VERSION ""

NS_ :

BS_:

BU_: CHUD_LS VKM_LS RCRM_LS MSM_RR_LS MSM_LR_LS CGM_LS BSM_LS VPM_LS ISRVM_LS DCAC_LS TouchPad_LS RSC_LS LVMPC_LS EOCM2B_K1_LS EOCM2A_K1_LS LCM_LS TIM_B_LS V2V_LS TCP_LS CSM_LS EOCM2B_K2_LS EOCM2A_K2_LS TIM_A_LS LVMNav_LS HFP_LS EDI_LS ARB_LS RSE_LS Dummy_LS VIS2_LS ICS_LS FCM_LS EOCM_F_LS VICM_LS AGC_LS MSM_P_LS OTIM_LS HVSM_R_LS HVSM_F_LS DVB_T_LS SBZA_R_LS PSD_R_LS PSD_L_LS UHP_Low UPA_LS STC_LS SBZA_L_LS PTM_LS ONSTAR_LS APA_LS TestTool_LS PHS_LS PDIM_LS CHM_LS RSA_LS AMP_LS HUD_LS MSM_LS HBSM_LS SCL_LS ECC_LS RadioHead_LS PEPS_LS IPC_LS AOS_LS SDM_LS TIM_LS BCM_LS

BO_ 2158936064 ODIEnumDynamicData_LS: 8 ECC_LS
 SG_ ODIEDD_Data18Value : 50|3@0+ (1,0) [0|7] ""  CSM_LS,CGM_LS,TCP_LS,OTIM_LS,ONSTAR_LS,IPC_LS,CHUD_LS,HUD_LS,RadioHead_LS
 SG_ ODIEDD_Data17Value : 53|3@0+ (1,0) [0|7] ""  CSM_LS,CGM_LS,TCP_LS,OTIM_LS,ONSTAR_LS,IPC_LS,CHUD_LS,HUD_LS,RadioHead_LS
 SG_ ODIEDD_Data16Value : 40|3@0+ (1,0) [0|7] ""  CSM_LS,CGM_LS,TCP_LS,OTIM_LS,ONSTAR_LS,IPC_LS,CHUD_LS,HUD_LS,RadioHead_LS
 SG_ ODIEDD_Data15Value : 43|3@0+ (1,0) [0|7] ""  CSM_LS,CGM_LS,TCP_LS,OTIM_LS,ONSTAR_LS,IPC_LS,CHUD_LS,HUD_LS,RadioHead_LS
 SG_ ODIEDD_Data14Value : 46|3@0+ (1,0) [0|7] ""  CSM_LS,CGM_LS,TCP_LS,OTIM_LS,ONSTAR_LS,IPC_LS,CHUD_LS,HUD_LS,RadioHead_LS
 SG_ ODIEDD_Data13Value : 33|3@0+ (1,0) [0|7] ""  CSM_LS,CGM_LS,TCP_LS,OTIM_LS,ONSTAR_LS,IPC_LS,CHUD_LS,HUD_LS,RadioHead_LS
 SG_ ODIEDD_Data12Value : 36|3@0+ (1,0) [0|7] ""  CSM_LS,CGM_LS,TCP_LS,OTIM_LS,ONSTAR_LS,IPC_LS,CHUD_LS,HUD_LS,RadioHead_LS
 SG_ ODIEDD_Data11Value : 39|3@0+ (1,0) [0|7] ""  CSM_LS,CGM_LS,TCP_LS,OTIM_LS,ONSTAR_LS,IPC_LS,CHUD_LS,HUD_LS,RadioHead_LS
 SG_ ODIEDD_Data10Value : 26|3@0+ (1,0) [0|7] ""  CSM_LS,CGM_LS,TCP_LS,OTIM_LS,ONSTAR_LS,IPC_LS,CHUD_LS,HUD_LS,RadioHead_LS
 SG_ ODIEDD_Data9Value : 29|3@0+ (1,0) [0|7] ""  CSM_LS,CGM_LS,TCP_LS,OTIM_LS,ONSTAR_LS,IPC_LS,CHUD_LS,HUD_LS,RadioHead_LS
 SG_ ODIEDD_Data8Value : 16|3@0+ (1,0) [0|7] ""  CSM_LS,CGM_LS,TCP_LS,OTIM_LS,ONSTAR_LS,IPC_LS,CHUD_LS,HUD_LS,RadioHead_LS
 SG_ ODIEDD_Data7Value : 19|3@0+ (1,0) [0|7] ""  CSM_LS,CGM_LS,TCP_LS,OTIM_LS,ONSTAR_LS,IPC_LS,CHUD_LS,HUD_LS,RadioHead_LS
 SG_ ODIEDD_Data6Value : 22|3@0+ (1,0) [0|7] ""  CSM_LS,CGM_LS,TCP_LS,OTIM_LS,ONSTAR_LS,IPC_LS,CHUD_LS,HUD_LS,RadioHead_LS
 SG_ ODIEDD_Data5Value : 9|3@0+ (1,0) [0|7] ""  CSM_LS,CGM_LS,TCP_LS,OTIM_LS,ONSTAR_LS,IPC_LS,CHUD_LS,HUD_LS,RadioHead_LS
 SG_ ODIEDD_Data4Value : 12|3@0+ (1,0) [0|7] ""  CSM_LS,CGM_LS,TCP_LS,OTIM_LS,ONSTAR_LS,IPC_LS,CHUD_LS,HUD_LS,RadioHead_LS
 SG_ ODIEDD_Data3Value : 15|3@0+ (1,0) [0|7] ""  CSM_LS,CGM_LS,TCP_LS,OTIM_LS,ONSTAR_LS,IPC_LS,CHUD_LS,HUD_LS,RadioHead_LS
 SG_ ODIEDD_Data2Value : 2|3@0+ (1,0) [0|7] ""  CSM_LS,CGM_LS,TCP_LS,OTIM_LS,ONSTAR_LS,IPC_LS,CHUD_LS,HUD_LS,RadioHead_LS
 SG_ ODIEDD_Data1Value : 5|3@0+ (1,0) [0|7] ""  CSM_LS,CGM_LS,TCP_LS,OTIM_LS,ONSTAR_LS,IPC_LS,CHUD_LS,HUD_LS,RadioHead_LS
 SG_ ODIEDD_FUCID : 63|8@0+ (1,0) [0|255] ""  CSM_LS,CGM_LS,TCP_LS,OTIM_LS,ONSTAR_LS,IPC_LS,CHUD_LS,HUD_LS,RadioHead_LS

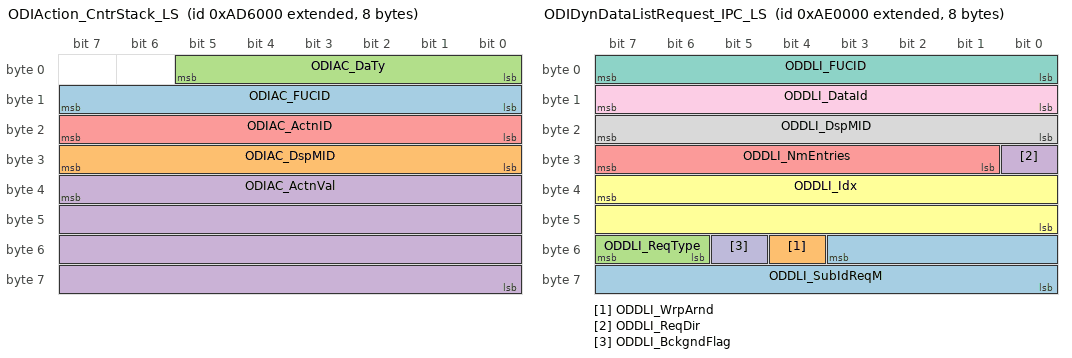
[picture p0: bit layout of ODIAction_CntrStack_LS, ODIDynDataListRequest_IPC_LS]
BO_ 2158845952 ODIAction_CntrStack_LS: 8 CGM_LS
 SG_ ODIAC_FUCID : 15|8@0+ (1,0) [0|255] ""  EOCM2B_K2_LS,EOCM2A_K2_LS,TCP_LS,SBZA_L_LS,VIS2_LS,FCM_LS,PDIM_LS,EOCM_F_LS,UPA_LS,BCM_LS,ECC_LS,MSM_P_LS,MSM_LS,APA_LS,UHP_Low,ONSTAR_LS
 SG_ ODIAC_DspMID : 31|8@0+ (1,0) [0|255] ""  EOCM2B_K2_LS,EOCM2A_K2_LS,TCP_LS,SBZA_L_LS,VIS2_LS,FCM_LS,PDIM_LS,EOCM_F_LS,UPA_LS,BCM_LS,ECC_LS,MSM_P_LS,MSM_LS,APA_LS,UHP_Low,ONSTAR_LS
 SG_ ODIAC_DaTy : 5|6@0+ (1,0) [0|63] ""  EOCM2B_K2_LS,EOCM2A_K2_LS,TCP_LS,SBZA_L_LS,VIS2_LS,FCM_LS,PDIM_LS,EOCM_F_LS,UPA_LS,BCM_LS,ECC_LS,MSM_P_LS,MSM_LS,APA_LS,UHP_Low,ONSTAR_LS
 SG_ ODIAC_ActnVal : 39|32@0+ (1,0) [0|4294967295] ""  EOCM2B_K2_LS,EOCM2A_K2_LS,TCP_LS,SBZA_L_LS,VIS2_LS,FCM_LS,PDIM_LS,EOCM_F_LS,UPA_LS,BCM_LS,ECC_LS,MSM_P_LS,MSM_LS,APA_LS,UHP_Low,ONSTAR_LS
 SG_ ODIAC_ActnID : 23|8@0+ (1,0) [0|255] ""  EOCM2B_K2_LS,EOCM2A_K2_LS,TCP_LS,SBZA_L_LS,VIS2_LS,FCM_LS,PDIM_LS,EOCM_F_LS,UPA_LS,BCM_LS,ECC_LS,MSM_P_LS,MSM_LS,APA_LS,UHP_Low,ONSTAR_LS

BO_ 2158886912 ODIDynDataListRequest_IPC_LS: 8 IPC_LS
 SG_ ODDLI_SubIdReqM : 51|12@0+ (1,0) [0|4095] ""  TCP_LS,VIS2_LS,FCM_LS,RadioHead_LS,UHP_Low,ONSTAR_LS
 SG_ ODDLI_WrpArnd : 52|1@0+ (1,0) [0|1] ""  TCP_LS,VIS2_LS,FCM_LS,RadioHead_LS,UHP_Low,ONSTAR_LS
 SG_ ODDLI_ReqType : 55|2@0+ (1,0) [0|3] ""  TCP_LS,VIS2_LS,FCM_LS,RadioHead_LS,UHP_Low,ONSTAR_LS
 SG_ ODDLI_ReqDir : 24|1@0+ (1,0) [0|1] ""  TCP_LS,VIS2_LS,FCM_LS,RadioHead_LS,UHP_Low,ONSTAR_LS
 SG_ ODDLI_NmEntries : 31|7@0+ (1,0) [0|127] ""  TCP_LS,VIS2_LS,FCM_LS,RadioHead_LS,UHP_Low,ONSTAR_LS
 SG_ ODDLI_Idx : 39|16@0+ (1,0) [0|65535] ""  TCP_LS,VIS2_LS,FCM_LS,RadioHead_LS,UHP_Low,ONSTAR_LS
 SG_ ODDLI_FUCID : 7|8@0+ (1,0) [0|255] ""  TCP_LS,VIS2_LS,FCM_LS,RadioHead_LS,UHP_Low,ONSTAR_LS
 SG_ ODDLI_DspMID : 23|8@0+ (1,0) [0|255] ""  TCP_LS,VIS2_LS,FCM_LS,RadioHead_LS,UHP_Low,ONSTAR_LS
 SG_ ODDLI_DataId : 15|8@0+ (1,0) [0|255] ""  TCP_LS,VIS2_LS,FCM_LS,RadioHead_LS,UHP_Low,ONSTAR_LS
 SG_ ODDLI_BckgndFlag : 53|1@0+ (1,0) [0|1] ""  TCP_LS,VIS2_LS,FCM_LS,RadioHead_LS,UHP_Low,ONSTAR_LS

BO_ 1596 VNMF_LS_63C_SCL: 8 SCL_LS
 SG_ VectraSpcNWMgtD : 7|64@0+ (1,0) [0|1.84467440737096E+019] ""  TCP_LS,LVMNav_LS,UHP_Low,ONSTAR_LS,TIM_B_LS,RSE_LS,RSA_LS,HVSM_F_LS,MSM_LS,BCM_LS,AOS_LS,AMP_LS,BSM_LS,VICM_LS,HFP_LS,PDIM_LS,SBZA_R_LS,TestTool_LS,MSM_LR_LS,LCM_LS,HVSM_R_LS,EOCM2A_K2_LS,FCM_LS,EOCM_F_LS,EOCM2B_K2_LS,PHS_LS,ICS_LS,CGM_LS,TIM_LS,SBZA_L_LS,CSM_LS,CHM_LS,RadioHead_LS,STC_LS,PTM_LS,VKM_LS,RSC_LS,PSD_R_LS,DCAC_LS,AGC_LS,TIM_A_LS,VIS2_LS,SDM_LS,CHUD_LS,MSM_RR_LS,LVMPC_LS,PSD_L_LS,PEPS_LS,IPC_LS,VPM_LS,HUD_LS,RCRM_LS,ISRVM_LS,HBSM_LS,ECC_LS,TouchPad_LS,DVB_T_LS,UPA_LS,APA_LS,V2V_LS,ARB_LS,MSM_P_LS,OTIM_LS

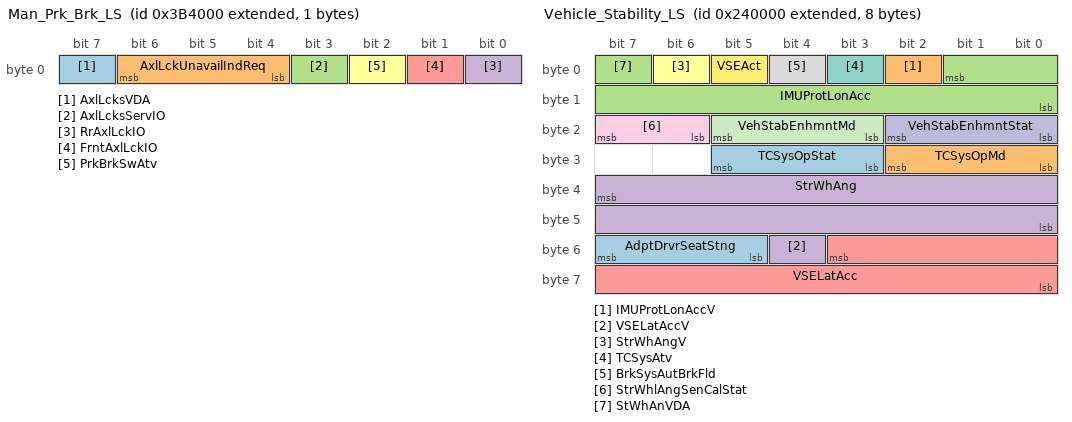
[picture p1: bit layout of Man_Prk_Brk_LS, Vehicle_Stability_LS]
BO_ 2151366656 Man_Prk_Brk_LS: 1 BCM_LS
 SG_ AxlLcksVDA : 7|1@0+ (1,0) [0|1] ""  CGM_LS,IPC_LS
 SG_ AxlLckUnavailIndReq : 6|3@0+ (1,0) [0|7] ""  CGM_LS,IPC_LS
 SG_ AxlLcksServIO : 3|1@0+ (1,0) [0|1] ""  CGM_LS,IPC_LS
 SG_ RrAxlLckIO : 0|1@0+ (1,0) [0|1] ""  CGM_LS,IPC_LS
 SG_ FrntAxlLckIO : 1|1@0+ (1,0) [0|1] ""  CGM_LS,IPC_LS
 SG_ PrkBrkSwAtv : 2|1@0+ (1,0) [0|1] ""  ONSTAR_LS,TCP_LS,CSM_LS,MSM_P_LS,MSM_LS,V2V_LS,CGM_LS,RadioHead_LS,SBZA_R_LS,LVMNav_LS,SBZA_L_LS,IPC_LS,UPA_LS,APA_LS

BO_ 2149842944 Vehicle_Stability_LS: 8 BCM_LS
 SG_ AdptDrvrSeatStng : 55|3@0+ (1,0) [0|7] ""  CGM_LS,MSM_LS
 SG_ IMUProtLonAccV : 2|1@0+ (1,0) [0|1] ""  CSM_LS,VIS2_LS,UPA_LS,APA_LS,FCM_LS,RadioHead_LS,IPC_LS,LCM_LS,PTM_LS,CGM_LS
 SG_ IMUProtLonAcc : 1|10@0- (0.03,0) [-15.36|15.33] "m/s^2"  CSM_LS,VIS2_LS,UPA_LS,APA_LS,FCM_LS,RadioHead_LS,IPC_LS,LCM_LS,PTM_LS,CGM_LS
 SG_ VSELatAccV : 52|1@0+ (1,0) [0|1] ""  CGM_LS,CSM_LS,VIS2_LS,RadioHead_LS,CHUD_LS,HUD_LS,IPC_LS,FCM_LS
 SG_ VSELatAcc : 51|12@0- (0.015625,0) [-32|31.984375] "m/s^2"  CGM_LS,CSM_LS,VIS2_LS,RadioHead_LS,CHUD_LS,HUD_LS,IPC_LS,FCM_LS
 SG_ StrWhAngV : 6|1@0+ (1,0) [0|1] ""  CGM_LS,VIS2_LS,VPM_LS,SBZA_R_LS,SBZA_L_LS,FCM_LS,UPA_LS,APA_LS,CSM_LS,RadioHead_LS
 SG_ TCSysAtv : 3|1@0+ (1,0) [0|1] ""  CSM_LS,CGM_LS,VIS2_LS,RadioHead_LS,APA_LS,FCM_LS,IPC_LS
 SG_ BrkSysAutBrkFld : 4|1@0+ (1,0) [0|1] ""  CSM_LS,CGM_LS,RadioHead_LS,IPC_LS
 SG_ StrWhlAngSenCalStat : 23|2@0+ (1,0) [0|3] ""  CGM_LS,VPM_LS,VIS2_LS,FCM_LS,CSM_LS,RadioHead_LS,UPA_LS,APA_LS
 SG_ VehStabEnhmntStat : 18|3@0+ (1,0) [0|7] ""  CSM_LS,CGM_LS,RadioHead_LS,APA_LS,IPC_LS
 SG_ VehStabEnhmntMd : 21|3@0+ (1,0) [0|7] ""  CSM_LS,CGM_LS,RadioHead_LS,IPC_LS
 SG_ VSEAct : 5|1@0+ (1,0) [0|1] ""  CGM_LS,CSM_LS,VIS2_LS,EOCM_F_LS,RadioHead_LS,FCM_LS,APA_LS,IPC_LS
 SG_ TCSysOpStat : 29|3@0+ (1,0) [0|7] ""  CSM_LS,CGM_LS,RadioHead_LS,APA_LS,IPC_LS
 SG_ TCSysOpMd : 26|3@0+ (1,0) [0|7] ""  CSM_LS,CGM_LS,RadioHead_LS,IPC_LS
 SG_ StWhAnVDA : 7|1@0+ (1,0) [0|1] ""  CGM_LS,VIS2_LS,VPM_LS,UPA_LS,APA_LS,FCM_LS,CSM_LS,RadioHead_LS
 SG_ StrWhAng : 39|16@0- (0.0625,0) [-2048|2047.9375] "deg"  CGM_LS,VIS2_LS,VPM_LS,SBZA_R_LS,SBZA_L_LS,CSM_LS,RadioHead_LS,FCM_LS,UPA_LS,APA_LS

BO_ 1603 USDT_Resp_From_AGC_LS: 8 AGC_LS
 SG_ DgnInf : 7|64@0+ (1,0) [0|1.84467440737096E+019] ""  CSM_LS,CGM_LS,TCP_LS,ONSTAR_LS,TestTool_LS

BO_ 1574 VNMF_LS_626_ICS: 8 ICS_LS
 SG_ VectraSpcNWMgtD : 7|64@0+ (1,0) [0|1.84467440737096E+019] ""  HFP_LS,PDIM_LS,TCP_LS,LVMNav_LS,UHP_Low,ONSTAR_LS,TIM_B_LS,RSE_LS,RSA_LS,HVSM_F_LS,MSM_LS,BCM_LS,AOS_LS,AMP_LS,BSM_LS,VICM_LS,SBZA_R_LS,V2V_LS,ARB_LS,CGM_LS,TIM_LS,TestTool_LS,TIM_A_LS,VIS2_LS,SDM_LS,SCL_LS,SBZA_L_LS,CSM_LS,CHM_LS,RadioHead_LS,STC_LS,PTM_LS,VKM_LS,RSC_LS,PSD_R_LS,CHUD_LS,MSM_RR_LS,LVMPC_LS,PSD_L_LS,PEPS_LS,EOCM2A_K2_LS,FCM_LS,EOCM_F_LS,IPC_LS,MSM_LR_LS,LCM_LS,HVSM_R_LS,VPM_LS,HUD_LS,RCRM_LS,ISRVM_LS,HBSM_LS,ECC_LS,TouchPad_LS,DVB_T_LS,UPA_LS,APA_LS,DCAC_LS,AGC_LS,MSM_P_LS,OTIM_LS,EOCM2B_K2_LS,PHS_LS

BO_ 1571 VNMF_LS_623_AGC: 8 AGC_LS
 SG_ VectraSpcNWMgtD : 7|64@0+ (1,0) [0|1.84467440737096E+019] ""  TCP_LS,LVMNav_LS,UHP_Low,ONSTAR_LS,TIM_B_LS,RSE_LS,RSA_LS,HVSM_F_LS,MSM_LS,BCM_LS,AOS_LS,AMP_LS,BSM_LS,VICM_LS,HFP_LS,PDIM_LS,SBZA_R_LS,V2V_LS,ARB_LS,CGM_LS,TIM_LS,TestTool_LS,TIM_A_LS,VIS2_LS,SDM_LS,SCL_LS,SBZA_L_LS,CSM_LS,CHM_LS,RadioHead_LS,STC_LS,PTM_LS,VKM_LS,RSC_LS,PSD_R_LS,CHUD_LS,MSM_RR_LS,LVMPC_LS,PSD_L_LS,PEPS_LS,EOCM2A_K2_LS,FCM_LS,EOCM_F_LS,IPC_LS,MSM_LR_LS,LCM_LS,HVSM_R_LS,VPM_LS,HUD_LS,RCRM_LS,ISRVM_LS,HBSM_LS,ECC_LS,TouchPad_LS,DVB_T_LS,UPA_LS,APA_LS,ICS_LS,MSM_P_LS,OTIM_LS,EOCM2B_K2_LS,PHS_LS

BO_ 1347 UUDT_Resp_From_AGC_LS: 8 AGC_LS
 SG_ DgnInf_LS543 : 7|64@0+ (1,0) [0|1.84467440737096E+019] ""  CSM_LS,CGM_LS,TCP_LS,ONSTAR_LS,TestTool_LS

BO_ 582 USDT_Req_to_ICS_LS: 8 TestTool_LS
 SG_ DgnInf : 7|64@0+ (1,0) [0|1.84467440737096E+019] ""  TCP_LS,ONSTAR_LS,CGM_LS,ICS_LS

BO_ 579 USDT_Req_to_AGC_LS: 8 CGM_LS
 SG_ DgnInf : 7|64@0+ (1,0) [0|1.84467440737096E+019] ""  CGM_LS,TCP_LS,ONSTAR_LS,DCAC_LS,AGC_LS

BO_ 1577 VNMF_LS_629_OTIM_MSM_P: 8 OTIM_LS
 SG_ VectraSpcNWMgtD : 7|64@0+ (1,0) [0|1.84467440737096E+019] ""  TCP_LS,LVMNav_LS,UHP_Low,ONSTAR_LS,TIM_B_LS,RSE_LS,RSA_LS,HVSM_F_LS,MSM_LS,BCM_LS,AOS_LS,AMP_LS,BSM_LS,VICM_LS,HFP_LS,PDIM_LS,SBZA_R_LS,V2V_LS,ARB_LS,CGM_LS,TIM_LS,TestTool_LS,TIM_A_LS,VIS2_LS,SDM_LS,SCL_LS,SBZA_L_LS,CSM_LS,CHM_LS,RadioHead_LS,STC_LS,PTM_LS,VKM_LS,RSC_LS,PSD_R_LS,CHUD_LS,MSM_RR_LS,LVMPC_LS,PSD_L_LS,PEPS_LS,EOCM2A_K2_LS,FCM_LS,EOCM_F_LS,IPC_LS,MSM_LR_LS,LCM_LS,HVSM_R_LS,VPM_LS,HUD_LS,RCRM_LS,ISRVM_LS,HBSM_LS,ECC_LS,TouchPad_LS,DVB_T_LS,UPA_LS,APA_LS,DCAC_LS,AGC_LS,ICS_LS,EOCM2B_K2_LS,PHS_LS

BO_ 1609 USDT_Resp_From_OTIM_MSM_P_LS: 8 OTIM_LS
 SG_ DgnInf : 7|64@0+ (1,0) [0|1.84467440737096E+019] ""  CSM_LS,CGM_LS,TCP_LS,ONSTAR_LS,TestTool_LS

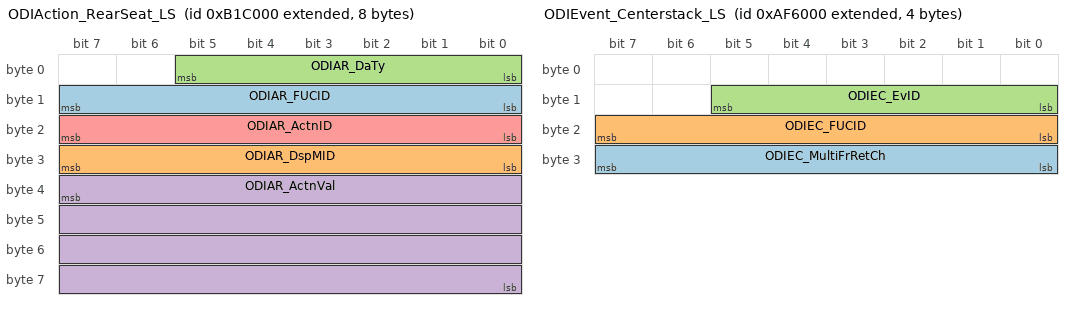
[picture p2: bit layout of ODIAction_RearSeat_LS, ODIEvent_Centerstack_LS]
BO_ 2159132672 ODIAction_RearSeat_LS: 8 RSA_LS
 SG_ ODIAR_FUCID : 15|8@0+ (1,0) [0|255] ""  ECC_LS,CSM_LS,RadioHead_LS
 SG_ ODIAR_DspMID : 31|8@0+ (1,0) [0|255] ""  ECC_LS,CSM_LS,RadioHead_LS
 SG_ ODIAR_DaTy : 5|6@0+ (1,0) [0|63] ""  ECC_LS,CSM_LS,RadioHead_LS
 SG_ ODIAR_ActnVal : 39|32@0+ (1,0) [0|4294967295] ""  ECC_LS,CSM_LS,RadioHead_LS
 SG_ ODIAR_ActnID : 23|8@0+ (1,0) [0|255] ""  ECC_LS,CSM_LS,RadioHead_LS

BO_ 2158968832 ODI_RearSeat_2_Centerstack_LS: 8 RSA_LS
 SG_ ODI_RSD2CntrStck : 7|64@0+ (1,0) [0|1.84467440737096E+019] ""  CGM_LS,CSM_LS,RadioHead_LS

BO_ 2158960640 ODIIndication_Centerstack_LS: 8 RadioHead_LS
 SG_ ODIIC_FUCID : 7|8@0+ (1,0) [0|255] ""  CGM_LS,CHUD_LS,HUD_LS,RSC_LS,RSA_LS
 SG_ ODIIC_ODIInd9 : 23|1@0+ (1,0) [0|1] ""  CGM_LS,CHUD_LS,HUD_LS,RSC_LS,RSA_LS
 SG_ ODIIC_ODIInd8 : 8|1@0+ (1,0) [0|1] ""  CGM_LS,CHUD_LS,HUD_LS,RSC_LS,RSA_LS
 SG_ ODIIC_ODIInd7 : 9|1@0+ (1,0) [0|1] ""  CGM_LS,CHUD_LS,HUD_LS,RSC_LS,RSA_LS
 SG_ ODIIC_ODIInd6 : 10|1@0+ (1,0) [0|1] ""  CGM_LS,CHUD_LS,HUD_LS,RSC_LS,RSA_LS
 SG_ ODIIC_ODIInd56 : 56|1@0+ (1,0) [0|1] ""  CGM_LS,CHUD_LS,HUD_LS,RSC_LS,RSA_LS
 SG_ ODIIC_ODIInd55 : 57|1@0+ (1,0) [0|1] ""  CGM_LS,CHUD_LS,HUD_LS,RSC_LS,RSA_LS
 SG_ ODIIC_ODIInd54 : 58|1@0+ (1,0) [0|1] ""  CGM_LS,CHUD_LS,HUD_LS,RSC_LS,RSA_LS
 SG_ ODIIC_ODIInd53 : 59|1@0+ (1,0) [0|1] ""  CGM_LS,CHUD_LS,HUD_LS,RSC_LS,RSA_LS
 SG_ ODIIC_ODIInd52 : 60|1@0+ (1,0) [0|1] ""  CGM_LS,CHUD_LS,HUD_LS,RSC_LS,RSA_LS
 SG_ ODIIC_ODIInd51 : 61|1@0+ (1,0) [0|1] ""  CGM_LS,CHUD_LS,HUD_LS,RSC_LS,RSA_LS
 SG_ ODIIC_ODIInd50 : 62|1@0+ (1,0) [0|1] ""  CGM_LS,CHUD_LS,HUD_LS,RSC_LS,RSA_LS
 SG_ ODIIC_ODIInd5 : 11|1@0+ (1,0) [0|1] ""  CGM_LS,CHUD_LS,HUD_LS,RSC_LS,RSA_LS
 SG_ ODIIC_ODIInd49 : 63|1@0+ (1,0) [0|1] ""  CGM_LS,CHUD_LS,HUD_LS,RSC_LS,RSA_LS
 SG_ ODIIC_ODIInd48 : 48|1@0+ (1,0) [0|1] ""  CGM_LS,CHUD_LS,HUD_LS,RSC_LS,RSA_LS
 SG_ ODIIC_ODIInd47 : 49|1@0+ (1,0) [0|1] ""  CGM_LS,CHUD_LS,HUD_LS,RSC_LS,RSA_LS
 SG_ ODIIC_ODIInd46 : 50|1@0+ (1,0) [0|1] ""  CGM_LS,CHUD_LS,HUD_LS,RSC_LS,RSA_LS
 SG_ ODIIC_ODIInd45 : 51|1@0+ (1,0) [0|1] ""  CGM_LS,CHUD_LS,HUD_LS,RSC_LS,RSA_LS
 SG_ ODIIC_ODIInd44 : 52|1@0+ (1,0) [0|1] ""  CGM_LS,CHUD_LS,HUD_LS,RSC_LS,RSA_LS
 SG_ ODIIC_ODIInd43 : 53|1@0+ (1,0) [0|1] ""  CGM_LS,CHUD_LS,HUD_LS,RSC_LS,RSA_LS
 SG_ ODIIC_ODIInd42 : 54|1@0+ (1,0) [0|1] ""  CGM_LS,CHUD_LS,HUD_LS,RSC_LS,RSA_LS
 SG_ ODIIC_ODIInd41 : 55|1@0+ (1,0) [0|1] ""  CGM_LS,CHUD_LS,HUD_LS,RSC_LS,RSA_LS
 SG_ ODIIC_ODIInd40 : 40|1@0+ (1,0) [0|1] ""  CGM_LS,CHUD_LS,HUD_LS,RSC_LS,RSA_LS
 SG_ ODIIC_ODIInd4 : 12|1@0+ (1,0) [0|1] ""  CGM_LS,CHUD_LS,HUD_LS,RSC_LS,RSA_LS
 SG_ ODIIC_ODIInd39 : 41|1@0+ (1,0) [0|1] ""  CGM_LS,CHUD_LS,HUD_LS,RSC_LS,RSA_LS
 SG_ ODIIC_ODIInd38 : 42|1@0+ (1,0) [0|1] ""  CGM_LS,CHUD_LS,HUD_LS,RSC_LS,RSA_LS
 SG_ ODIIC_ODIInd37 : 43|1@0+ (1,0) [0|1] ""  CGM_LS,CHUD_LS,HUD_LS,RSC_LS,RSA_LS
 SG_ ODIIC_ODIInd36 : 44|1@0+ (1,0) [0|1] ""  CGM_LS,CHUD_LS,HUD_LS,RSC_LS,RSA_LS
 SG_ ODIIC_ODIInd35 : 45|1@0+ (1,0) [0|1] ""  CGM_LS,CHUD_LS,HUD_LS,RSC_LS,RSA_LS
 SG_ ODIIC_ODIInd34 : 46|1@0+ (1,0) [0|1] ""  CGM_LS,CHUD_LS,HUD_LS,RSC_LS,RSA_LS
 SG_ ODIIC_ODIInd33 : 47|1@0+ (1,0) [0|1] ""  CGM_LS,CHUD_LS,HUD_LS,RSC_LS,RSA_LS
 SG_ ODIIC_ODIInd32 : 32|1@0+ (1,0) [0|1] ""  CGM_LS,CHUD_LS,HUD_LS,RSC_LS,RSA_LS
 SG_ ODIIC_ODIInd31 : 33|1@0+ (1,0) [0|1] ""  CGM_LS,CHUD_LS,HUD_LS,RSC_LS,RSA_LS
 SG_ ODIIC_ODIInd30 : 34|1@0+ (1,0) [0|1] ""  CGM_LS,CHUD_LS,HUD_LS,RSC_LS,RSA_LS
 SG_ ODIIC_ODIInd3 : 13|1@0+ (1,0) [0|1] ""  CGM_LS,CHUD_LS,HUD_LS,RSC_LS,RSA_LS
 SG_ ODIIC_ODIInd29 : 35|1@0+ (1,0) [0|1] ""  CGM_LS,CHUD_LS,HUD_LS,RSC_LS,RSA_LS
 SG_ ODIIC_ODIInd28 : 36|1@0+ (1,0) [0|1] ""  CGM_LS,CHUD_LS,HUD_LS,RSC_LS,RSA_LS
 SG_ ODIIC_ODIInd27 : 37|1@0+ (1,0) [0|1] ""  CGM_LS,CHUD_LS,HUD_LS,RSC_LS,RSA_LS
 SG_ ODIIC_ODIInd26 : 38|1@0+ (1,0) [0|1] ""  CGM_LS,CHUD_LS,HUD_LS,RSC_LS,RSA_LS
 SG_ ODIIC_ODIInd25 : 39|1@0+ (1,0) [0|1] ""  CGM_LS,CHUD_LS,HUD_LS,RSC_LS,RSA_LS
 SG_ ODIIC_ODIInd24 : 24|1@0+ (1,0) [0|1] ""  CGM_LS,CHUD_LS,HUD_LS,RSC_LS,RSA_LS
 SG_ ODIIC_ODIInd23 : 25|1@0+ (1,0) [0|1] ""  CGM_LS,CHUD_LS,HUD_LS,RSC_LS,RSA_LS
 SG_ ODIIC_ODIInd22 : 26|1@0+ (1,0) [0|1] ""  CGM_LS,CHUD_LS,HUD_LS,RSC_LS,RSA_LS
 SG_ ODIIC_ODIInd21 : 27|1@0+ (1,0) [0|1] ""  CGM_LS,CHUD_LS,HUD_LS,RSC_LS,RSA_LS
 SG_ ODIIC_ODIInd20 : 28|1@0+ (1,0) [0|1] ""  CGM_LS,CHUD_LS,HUD_LS,RSC_LS,RSA_LS
 SG_ ODIIC_ODIInd2 : 14|1@0+ (1,0) [0|1] ""  CGM_LS,CHUD_LS,HUD_LS,RSC_LS,RSA_LS
 SG_ ODIIC_ODIInd19 : 29|1@0+ (1,0) [0|1] ""  CGM_LS,CHUD_LS,HUD_LS,RSC_LS,RSA_LS
 SG_ ODIIC_ODIInd18 : 30|1@0+ (1,0) [0|1] ""  CGM_LS,CHUD_LS,HUD_LS,RSC_LS,RSA_LS
 SG_ ODIIC_ODIInd17 : 31|1@0+ (1,0) [0|1] ""  CGM_LS,CHUD_LS,HUD_LS,RSC_LS,RSA_LS
 SG_ ODIIC_ODIInd16 : 16|1@0+ (1,0) [0|1] ""  CGM_LS,CHUD_LS,HUD_LS,RSC_LS,RSA_LS
 SG_ ODIIC_ODIInd15 : 17|1@0+ (1,0) [0|1] ""  CGM_LS,CHUD_LS,HUD_LS,RSC_LS,RSA_LS
 SG_ ODIIC_ODIInd14 : 18|1@0+ (1,0) [0|1] ""  CGM_LS,CHUD_LS,HUD_LS,RSC_LS,RSA_LS
 SG_ ODIIC_ODIInd13 : 19|1@0+ (1,0) [0|1] ""  CGM_LS,CHUD_LS,HUD_LS,RSC_LS,RSA_LS
 SG_ ODIIC_ODIInd12 : 20|1@0+ (1,0) [0|1] ""  CGM_LS,CHUD_LS,HUD_LS,RSC_LS,RSA_LS
 SG_ ODIIC_ODIInd11 : 21|1@0+ (1,0) [0|1] ""  CGM_LS,CHUD_LS,HUD_LS,RSC_LS,RSA_LS
 SG_ ODIIC_ODIInd10 : 22|1@0+ (1,0) [0|1] ""  CGM_LS,CHUD_LS,HUD_LS,RSC_LS,RSA_LS
 SG_ ODIIC_ODIInd1 : 15|1@0+ (1,0) [0|1] ""  CGM_LS,CHUD_LS,HUD_LS,RSC_LS,RSA_LS

BO_ 2158977024 ODIEvent_Centerstack_LS: 4 RadioHead_LS
 SG_ ODIEC_MultiFrRetCh : 31|8@0+ (1,0) [0|255] ""  CGM_LS,CHUD_LS,HUD_LS,RSC_LS,RSA_LS
 SG_ ODIEC_FUCID : 23|8@0+ (1,0) [0|255] ""  CGM_LS,CHUD_LS,HUD_LS,RSC_LS,RSA_LS
 SG_ ODIEC_EvID : 13|6@0+ (1,0) [0|63] ""  CGM_LS,CHUD_LS,HUD_LS,RSC_LS,RSA_LS

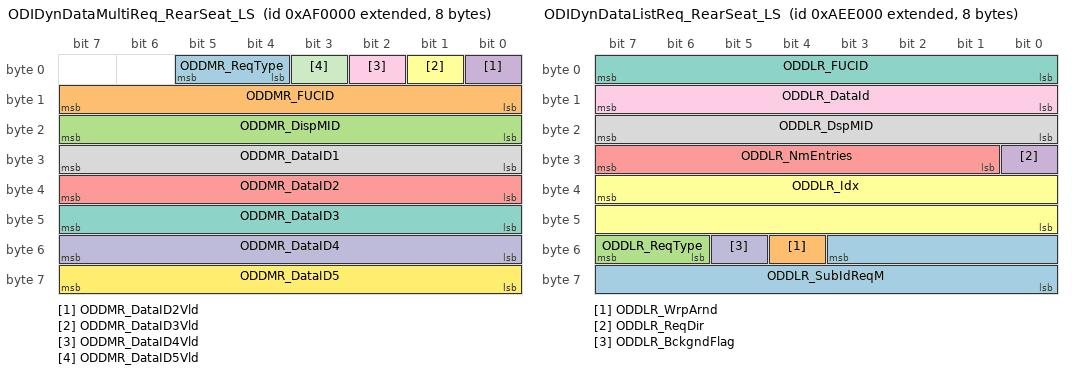
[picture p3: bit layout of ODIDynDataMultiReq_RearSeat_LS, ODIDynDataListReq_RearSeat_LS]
BO_ 2158952448 ODIDynDataMultiReq_RearSeat_LS: 8 RSA_LS
 SG_ ODDMR_ReqType : 5|2@0+ (1,0) [0|3] ""  ECC_LS,CSM_LS,RadioHead_LS
 SG_ ODDMR_FUCID : 15|8@0+ (1,0) [0|255] ""  ECC_LS,CSM_LS,RadioHead_LS
 SG_ ODDMR_DispMID : 23|8@0+ (1,0) [0|255] ""  ECC_LS,CSM_LS,RadioHead_LS
 SG_ ODDMR_DataID2Vld : 0|1@0+ (1,0) [0|1] ""  ECC_LS,CSM_LS,RadioHead_LS
 SG_ ODDMR_DataID2 : 39|8@0+ (1,0) [0|255] ""  ECC_LS,CSM_LS,RadioHead_LS
 SG_ ODDMR_DataID3Vld : 1|1@0+ (1,0) [0|1] ""  ECC_LS,CSM_LS,RadioHead_LS
 SG_ ODDMR_DataID3 : 47|8@0+ (1,0) [0|255] ""  ECC_LS,CSM_LS,RadioHead_LS
 SG_ ODDMR_DataID1 : 31|8@0+ (1,0) [0|255] ""  ECC_LS,CSM_LS,RadioHead_LS
 SG_ ODDMR_DataID4Vld : 2|1@0+ (1,0) [0|1] ""  ECC_LS,CSM_LS,RadioHead_LS
 SG_ ODDMR_DataID4 : 55|8@0+ (1,0) [0|255] ""  ECC_LS,CSM_LS,RadioHead_LS
 SG_ ODDMR_DataID5Vld : 3|1@0+ (1,0) [0|1] ""  ECC_LS,CSM_LS,RadioHead_LS
 SG_ ODDMR_DataID5 : 63|8@0+ (1,0) [0|255] ""  ECC_LS,CSM_LS,RadioHead_LS

BO_ 2158944256 ODIDynDataListReq_RearSeat_LS: 8 RSA_LS
 SG_ ODDLR_SubIdReqM : 51|12@0+ (1,0) [0|4095] ""  CGM_LS,CSM_LS,RadioHead_LS
 SG_ ODDLR_WrpArnd : 52|1@0+ (1,0) [0|1] ""  CGM_LS,CSM_LS,RadioHead_LS
 SG_ ODDLR_ReqType : 55|2@0+ (1,0) [0|3] ""  CGM_LS,CSM_LS,RadioHead_LS
 SG_ ODDLR_ReqDir : 24|1@0+ (1,0) [0|1] ""  CGM_LS,CSM_LS,RadioHead_LS
 SG_ ODDLR_NmEntries : 31|7@0+ (1,0) [0|127] ""  CGM_LS,CSM_LS,RadioHead_LS
 SG_ ODDLR_Idx : 39|16@0+ (1,0) [0|65535] ""  CGM_LS,CSM_LS,RadioHead_LS
 SG_ ODDLR_FUCID : 7|8@0+ (1,0) [0|255] ""  CGM_LS,CSM_LS,RadioHead_LS
 SG_ ODDLR_DspMID : 23|8@0+ (1,0) [0|255] ""  CGM_LS,CSM_LS,RadioHead_LS
 SG_ ODDLR_DataId : 15|8@0+ (1,0) [0|255] ""  CGM_LS,CSM_LS,RadioHead_LS
 SG_ ODDLR_BckgndFlag : 53|1@0+ (1,0) [0|1] ""  CGM_LS,CSM_LS,RadioHead_LS

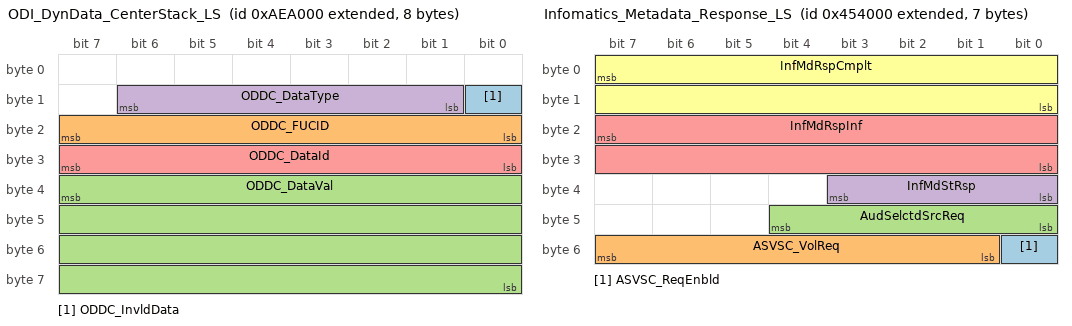
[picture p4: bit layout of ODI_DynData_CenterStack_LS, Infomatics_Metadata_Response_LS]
BO_ 2158927872 ODI_DynData_CenterStack_LS: 8 RadioHead_LS
 SG_ ODDC_InvldData : 8|1@0+ (1,0) [0|1] ""  CGM_LS,TCP_LS,ONSTAR_LS,RSC_LS,RSA_LS,CHUD_LS,HUD_LS
 SG_ ODDC_FUCID : 23|8@0+ (1,0) [0|255] ""  CGM_LS,TCP_LS,ONSTAR_LS,RSC_LS,RSA_LS,CHUD_LS,HUD_LS
 SG_ ODDC_DataVal : 39|32@0+ (1,0) [0|4294967295] ""  CGM_LS,TCP_LS,ONSTAR_LS,RSC_LS,RSA_LS,CHUD_LS,HUD_LS
 SG_ ODDC_DataType : 14|6@0+ (1,0) [0|63] ""  CGM_LS,TCP_LS,ONSTAR_LS,RSC_LS,RSA_LS,CHUD_LS,HUD_LS
 SG_ ODDC_DataId : 31|8@0+ (1,0) [0|255] ""  CGM_LS,TCP_LS,ONSTAR_LS,RSC_LS,RSA_LS,CHUD_LS,HUD_LS

BO_ 2158895104 ODI_CenterStack_2_RearSeat_LS: 8 RadioHead_LS
 SG_ ODI_CntrStck2RSD : 7|64@0+ (1,0) [0|1.84467440737096E+019] ""  CGM_LS,RSC_LS,RSA_LS

BO_ 2152038400 Infomatics_Response_Payload_LS: 8 ONSTAR_LS
 SG_ InfMdRspPld : 7|64@0+ (1,0) [0|1.84467440737096E+019] ""  CGM_LS,RadioHead_LS

BO_ 2152022016 Infomatics_Metadata_Response_LS: 7 ONSTAR_LS
 SG_ ASVSC_ReqEnbld : 48|1@0+ (1,0) [0|1] ""  CGM_LS,CSM_LS,RadioHead_LS
 SG_ ASVSC_VolReq : 55|7@0+ (0.787402,0) [0|100.000054] ""  CGM_LS,CSM_LS,RadioHead_LS
 SG_ AudSelctdSrcReq : 44|5@0+ (1,0) [0|31] ""  CGM_LS,CSM_LS,RadioHead_LS
 SG_ InfMdStRsp : 35|4@0+ (1,0) [0|15] ""  CGM_LS,RadioHead_LS
 SG_ InfMdRspInf : 23|16@0+ (1,0) [0|65535] ""  CGM_LS,RadioHead_LS
 SG_ InfMdRspCmplt : 7|16@0+ (1,0) [0|65535] ""  CGM_LS,RadioHead_LS

BO_ 2152005632 Infomatics_Request_Payload_LS: 8 RadioHead_LS
 SG_ InfMdRqstPld : 7|64@0+ (1,0) [0|1.84467440737096E+019] ""  CGM_LS,ONSTAR_LS

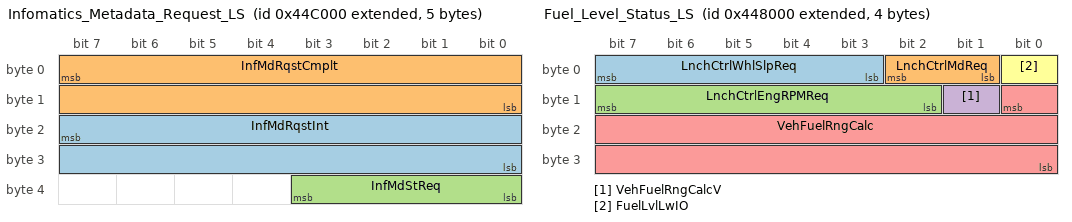
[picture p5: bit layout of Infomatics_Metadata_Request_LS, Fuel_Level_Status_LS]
BO_ 2151989248 Infomatics_Metadata_Request_LS: 5 RadioHead_LS
 SG_ InfMdRqstInt : 23|16@0+ (1,0) [0|65535] ""  CGM_LS,ONSTAR_LS
 SG_ InfMdRqstCmplt : 7|16@0+ (1,0) [0|65535] ""  CGM_LS,ONSTAR_LS
 SG_ InfMdStReq : 35|4@0+ (1,0) [0|15] ""  CGM_LS,ONSTAR_LS

BO_ 2151972864 Fuel_Level_Status_LS: 4 IPC_LS
 SG_ LnchCtrlWhlSlpReq : 7|5@0+ (1,0) [0|31] ""  BCM_LS
 SG_ LnchCtrlMdReq : 2|2@0+ (1,0) [0|3] ""  BCM_LS
 SG_ LnchCtrlEngRPMReq : 15|6@0+ (1,0) [0|63] ""  BCM_LS
 SG_ VehFuelRngCalcV : 9|1@0+ (1,0) [0|1] ""  RadioHead_LS
 SG_ VehFuelRngCalc : 8|17@0+ (0.015625,0) [0|2047.984375] "km"  RadioHead_LS
 SG_ FuelLvlLwIO : 0|1@0+ (1,0) [0|1] ""  LVMNav_LS,RadioHead_LS

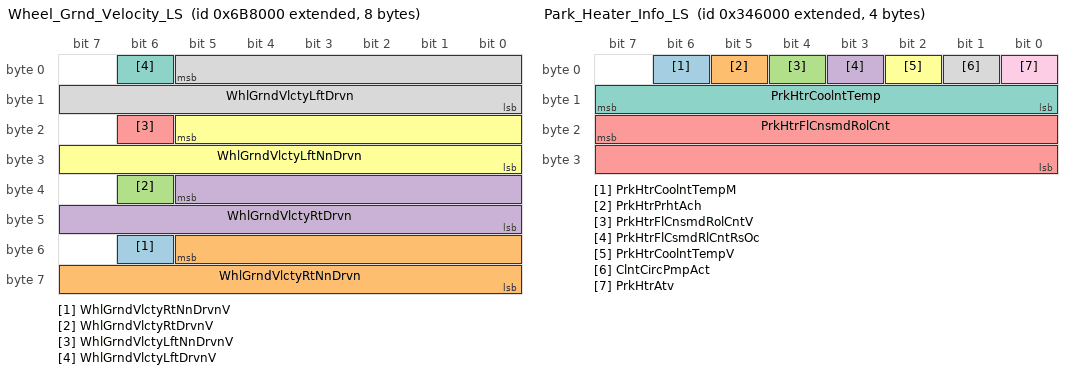
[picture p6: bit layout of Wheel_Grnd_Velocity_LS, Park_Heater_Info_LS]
BO_ 2154528768 Wheel_Grnd_Velocity_LS: 8 BCM_LS
 SG_ WhlGrndVlctyRtNnDrvnV : 54|1@0+ (1,0) [0|1] ""  CGM_LS,VPM_LS,SDM_LS,UPA_LS,FCM_LS,APA_LS,SCL_LS
 SG_ WhlGrndVlctyRtNnDrvn : 53|14@0+ (0.03125,0) [0|511.96875] "km / h"  CGM_LS,VPM_LS,SDM_LS,UPA_LS,FCM_LS,APA_LS,SCL_LS
 SG_ WhlGrndVlctyRtDrvnV : 38|1@0+ (1,0) [0|1] ""  CGM_LS,VPM_LS,SDM_LS,UPA_LS,FCM_LS,APA_LS,SCL_LS
 SG_ WhlGrndVlctyRtDrvn : 37|14@0+ (0.03125,0) [0|511.96875] "km / h"  CGM_LS,VPM_LS,SDM_LS,UPA_LS,FCM_LS,APA_LS,SCL_LS
 SG_ WhlGrndVlctyLftNnDrvnV : 22|1@0+ (1,0) [0|1] ""  CGM_LS,VPM_LS,SDM_LS,UPA_LS,FCM_LS,APA_LS,SCL_LS
 SG_ WhlGrndVlctyLftNnDrvn : 21|14@0+ (0.03125,0) [0|511.96875] "km / h"  CGM_LS,VPM_LS,SDM_LS,UPA_LS,FCM_LS,APA_LS,SCL_LS
 SG_ WhlGrndVlctyLftDrvnV : 6|1@0+ (1,0) [0|1] ""  CGM_LS,VPM_LS,SDM_LS,UPA_LS,FCM_LS,APA_LS,SCL_LS
 SG_ WhlGrndVlctyLftDrvn : 5|14@0+ (0.03125,0) [0|511.96875] "km / h"  CGM_LS,VPM_LS,SDM_LS,UPA_LS,FCM_LS,APA_LS,SCL_LS

BO_ 2150916096 Park_Heater_Info_LS: 4 PHS_LS
 SG_ PrkHtrCoolntTempM : 6|1@0+ (1,0) [0|1] ""  CGM_LS,BCM_LS
 SG_ PrkHtrPrhtAch : 5|1@0+ (1,0) [0|1] ""  CSM_LS,CGM_LS,RadioHead_LS,ECC_LS
 SG_ PrkHtrFlCnsmdRolCntV : 4|1@0+ (1,0) [0|1] ""  CSM_LS,CGM_LS,RadioHead_LS,IPC_LS
 SG_ PrkHtrFlCsmdRlCntRsOc : 3|1@0+ (1,0) [0|1] ""  CSM_LS,CGM_LS,RadioHead_LS,IPC_LS
 SG_ PrkHtrFlCnsmdRolCnt : 23|16@0+ (3.05176E-006,0) [0|0.1999970916] "liters"  CSM_LS,CGM_LS,RadioHead_LS,IPC_LS
 SG_ PrkHtrCoolntTempV : 2|1@0+ (1,0) [0|1] ""  BCM_LS,CSM_LS,CGM_LS,RadioHead_LS,ECC_LS
 SG_ PrkHtrCoolntTemp : 15|8@0+ (1,-40) [-40|215] "deg C"  BCM_LS,CSM_LS,CGM_LS,RadioHead_LS,ECC_LS
 SG_ ClntCircPmpAct : 1|1@0+ (1,0) [0|1] ""  CSM_LS,CGM_LS,RadioHead_LS,ECC_LS
 SG_ PrkHtrAtv : 0|1@0+ (1,0) [0|1] ""  CSM_LS,CGM_LS,RadioHead_LS,BCM_LS,ECC_LS

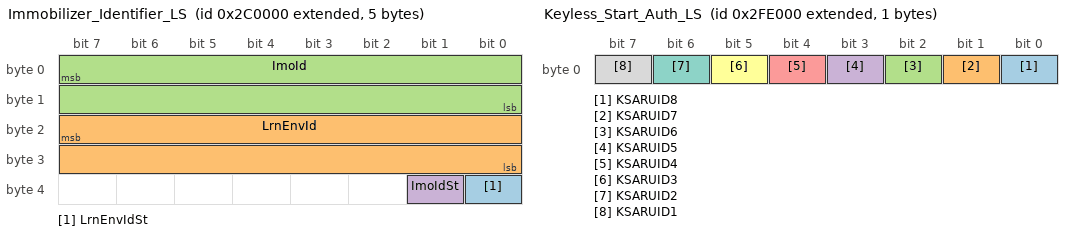
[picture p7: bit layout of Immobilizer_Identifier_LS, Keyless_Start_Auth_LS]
BO_ 2150367232 Immobilizer_Identifier_LS: 5 BCM_LS
 SG_ LrnEnvIdSt : 32|1@0+ (1,0) [0|1] ""  CGM_LS,IPC_LS,ECC_LS,SDM_LS
 SG_ LrnEnvId : 23|16@0+ (1,0) [0|65535] ""  CGM_LS,IPC_LS,ECC_LS,SDM_LS
 SG_ ImoId : 7|16@0+ (1,0) [0|65535] ""  V2V_LS,CGM_LS,IPC_LS,ECC_LS,SDM_LS
 SG_ ImoIdSt : 33|1@0+ (1,0) [0|1] ""  CGM_LS,IPC_LS,ECC_LS,SDM_LS

BO_ 2150621184 Keyless_Start_Auth_LS: 1 BCM_LS
 SG_ KSARUID8 : 0|1@0+ (1,0) [0|1] ""  CGM_LS,PEPS_LS
 SG_ KSARUID7 : 1|1@0+ (1,0) [0|1] ""  CGM_LS,PEPS_LS
 SG_ KSARUID6 : 2|1@0+ (1,0) [0|1] ""  CGM_LS,PEPS_LS
 SG_ KSARUID5 : 3|1@0+ (1,0) [0|1] ""  CGM_LS,PEPS_LS
 SG_ KSARUID4 : 4|1@0+ (1,0) [0|1] ""  CGM_LS,PEPS_LS
 SG_ KSARUID3 : 5|1@0+ (1,0) [0|1] ""  CGM_LS,PEPS_LS
 SG_ KSARUID2 : 6|1@0+ (1,0) [0|1] ""  CGM_LS,PEPS_LS
 SG_ KSARUID1 : 7|1@0+ (1,0) [0|1] ""  CGM_LS,PEPS_LS

BO_ 2151309312 Inflatable_Restraints_Key_Id_LS: 2 BCM_LS
 SG_ InflRestId : 7|16@0+ (1,0) [0|39321] ""  CGM_LS,SDM_LS

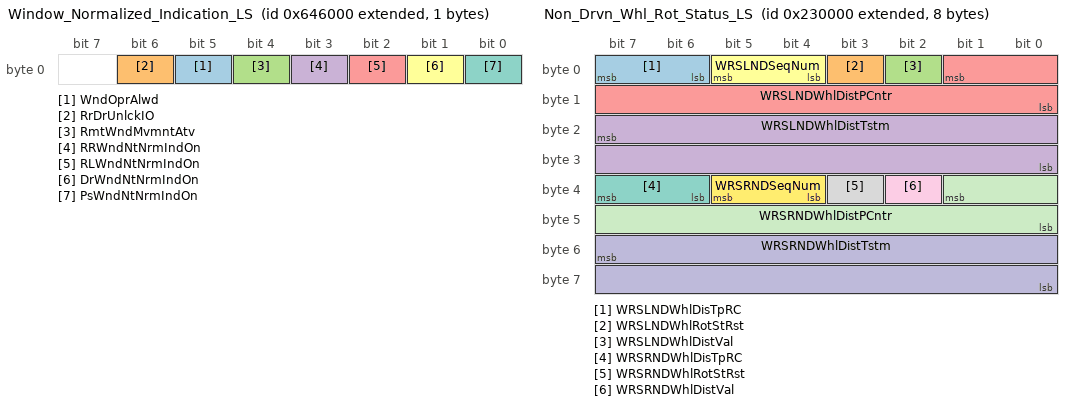
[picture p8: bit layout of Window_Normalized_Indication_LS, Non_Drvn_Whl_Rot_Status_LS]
BO_ 2154061824 Window_Normalized_Indication_LS: 1 BCM_LS
 SG_ WndOprAlwd : 5|1@0+ (1,0) [0|1] ""  CGM_LS,STC_LS
 SG_ RrDrUnlckIO : 6|1@0+ (1,0) [0|1] ""  CGM_LS,IPC_LS
 SG_ RmtWndMvmntAtv : 4|1@0+ (1,0) [0|1] ""  CGM_LS,STC_LS
 SG_ RRWndNtNrmIndOn : 3|1@0+ (1,0) [0|1] ""  CGM_LS,IPC_LS
 SG_ RLWndNtNrmIndOn : 2|1@0+ (1,0) [0|1] ""  CGM_LS,IPC_LS
 SG_ DrWndNtNrmIndOn : 1|1@0+ (1,0) [0|1] ""  CGM_LS,IPC_LS
 SG_ PsWndNtNrmIndOn : 0|1@0+ (1,0) [0|1] ""  CGM_LS,IPC_LS

BO_ 2154512384 Rear_Closure_Rel_Sw_Sta_LS: 1 BCM_LS
 SG_ RrClosRelSwActV : 1|1@0+ (1,0) [0|1] ""  CGM_LS,PEPS_LS
 SG_ RrClosRelSwAct : 0|1@0+ (1,0) [0|1] ""  CGM_LS,PEPS_LS

BO_ 2155347968 HS_Indications_Slow_LS: 8 BCM_LS
 SG_ DrvrStPerfMdCsCrStVal : 62|3@0+ (1,0) [0|7] ""  CGM_LS,CSM_LS,RadioHead_LS
 SG_ DrvrStPerfMdCsStAvl : 63|1@0+ (1,0) [0|1] ""  CGM_LS,CSM_LS,RadioHead_LS
 SG_ ACCPerfMdCsCrStVal : 58|3@0+ (1,0) [0|7] ""  CGM_LS,CSM_LS,RadioHead_LS
 SG_ ACCPerfMdCsStAvl : 59|1@0+ (1,0) [0|1] ""  CGM_LS,CSM_LS,RadioHead_LS
 SG_ VehRollAngleV : 55|1@0+ (1,0) [0|1] ""  CGM_LS,IPC_LS
 SG_ VehRollAngle : 54|7@0+ (0.703125,-45) [-45|44.296875] "deg"  CGM_LS,IPC_LS
 SG_ ActVbnCtrlMlfIO : 0|1@0+ (1,0) [0|1] ""  CGM_LS,IPC_LS
 SG_ HillDesCtrlRedVehSpIO : 47|1@0+ (1,0) [0|1] ""  CGM_LS,IPC_LS
 SG_ FourWhlDrvIndReq : 42|3@0+ (1,0) [0|7] ""  CSM_LS,CGM_LS,IPC_LS
 SG_ PedtrnProtVDA : 35|1@0+ (1,0) [0|1] ""  CSM_LS,CGM_LS,RadioHead_LS,IPC_LS
 SG_ EngRecDwnshftIO : 43|1@0+ (1,0) [0|1] ""  CSM_LS,CGM_LS,RadioHead_LS,IPC_LS
 SG_ AppCltchAutSrtIO : 36|1@0+ (1,0) [0|1] ""  CSM_LS,CGM_LS,RadioHead_LS,IPC_LS
 SG_ CPSUnblIO : 32|1@0+ (1,0) [0|1] ""  CSM_LS,CGM_LS,RadioHead_LS,IPC_LS
 SG_ StBltTgtSetAvl : 37|1@0+ (1,0) [0|1] ""  CGM_LS,CSM_LS,RadioHead_LS
 SG_ StBltTgtCrtSetVal : 46|3@0+ (1,0) [0|7] ""  CGM_LS,CSM_LS,RadioHead_LS
 SG_ PedtrnProtSysDisbld : 34|1@0+ (1,0) [0|1] ""  CSM_LS,CGM_LS,RadioHead_LS,IPC_LS
 SG_ PedtrnProtSysDpl : 1|1@0+ (1,0) [0|1] ""  CSM_LS,CGM_LS,RadioHead_LS,IPC_LS
 SG_ SrvPedtrnProtSysIO : 33|1@0+ (1,0) [0|1] ""  CSM_LS,CGM_LS,RadioHead_LS,IPC_LS
 SG_ CPSOffIO : 31|1@0+ (1,0) [0|1] ""  CSM_LS,CGM_LS,RadioHead_LS,IPC_LS
 SG_ SecAxlTmpInhIO : 24|1@0+ (1,0) [0|1] ""  CSM_LS,CGM_LS,RadioHead_LS,IPC_LS
 SG_ CPSFldIO : 30|1@0+ (1,0) [0|1] ""  CSM_LS,CGM_LS,RadioHead_LS,IPC_LS
 SG_ CPSAlrtOnlIO : 25|1@0+ (1,0) [0|1] ""  CSM_LS,CGM_LS,FCM_LS,RadioHead_LS,IPC_LS
 SG_ RrAxlTmpInhIO : 23|1@0+ (1,0) [0|1] ""  CSM_LS,CGM_LS,RadioHead_LS,IPC_LS
 SG_ TirePrsLowIO : 2|1@0+ (1,0) [0|1] ""  CSM_LS,CGM_LS,RadioHead_LS,SDM_LS,IPC_LS
 SG_ EPBSysStatIndReq : 27|2@0+ (1,0) [0|3] ""  CSM_LS,CGM_LS,RadioHead_LS,IPC_LS
 SG_ EngOilStrvtnIO : 5|1@0+ (1,0) [0|1] ""  CSM_LS,CGM_LS,RadioHead_LS,IPC_LS
 SG_ SrvSuspSysIO : 12|1@0+ (1,0) [0|1] ""  CSM_LS,CGM_LS,RadioHead_LS,IPC_LS
 SG_ ServAdpCrsCtrlIndOn : 11|1@0+ (1,0) [0|1] ""  CSM_LS,TCP_LS,CGM_LS,RadioHead_LS,ONSTAR_LS,IPC_LS
 SG_ EngRecmndUpshftIO : 10|1@0+ (1,0) [0|1] ""  CSM_LS,CGM_LS,RadioHead_LS,IPC_LS
 SG_ BrkSysMalFuncIndOn : 15|1@0+ (1,0) [0|1] ""  CSM_LS,CGM_LS,VIS2_LS,RadioHead_LS,FCM_LS,IPC_LS
 SG_ SecAxlNonEmMalfIO : 6|1@0+ (1,0) [0|1] ""  CSM_LS,CGM_LS,RadioHead_LS,IPC_LS
 SG_ BrkFldLvlLw : 7|1@0+ (1,0) [0|1] ""  CSM_LS,TCP_LS,CGM_LS,RadioHead_LS,ONSTAR_LS,IPC_LS
 SG_ ACCUnavlbleDTWthrIO : 3|1@0+ (1,0) [0|1] ""  CSM_LS,CGM_LS,RadioHead_LS,IPC_LS
 SG_ ACCTmpUnavlbleIO : 9|1@0+ (1,0) [0|1] ""  CSM_LS,CGM_LS,RadioHead_LS,IPC_LS
 SG_ EngEmsRelMalfIndReq : 18|3@0+ (1,0) [0|7] ""  CSM_LS,CGM_LS,RadioHead_LS,IPC_LS
 SG_ DrShftCntrlReqDndIO : 20|1@0+ (1,0) [0|1] ""  CSM_LS,CGM_LS,RadioHead_LS,IPC_LS
 SG_ BrkPadWrnIO : 13|1@0+ (1,0) [0|1] ""  CSM_LS,TCP_LS,CGM_LS,RadioHead_LS,ONSTAR_LS,IPC_LS
 SG_ RrAxlMalfIO : 19|1@0+ (1,0) [0|1] ""  CSM_LS,CGM_LS,RadioHead_LS,IPC_LS
 SG_ EPBSysWrnIndReq : 29|2@0+ (1,0) [0|3] ""  CSM_LS,CGM_LS,RadioHead_LS,IPC_LS
 SG_ CompOvrhtIndOn : 21|1@0+ (1,0) [0|1] ""  CSM_LS,CGM_LS,RadioHead_LS,IPC_LS
 SG_ BrkFldLvlLwV : 4|1@0+ (1,0) [0|1] ""  CSM_LS,TCP_LS,CGM_LS,RadioHead_LS,ONSTAR_LS,IPC_LS
 SG_ ACCSnsClnRqdIO : 8|1@0+ (1,0) [0|1] ""  CSM_LS,CGM_LS,RadioHead_LS,IPC_LS
 SG_ TrnsSkpShftIO : 22|1@0+ (1,0) [0|1] ""  CSM_LS,CGM_LS,RadioHead_LS,IPC_LS

BO_ 2149777408 Non_Drvn_Whl_Rot_Status_LS: 8 BCM_LS
 SG_ WRSLNDWhlDisTpRC : 7|2@0+ (1,0) [0|3] "counts"  VPM_LS,CGM_LS,CSM_LS,RadioHead_LS,UPA_LS,APA_LS
 SG_ WRSLNDWhlRotStRst : 3|1@0+ (1,0) [0|1] ""  VPM_LS,CGM_LS,CSM_LS,RadioHead_LS,UPA_LS,APA_LS
 SG_ WRSLNDWhlDistVal : 2|1@0+ (1,0) [0|1] ""  VPM_LS,CGM_LS,CSM_LS,RadioHead_LS,UPA_LS,APA_LS
 SG_ WRSLNDWhlDistTstm : 23|16@0+ (1,0) [0|65535] "counts"  VPM_LS,CGM_LS,CSM_LS,RadioHead_LS,UPA_LS,APA_LS
 SG_ WRSLNDWhlDistPCntr : 1|10@0+ (1,0) [0|1023] "counts"  VPM_LS,CGM_LS,CSM_LS,RadioHead_LS,UPA_LS,APA_LS
 SG_ WRSLNDSeqNum : 5|2@0+ (1,0) [0|3] "counts"  VPM_LS,CGM_LS,CSM_LS,RadioHead_LS,UPA_LS,APA_LS
 SG_ WRSRNDWhlDisTpRC : 39|2@0+ (1,0) [0|3] "counts"  VPM_LS,CGM_LS,CSM_LS,RadioHead_LS,UPA_LS,APA_LS
 SG_ WRSRNDWhlRotStRst : 35|1@0+ (1,0) [0|1] ""  VPM_LS,CGM_LS,CSM_LS,RadioHead_LS,UPA_LS,APA_LS
 SG_ WRSRNDWhlDistVal : 34|1@0+ (1,0) [0|1] ""  VPM_LS,CGM_LS,CSM_LS,RadioHead_LS,UPA_LS,APA_LS
 SG_ WRSRNDWhlDistTstm : 55|16@0+ (1,0) [0|65535] "counts"  VPM_LS,CGM_LS,CSM_LS,RadioHead_LS,UPA_LS,APA_LS
 SG_ WRSRNDWhlDistPCntr : 33|10@0+ (1,0) [0|1023] "counts"  VPM_LS,CGM_LS,CSM_LS,RadioHead_LS,UPA_LS,APA_LS
 SG_ WRSRNDSeqNum : 37|2@0+ (1,0) [0|3] "counts"  VPM_LS,CGM_LS,CSM_LS,RadioHead_LS,UPA_LS,APA_LS

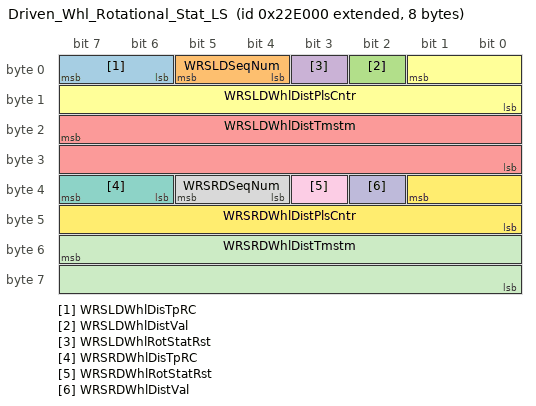
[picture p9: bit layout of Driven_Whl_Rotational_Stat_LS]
BO_ 2149769216 Driven_Whl_Rotational_Stat_LS: 8 BCM_LS
 SG_ WRSLDWhlDisTpRC : 7|2@0+ (1,0) [0|3] "counts"  CGM_LS,UPA_LS,APA_LS
 SG_ WRSLDSeqNum : 5|2@0+ (1,0) [0|3] "counts"  CGM_LS,UPA_LS,APA_LS
 SG_ WRSLDWhlDistVal : 2|1@0+ (1,0) [0|1] ""  CGM_LS,UPA_LS,APA_LS
 SG_ WRSLDWhlRotStatRst : 3|1@0+ (1,0) [0|1] ""  CGM_LS,UPA_LS,APA_LS
 SG_ WRSLDWhlDistTmstm : 23|16@0+ (1,0) [0|65535] "counts"  CGM_LS,UPA_LS,APA_LS
 SG_ WRSLDWhlDistPlsCntr : 1|10@0+ (1,0) [0|1023] "counts"  CGM_LS,UPA_LS,APA_LS
 SG_ WRSRDWhlDisTpRC : 39|2@0+ (1,0) [0|3] "counts"  CGM_LS,UPA_LS,APA_LS
 SG_ WRSRDSeqNum : 37|2@0+ (1,0) [0|3] "counts"  CGM_LS,UPA_LS,APA_LS
 SG_ WRSRDWhlRotStatRst : 35|1@0+ (1,0) [0|1] ""  CGM_LS,UPA_LS,APA_LS
 SG_ WRSRDWhlDistVal : 34|1@0+ (1,0) [0|1] ""  CGM_LS,UPA_LS,APA_LS
 SG_ WRSRDWhlDistTmstm : 55|16@0+ (1,0) [0|65535] "counts"  CGM_LS,UPA_LS,APA_LS
 SG_ WRSRDWhlDistPlsCntr : 33|10@0+ (1,0) [0|1023] "counts"  CGM_LS,UPA_LS,APA_LS

BO_TX_BU_ 2158936064 : EOCM2A_K2_LS,SBZA_L_LS,EOCM_F_LS,UPA_LS,APA_LS,BCM_LS,MSM_P_LS,MSM_LS,ECC_LS;
BO_TX_BU_ 2158845952 : CSM_LS,CGM_LS,RadioHead_LS;
BO_TX_BU_ 2158886912 : CGM_LS,IPC_LS;
BO_TX_BU_ 1603 : DCAC_LS,AGC_LS;
BO_TX_BU_ 1574 : CGM_LS,ICS_LS;
BO_TX_BU_ 1571 : DCAC_LS,AGC_LS;
BO_TX_BU_ 1347 : DCAC_LS,AGC_LS;
BO_TX_BU_ 582 : CGM_LS,CSM_LS,TCP_LS,ONSTAR_LS,TestTool_LS;
BO_TX_BU_ 579 : CSM_LS,CGM_LS,TCP_LS,ONSTAR_LS,TestTool_LS;
BO_TX_BU_ 1577 : CGM_LS,MSM_P_LS,OTIM_LS;
BO_TX_BU_ 1609 : CGM_LS,MSM_P_LS,OTIM_LS;
BO_TX_BU_ 2159132672 : CGM_LS,RSC_LS,RSA_LS;
BO_TX_BU_ 2158968832 : RSC_LS,RSA_LS;
BO_TX_BU_ 2158960640 : CSM_LS,RadioHead_LS;
BO_TX_BU_ 2158977024 : CSM_LS,RadioHead_LS;
BO_TX_BU_ 2158952448 : CGM_LS,RSC_LS,RSA_LS;
BO_TX_BU_ 2158944256 : RSC_LS,RSA_LS;
BO_TX_BU_ 2158927872 : CSM_LS,RadioHead_LS;
BO_TX_BU_ 2158895104 : CSM_LS,RadioHead_LS;
BO_TX_BU_ 2152022016 : TCP_LS,ONSTAR_LS;
BO_TX_BU_ 2151972864 : CGM_LS,IPC_LS;
BO_TX_BU_ 2154512384 : LCM_LS,PTM_LS,BCM_LS;
CM_ SG_ 2158936064 ODIEDD_Data18Value "ODI";
CM_ SG_ 2158936064 ODIEDD_Data17Value "ODI";
CM_ SG_ 2158936064 ODIEDD_Data16Value "ODI";
CM_ SG_ 2158936064 ODIEDD_Data15Value "ODI";
CM_ SG_ 2158936064 ODIEDD_Data14Value "ODI";
CM_ SG_ 2158936064 ODIEDD_Data13Value "ODI";
CM_ SG_ 2158936064 ODIEDD_Data12Value "ODI";
CM_ SG_ 2158936064 ODIEDD_Data11Value "ODI";
CM_ SG_ 2158936064 ODIEDD_Data10Value "ODI";
CM_ SG_ 2158936064 ODIEDD_Data9Value "ODI";
CM_ SG_ 2158936064 ODIEDD_Data8Value "ODI";
CM_ SG_ 2158936064 ODIEDD_Data7Value "ODI";
CM_ SG_ 2158936064 ODIEDD_Data6Value "ODI";
CM_ SG_ 2158936064 ODIEDD_Data5Value "ODI";
CM_ SG_ 2158936064 ODIEDD_Data4Value "ODI";
CM_ SG_ 2158936064 ODIEDD_Data3Value "ODI";
CM_ SG_ 2158936064 ODIEDD_Data2Value "ODI";
CM_ SG_ 2158936064 ODIEDD_Data1Value "ODI";
CM_ SG_ 2158936064 ODIEDD_FUCID "ODI - Primary ID of Functional Unit in FU Database";
CM_ SG_ 2158845952 ODIAC_FUCID "ODI - Primary ID of Functional Unit in FU Database";
CM_ SG_ 2158845952 ODIAC_DspMID "ODI - ID that identifies the display requesting the data.  See detailed requirements in ODI GMLAN Protocol.";
CM_ SG_ 2158845952 ODIAC_ActnVal "ODI-Integer value for Actions with values.
FUDatabase definition of Action includes ActionDataType that defines whether or not Action has a value. 
For Actions without a value, this field is always sent as 0.";
CM_ SG_ 2158845952 ODIAC_ActnID "ODI-ActionId within the FUClass";
CM_ SG_ 2158886912 ODDLI_SubIdReqM "ODI-The number of list entries, starting at the Index, to send";
CM_ SG_ 2158886912 ODDLI_WrpArnd "ODI-Boolean that shall be set to true if the list shall wrap around.";
CM_ SG_ 2158886912 ODDLI_ReqType "ODI - Type of Request";
CM_ SG_ 2158886912 ODDLI_ReqDir "ODI-Boolean that shall be set to true if req down, set to false if set to up";
CM_ SG_ 2158886912 ODDLI_NmEntries "ODI-The number of list entries, starting at the Index, to send";
CM_ SG_ 2158886912 ODDLI_Idx "ODI-The index within the remote FU’s list at which to start sending data";
CM_ SG_ 2158886912 ODDLI_FUCID "ODI - Primary ID of Functional Unit in FU Database";
CM_ SG_ 2158886912 ODDLI_DspMID "ODI - ID that identifies the display requesting the data.  See detailed requirements in ODI GMLAN Protocol.";
CM_ SG_ 2158886912 ODDLI_DataId "ODI-Data Id for the dynamic list";
CM_ SG_ 2158886912 ODDLI_BckgndFlag "ODI-Informs FU as to priority of response.
Applies to all DataIds in the message.
$0=Immediate response required
$1=Background response";
CM_ SG_ 2149842944 BrkSysAutBrkFld "BrakeSystemAutomaticBrakingFailed";
CM_ SG_ 2159132672 ODIAR_FUCID "ODI - Primary ID of Functional Unit in FU Database";
CM_ SG_ 2159132672 ODIAR_DspMID "ODI - ID that identifies the display requesting the data.  See detailed requirements in ODI GMLAN Protocol.";
CM_ SG_ 2159132672 ODIAR_ActnVal "ODI-Integer value for Actions with values.
FUDatabase definition of Action includes ActionDataType that defines whether or not Action has a value. 
For Actions without a value, this field is always sent as 0.";
CM_ SG_ 2159132672 ODIAR_ActnID "ODI-ActionId within the FUClass";
CM_ SG_ 2158960640 ODIIC_FUCID "ODI - Primary ID of Functional Unit in FU Database";
CM_ SG_ 2158977024 ODIEC_FUCID "ODI - Primary ID of Functional Unit in FU Database";
CM_ SG_ 2158977024 ODIEC_EvID "EventID within FUClass";
CM_ SG_ 2158952448 ODDMR_ReqType "ODI - Type of Request";
CM_ SG_ 2158952448 ODDMR_FUCID "ODI - Primary ID of Functional Unit in FU Database";
CM_ SG_ 2158952448 ODDMR_DispMID "ODI - ID that identifies the display requesting the data.  See detailed requirements in ODI GMLAN Protocol.";
CM_ SG_ 2158952448 ODDMR_DataID2Vld "ODI -DataIDTwo is being requested as a valid ID.";
CM_ SG_ 2158952448 ODDMR_DataID2 "ODI - ID for the second requested data parameter as defined in the FUDatabase";
CM_ SG_ 2158952448 ODDMR_DataID3Vld "ODI -DataIDThree is being requested as a valid ID.";
CM_ SG_ 2158952448 ODDMR_DataID3 "ODI - ID for the third requested data parameter as defined in the FUDatabase";
CM_ SG_ 2158952448 ODDMR_DataID1 "ODI - ID for the first requested data parameter as defined in the FUDatabase";
CM_ SG_ 2158952448 ODDMR_DataID4Vld "ODI -DataIDFour is being requested as a valid ID.";
CM_ SG_ 2158952448 ODDMR_DataID4 "ODI - ID for the fourth requested data parameter as defined in the FUDatabase";
CM_ SG_ 2158952448 ODDMR_DataID5Vld "ODI -DataIDFive is being requested as a valid ID.";
CM_ SG_ 2158952448 ODDMR_DataID5 "ODI - ID for the fifth requested data parameter as defined in the FUDatabase";
CM_ SG_ 2158944256 ODDLR_SubIdReqM "ODI-The number of list entries, starting at the Index, to send";
CM_ SG_ 2158944256 ODDLR_WrpArnd "ODI-Boolean that shall be set to true if the list shall wrap around.";
CM_ SG_ 2158944256 ODDLR_ReqType "ODI - Type of Request";
CM_ SG_ 2158944256 ODDLR_ReqDir "ODI-Boolean that shall be set to true if req down, set to false if set to up";
CM_ SG_ 2158944256 ODDLR_NmEntries "ODI-The number of list entries, starting at the Index, to send";
CM_ SG_ 2158944256 ODDLR_Idx "ODI-The index within the remote FU’s list at which to start sending data";
CM_ SG_ 2158944256 ODDLR_FUCID "ODI - Primary ID of Functional Unit in FU Database";
CM_ SG_ 2158944256 ODDLR_DspMID "ODI - ID that identifies the display requesting the data.  See detailed requirements in ODI GMLAN Protocol.";
CM_ SG_ 2158944256 ODDLR_DataId "ODI-Data Id for the dynamic list";
CM_ SG_ 2158944256 ODDLR_BckgndFlag "ODI-Informs FU as to priority of response.
Applies to all DataIds in the message.
$0=Immediate response required
$1=Background response";
CM_ SG_ 2158927872 ODDC_InvldData "ODI";
CM_ SG_ 2158927872 ODDC_FUCID "ODI - Primary ID of Functional Unit in FU Database";
CM_ SG_ 2158927872 ODDC_DataVal "ODI";
CM_ SG_ 2158927872 ODDC_DataType "ODI";
CM_ SG_ 2158927872 ODDC_DataId "ODI-Data Id for the dynamic list";
CM_ SG_ 2150916096 PrkHtrCoolntTempM "Signal Shortname in CSD is PrkHtrCoolntTempMsk. This is a known discrepancy.";
CM_ SG_ 2150916096 PrkHtrFlCnsmdRolCntV "ParkHeater shall be used to denote a heater function that can operate independent of the engine operating status.";
CM_ SG_ 2150916096 PrkHtrFlCsmdRlCntRsOc "ParkHeater shall be used to denote a heater function that can operate independent of the engine operating status.";
CM_ SG_ 2150916096 PrkHtrFlCnsmdRolCnt "ParkHeater shall be used to denote a heater function that can operate independent of the engine operating status.";
BA_DEF_ SG_  "VNSigPrimaryTriggering" ENUM  "No","Yes","DLCLS","DLCHS","DLCCE","DLCFO";
BA_DEF_ SG_  "VNSigRemoteDiagnostics" ENUM  "No","Yes","DLCLS","DLCHS","DLCCE","DLCFO";
BA_DEF_ SG_  "VNSigInfotainment" ENUM  "No","Yes","DLCLS","DLCHS","DLCCE","DLCFO";
BA_DEF_ SG_  "VNSigParkedVehicle" ENUM  "No","Yes","DLCLS","DLCHS","DLCCE","DLCFO";
BA_DEF_ SG_  "VNSigIntermediate" ENUM  "No","Yes","DLCLS","DLCHS","DLCCE","DLCFO";
BA_DEF_ SG_  "VNSigUnused_4" ENUM  "No","Yes","DLCLS","DLCHS","DLCCE","DLCFO";
BA_DEF_ SG_  "SignalType" STRING ;
BA_DEF_ SG_  "PacketOrder" INT 0 65535;
BA_DEF_ SG_  "SignalLongName" STRING ;
BA_DEF_ SG_  "GenSigStartValue" INT 0 65535;
BA_DEF_ SG_  "VNSigDiagnostic" ENUM  "No","Yes","DLCLS","DLCHS","DLCCE","DLCFO";
BA_DEF_ SG_  "VNSigAllNodes" ENUM  "No","Yes","DLCLS","DLCHS","DLCCE","DLCFO";
BA_DEF_ SG_  "GenSigDeltaValue" INT 0 0;
BA_DEF_ SG_  "GenSigInactiveValue" INT 0 0;
BA_DEF_ SG_  "GenSigSendType" ENUM  "not used","not used","not used","not used","not used","not used","not used","NoSigSendType","not used","not used","OnAnyChange","OnChangeIfActive","OnDelta","DLCLS","DLCHS","DLCCE","DLCFO";
BA_DEF_ SG_  "GenSigSendOnInit" ENUM  "Not Initialized","Application","Handler","DLCLS","DLCHS","DLCCE","DLCFO";
BA_DEF_ BO_  "AppGenMsgCycleTime" INT 0 0;
BA_DEF_ BO_  "TpTxIndex" INT 0 99;
BA_DEF_ BO_  "GenMsgILSupport" ENUM  "No","Yes","DLCLS","DLCHS","DLCCE","DLCFO";
BA_DEF_ BO_  "TpApplType" STRING ;
BA_DEF_ BO_  "Prio" INT 0 7;
BA_DEF_ BO_  "MessageSubnet" ENUM  "LS","MS","HS","CE","PE","HV","FO","S1","HE","LE","HE2","DLCLS","DLCHS","DLCCE","DLCFO";
BA_DEF_ BO_  "GenMsgMandatoryToSupervision" ENUM  "No","Yes","DLCLS","DLCHS","DLCCE","DLCFO";
BA_DEF_ BO_  "DiagState" ENUM  "No","Yes","DLCLS","DLCHS","DLCCE","DLCFO";
BA_DEF_ BO_  "GenMsgStartDelayTime" INT 0 100000;
BA_DEF_ BO_  "GenMsgDelayTime" INT 0 100000;
BA_DEF_ BO_  "GenMsgCycleTime" INT 0 100000;
BA_DEF_ BO_  "GenMsgSendType" ENUM  "cyclicX","spontanX","cyclicIfActiveX","spontanWithDelay","cyclicAndSpontanX","cyclicAndSpontanWithDelay","spontanWithRepitition","cyclicIfActiveAndSpontanWD","DLCLS","DLCHS","DLCCE","DLCFO";
BA_DEF_ BO_  "DiagResponse" ENUM  "No","Yes","DLCLS","DLCHS","DLCCE","DLCFO";
BA_DEF_ BO_  "DiagRequest" ENUM  "No","Yes","DLCLS","DLCHS","DLCCE","DLCFO";
BA_DEF_ BO_  "NmMessage" ENUM  "No","Yes","DLCLS","DLCHS","DLCCE","DLCFO";
BA_DEF_REL_ BU_SG_REL_  "GenSigSuprvRespComment" STRING ;
BA_DEF_REL_ BU_SG_REL_  "GenSigVBitResp" ENUM  "No","Yes","DLCLS","DLCHS","DLCCE","DLCFO";
BA_DEF_REL_ BU_SG_REL_  "GenSigVBitRespComment" STRING ;
BA_DEF_REL_ BU_SG_REL_  "GenSigVDAFailComment" STRING ;
BA_DEF_REL_ BU_SG_REL_  "GenSigVDAFailResp" ENUM  "No","Yes","DLCLS","DLCHS","DLCCE","DLCFO";
BA_DEF_REL_ BU_SG_REL_  "GenSigRxStartValue" STRING ;
BA_DEF_REL_ BU_SG_REL_  "GenSigSuprvRespSubValue" INT 0 65535;
BA_DEF_REL_ BU_SG_REL_  "GenSigSuprvResp" ENUM  "None","Notify App","Substitute Default","DLCLS","DLCHS","DLCCE","DLCFO";
BA_DEF_REL_ BU_SG_REL_  "GenSigTimeoutMsg" HEX -2147483648 268435455;
BA_DEF_REL_ BU_SG_REL_  "GenSigTimeoutTime" INT 0 15000;
BA_DEF_DEF_  "VNSigPrimaryTriggering" "No";
BA_DEF_DEF_  "VNSigRemoteDiagnostics" "No";
BA_DEF_DEF_  "VNSigInfotainment" "No";
BA_DEF_DEF_  "VNSigParkedVehicle" "No";
BA_DEF_DEF_  "VNSigIntermediate" "No";
BA_DEF_DEF_  "VNSigUnused_4" "No";
BA_DEF_DEF_  "SignalType" "";
BA_DEF_DEF_  "PacketOrder" 0;
BA_DEF_DEF_  "SignalLongName" "";
BA_DEF_DEF_  "GenSigStartValue" 0;
BA_DEF_DEF_  "VNSigDiagnostic" "No";
BA_DEF_DEF_  "VNSigAllNodes" "No";
BA_DEF_DEF_  "GenSigDeltaValue" 0;
BA_DEF_DEF_  "GenSigInactiveValue" 0;
BA_DEF_DEF_  "GenSigSendType" "NoSigSendType";
BA_DEF_DEF_  "GenSigSendOnInit" "Not Initialized";
BA_DEF_DEF_  "AppGenMsgCycleTime" 0;
BA_DEF_DEF_  "TpTxIndex" 0;
BA_DEF_DEF_  "GenMsgILSupport" "Yes";
BA_DEF_DEF_  "TpApplType" "";
BA_DEF_DEF_  "Prio" 4;
BA_DEF_DEF_  "MessageSubnet" "FO";
BA_DEF_DEF_  "GenMsgMandatoryToSupervision" "No";
BA_DEF_DEF_  "DiagState" "No";
BA_DEF_DEF_  "GenMsgStartDelayTime" 0;
BA_DEF_DEF_  "GenMsgDelayTime" 0;
BA_DEF_DEF_  "GenMsgCycleTime" 0;
BA_DEF_DEF_  "GenMsgSendType" "spontanX";
BA_DEF_DEF_  "DiagResponse" "No";
BA_DEF_DEF_  "DiagRequest" "No";
BA_DEF_DEF_  "NmMessage" "No";
BA_DEF_DEF_REL_ "GenSigSuprvRespComment" "";
BA_DEF_DEF_REL_ "GenSigVBitResp" "No";
BA_DEF_DEF_REL_ "GenSigVBitRespComment" "";
BA_DEF_DEF_REL_ "GenSigVDAFailComment" "";
BA_DEF_DEF_REL_ "GenSigVDAFailResp" "No";
BA_DEF_DEF_REL_ "GenSigRxStartValue" "";
BA_DEF_DEF_REL_ "GenSigSuprvRespSubValue" 0;
BA_DEF_DEF_REL_ "GenSigSuprvResp" "None";
BA_DEF_DEF_REL_ "GenSigTimeoutMsg" 0;
BA_DEF_DEF_REL_ "GenSigTimeoutTime" 0;
BA_ "MessageSubnet" BO_ 2158936064 0;
BA_ "GenMsgDelayTime" BO_ 2158936064 100;
BA_ "MessageSubnet" BO_ 2158845952 0;
BA_ "GenMsgDelayTime" BO_ 2158845952 20;
BA_ "MessageSubnet" BO_ 2158886912 0;
BA_ "GenMsgDelayTime" BO_ 2158886912 20;
BA_ "Prio" BO_ 1596 0;
BA_ "MessageSubnet" BO_ 1596 0;
BA_ "GenMsgCycleTime" BO_ 1596 3000;
BA_ "GenMsgSendType" BO_ 1596 0;
BA_ "NmMessage" BO_ 1596 1;
BA_ "MessageSubnet" BO_ 2151366656 0;
BA_ "GenMsgDelayTime" BO_ 2151366656 100;
BA_ "MessageSubnet" BO_ 2149842944 0;
BA_ "GenMsgStartDelayTime" BO_ 2149842944 160;
BA_ "GenMsgCycleTime" BO_ 2149842944 100;
BA_ "GenMsgSendType" BO_ 2149842944 0;
BA_ "Prio" BO_ 1603 0;
BA_ "MessageSubnet" BO_ 1603 0;
BA_ "DiagResponse" BO_ 1603 1;
BA_ "Prio" BO_ 1574 0;
BA_ "MessageSubnet" BO_ 1574 0;
BA_ "GenMsgCycleTime" BO_ 1574 3000;
BA_ "GenMsgSendType" BO_ 1574 0;
BA_ "NmMessage" BO_ 1574 1;
BA_ "Prio" BO_ 1571 0;
BA_ "MessageSubnet" BO_ 1571 0;
BA_ "GenMsgCycleTime" BO_ 1571 3000;
BA_ "GenMsgSendType" BO_ 1571 0;
BA_ "NmMessage" BO_ 1571 1;
BA_ "GenMsgILSupport" BO_ 1347 0;
BA_ "TpApplType" BO_ 1347 "DiagUUDTResponse";
BA_ "Prio" BO_ 1347 0;
BA_ "MessageSubnet" BO_ 1347 0;
BA_ "Prio" BO_ 582 0;
BA_ "MessageSubnet" BO_ 582 0;
BA_ "DiagRequest" BO_ 582 1;
BA_ "Prio" BO_ 579 0;
BA_ "MessageSubnet" BO_ 579 0;
BA_ "DiagRequest" BO_ 579 1;
BA_ "Prio" BO_ 1577 0;
BA_ "MessageSubnet" BO_ 1577 0;
BA_ "GenMsgCycleTime" BO_ 1577 3000;
BA_ "GenMsgSendType" BO_ 1577 0;
BA_ "NmMessage" BO_ 1577 1;
BA_ "GenMsgILSupport" BO_ 1609 0;
BA_ "Prio" BO_ 1609 0;
BA_ "MessageSubnet" BO_ 1609 0;
BA_ "DiagResponse" BO_ 1609 1;
BA_ "MessageSubnet" BO_ 2159132672 0;
BA_ "GenMsgDelayTime" BO_ 2159132672 20;
BA_ "MessageSubnet" BO_ 2158968832 0;
BA_ "GenMsgDelayTime" BO_ 2158968832 10;
BA_ "MessageSubnet" BO_ 2158960640 0;
BA_ "GenMsgDelayTime" BO_ 2158960640 100;
BA_ "MessageSubnet" BO_ 2158977024 0;
BA_ "GenMsgDelayTime" BO_ 2158977024 100;
BA_ "MessageSubnet" BO_ 2158952448 0;
BA_ "GenMsgDelayTime" BO_ 2158952448 20;
BA_ "MessageSubnet" BO_ 2158944256 0;
BA_ "GenMsgDelayTime" BO_ 2158944256 20;
BA_ "MessageSubnet" BO_ 2158927872 0;
BA_ "GenMsgDelayTime" BO_ 2158927872 100;
BA_ "MessageSubnet" BO_ 2158895104 0;
BA_ "GenMsgDelayTime" BO_ 2158895104 10;
BA_ "MessageSubnet" BO_ 2152038400 0;
BA_ "GenMsgDelayTime" BO_ 2152038400 100;
BA_ "MessageSubnet" BO_ 2152022016 0;
BA_ "GenMsgDelayTime" BO_ 2152022016 100;
BA_ "MessageSubnet" BO_ 2152005632 0;
BA_ "GenMsgDelayTime" BO_ 2152005632 100;
BA_ "MessageSubnet" BO_ 2151989248 0;
BA_ "GenMsgDelayTime" BO_ 2151989248 100;
BA_ "MessageSubnet" BO_ 2151972864 0;
BA_ "GenMsgDelayTime" BO_ 2151972864 100;
BA_ "MessageSubnet" BO_ 2154528768 0;
BA_ "GenMsgStartDelayTime" BO_ 2154528768 160;
BA_ "GenMsgCycleTime" BO_ 2154528768 200;
BA_ "GenMsgSendType" BO_ 2154528768 0;
BA_ "MessageSubnet" BO_ 2150916096 0;
BA_ "GenMsgDelayTime" BO_ 2150916096 100;
BA_ "MessageSubnet" BO_ 2150367232 0;
BA_ "GenMsgStartDelayTime" BO_ 2150367232 170;
BA_ "GenMsgCycleTime" BO_ 2150367232 300;
BA_ "GenMsgSendType" BO_ 2150367232 0;
BA_ "Prio" BO_ 2150621184 3;
BA_ "MessageSubnet" BO_ 2150621184 0;
BA_ "GenMsgDelayTime" BO_ 2150621184 100;
BA_ "MessageSubnet" BO_ 2151309312 0;
BA_ "GenMsgDelayTime" BO_ 2151309312 100;
BA_ "MessageSubnet" BO_ 2154061824 0;
BA_ "GenMsgDelayTime" BO_ 2154061824 100;
BA_ "Prio" BO_ 2154512384 3;
BA_ "MessageSubnet" BO_ 2154512384 0;
BA_ "GenMsgDelayTime" BO_ 2154512384 100;
BA_ "MessageSubnet" BO_ 2155347968 0;
BA_ "GenMsgStartDelayTime" BO_ 2155347968 180;
BA_ "GenMsgCycleTime" BO_ 2155347968 250;
BA_ "GenMsgSendType" BO_ 2155347968 0;
BA_ "MessageSubnet" BO_ 2149777408 0;
BA_ "GenMsgStartDelayTime" BO_ 2149777408 140;
BA_ "GenMsgCycleTime" BO_ 2149777408 200;
BA_ "GenMsgSendType" BO_ 2149777408 0;
BA_ "MessageSubnet" BO_ 2149769216 0;
BA_ "GenMsgStartDelayTime" BO_ 2149769216 130;
BA_ "GenMsgCycleTime" BO_ 2149769216 200;
BA_ "GenMsgSendType" BO_ 2149769216 0;
BA_ "GenSigDeltaValue" SG_ 2158936064 ODIEDD_Data18Value 1;
BA_ "GenSigSendType" SG_ 2158936064 ODIEDD_Data18Value 12;
BA_ "GenSigSendOnInit" SG_ 2158936064 ODIEDD_Data18Value 1;
BA_ "VNSigInfotainment" SG_ 2158936064 ODIEDD_Data18Value 1;
BA_ "SignalType" SG_ 2158936064 ODIEDD_Data18Value "UNM";
BA_ "PacketOrder" SG_ 2158936064 ODIEDD_Data18Value 18;
BA_ "SignalLongName" SG_ 2158936064 ODIEDD_Data18Value "Open Display Interface Enum Dynamic Data : Data ID 18";
BA_ "VNSigAllNodes" SG_ 2158936064 ODIEDD_Data18Value 1;
BA_ "GenSigDeltaValue" SG_ 2158936064 ODIEDD_Data17Value 1;
BA_ "GenSigSendType" SG_ 2158936064 ODIEDD_Data17Value 12;
BA_ "GenSigSendOnInit" SG_ 2158936064 ODIEDD_Data17Value 1;
BA_ "VNSigInfotainment" SG_ 2158936064 ODIEDD_Data17Value 1;
BA_ "SignalType" SG_ 2158936064 ODIEDD_Data17Value "UNM";
BA_ "PacketOrder" SG_ 2158936064 ODIEDD_Data17Value 17;
BA_ "SignalLongName" SG_ 2158936064 ODIEDD_Data17Value "Open Display Interface Enum Dynamic Data : Data ID 17";
BA_ "VNSigAllNodes" SG_ 2158936064 ODIEDD_Data17Value 1;
BA_ "GenSigDeltaValue" SG_ 2158936064 ODIEDD_Data16Value 1;
BA_ "GenSigSendType" SG_ 2158936064 ODIEDD_Data16Value 12;
BA_ "GenSigSendOnInit" SG_ 2158936064 ODIEDD_Data16Value 1;
BA_ "VNSigInfotainment" SG_ 2158936064 ODIEDD_Data16Value 1;
BA_ "SignalType" SG_ 2158936064 ODIEDD_Data16Value "UNM";
BA_ "PacketOrder" SG_ 2158936064 ODIEDD_Data16Value 16;
BA_ "SignalLongName" SG_ 2158936064 ODIEDD_Data16Value "Open Display Interface Enum Dynamic Data : Data ID 16";
BA_ "VNSigAllNodes" SG_ 2158936064 ODIEDD_Data16Value 1;
BA_ "GenSigDeltaValue" SG_ 2158936064 ODIEDD_Data15Value 1;
BA_ "GenSigSendType" SG_ 2158936064 ODIEDD_Data15Value 12;
BA_ "GenSigSendOnInit" SG_ 2158936064 ODIEDD_Data15Value 1;
BA_ "VNSigInfotainment" SG_ 2158936064 ODIEDD_Data15Value 1;
BA_ "SignalType" SG_ 2158936064 ODIEDD_Data15Value "UNM";
BA_ "PacketOrder" SG_ 2158936064 ODIEDD_Data15Value 15;
BA_ "SignalLongName" SG_ 2158936064 ODIEDD_Data15Value "Open Display Interface Enum Dynamic Data : Data ID 15";
BA_ "VNSigAllNodes" SG_ 2158936064 ODIEDD_Data15Value 1;
BA_ "GenSigDeltaValue" SG_ 2158936064 ODIEDD_Data14Value 1;
BA_ "GenSigSendType" SG_ 2158936064 ODIEDD_Data14Value 12;
BA_ "GenSigSendOnInit" SG_ 2158936064 ODIEDD_Data14Value 1;
BA_ "VNSigInfotainment" SG_ 2158936064 ODIEDD_Data14Value 1;
BA_ "SignalType" SG_ 2158936064 ODIEDD_Data14Value "UNM";
BA_ "PacketOrder" SG_ 2158936064 ODIEDD_Data14Value 14;
BA_ "SignalLongName" SG_ 2158936064 ODIEDD_Data14Value "Open Display Interface Enum Dynamic Data : Data ID 14";
BA_ "VNSigAllNodes" SG_ 2158936064 ODIEDD_Data14Value 1;
BA_ "GenSigDeltaValue" SG_ 2158936064 ODIEDD_Data13Value 1;
BA_ "GenSigSendType" SG_ 2158936064 ODIEDD_Data13Value 12;
BA_ "GenSigSendOnInit" SG_ 2158936064 ODIEDD_Data13Value 1;
BA_ "VNSigInfotainment" SG_ 2158936064 ODIEDD_Data13Value 1;
BA_ "SignalType" SG_ 2158936064 ODIEDD_Data13Value "UNM";
BA_ "PacketOrder" SG_ 2158936064 ODIEDD_Data13Value 13;
BA_ "SignalLongName" SG_ 2158936064 ODIEDD_Data13Value "Open Display Interface Enum Dynamic Data : Data ID 13";
BA_ "VNSigAllNodes" SG_ 2158936064 ODIEDD_Data13Value 1;
BA_ "GenSigDeltaValue" SG_ 2158936064 ODIEDD_Data12Value 1;
BA_ "GenSigSendType" SG_ 2158936064 ODIEDD_Data12Value 12;
BA_ "GenSigSendOnInit" SG_ 2158936064 ODIEDD_Data12Value 1;
BA_ "VNSigInfotainment" SG_ 2158936064 ODIEDD_Data12Value 1;
BA_ "SignalType" SG_ 2158936064 ODIEDD_Data12Value "UNM";
BA_ "PacketOrder" SG_ 2158936064 ODIEDD_Data12Value 12;
BA_ "SignalLongName" SG_ 2158936064 ODIEDD_Data12Value "Open Display Interface Enum Dynamic Data : Data ID 12";
BA_ "VNSigAllNodes" SG_ 2158936064 ODIEDD_Data12Value 1;
BA_ "GenSigDeltaValue" SG_ 2158936064 ODIEDD_Data11Value 1;
BA_ "GenSigSendType" SG_ 2158936064 ODIEDD_Data11Value 12;
BA_ "GenSigSendOnInit" SG_ 2158936064 ODIEDD_Data11Value 1;
BA_ "VNSigInfotainment" SG_ 2158936064 ODIEDD_Data11Value 1;
BA_ "SignalType" SG_ 2158936064 ODIEDD_Data11Value "UNM";
BA_ "PacketOrder" SG_ 2158936064 ODIEDD_Data11Value 11;
BA_ "SignalLongName" SG_ 2158936064 ODIEDD_Data11Value "Open Display Interface Enum Dynamic Data : Data ID 11";
BA_ "VNSigAllNodes" SG_ 2158936064 ODIEDD_Data11Value 1;
BA_ "GenSigDeltaValue" SG_ 2158936064 ODIEDD_Data10Value 1;
BA_ "GenSigSendType" SG_ 2158936064 ODIEDD_Data10Value 12;
BA_ "GenSigSendOnInit" SG_ 2158936064 ODIEDD_Data10Value 1;
BA_ "VNSigInfotainment" SG_ 2158936064 ODIEDD_Data10Value 1;
BA_ "SignalType" SG_ 2158936064 ODIEDD_Data10Value "UNM";
BA_ "PacketOrder" SG_ 2158936064 ODIEDD_Data10Value 10;
BA_ "SignalLongName" SG_ 2158936064 ODIEDD_Data10Value "Open Display Interface Enum Dynamic Data : Data ID 10";
BA_ "VNSigAllNodes" SG_ 2158936064 ODIEDD_Data10Value 1;
BA_ "GenSigDeltaValue" SG_ 2158936064 ODIEDD_Data9Value 1;
BA_ "GenSigSendType" SG_ 2158936064 ODIEDD_Data9Value 12;
BA_ "GenSigSendOnInit" SG_ 2158936064 ODIEDD_Data9Value 1;
BA_ "VNSigInfotainment" SG_ 2158936064 ODIEDD_Data9Value 1;
BA_ "SignalType" SG_ 2158936064 ODIEDD_Data9Value "UNM";
BA_ "PacketOrder" SG_ 2158936064 ODIEDD_Data9Value 9;
BA_ "SignalLongName" SG_ 2158936064 ODIEDD_Data9Value "Open Display Interface Enum Dynamic Data : Data ID 9";
BA_ "VNSigAllNodes" SG_ 2158936064 ODIEDD_Data9Value 1;
BA_ "GenSigDeltaValue" SG_ 2158936064 ODIEDD_Data8Value 1;
BA_ "GenSigSendType" SG_ 2158936064 ODIEDD_Data8Value 12;
BA_ "GenSigSendOnInit" SG_ 2158936064 ODIEDD_Data8Value 1;
BA_ "VNSigInfotainment" SG_ 2158936064 ODIEDD_Data8Value 1;
BA_ "SignalType" SG_ 2158936064 ODIEDD_Data8Value "UNM";
BA_ "PacketOrder" SG_ 2158936064 ODIEDD_Data8Value 8;
BA_ "SignalLongName" SG_ 2158936064 ODIEDD_Data8Value "Open Display Interface Enum Dynamic Data : Data ID 8";
BA_ "VNSigAllNodes" SG_ 2158936064 ODIEDD_Data8Value 1;
BA_ "GenSigDeltaValue" SG_ 2158936064 ODIEDD_Data7Value 1;
BA_ "GenSigSendType" SG_ 2158936064 ODIEDD_Data7Value 12;
BA_ "GenSigSendOnInit" SG_ 2158936064 ODIEDD_Data7Value 1;
BA_ "VNSigInfotainment" SG_ 2158936064 ODIEDD_Data7Value 1;
BA_ "SignalType" SG_ 2158936064 ODIEDD_Data7Value "UNM";
BA_ "PacketOrder" SG_ 2158936064 ODIEDD_Data7Value 7;
BA_ "SignalLongName" SG_ 2158936064 ODIEDD_Data7Value "Open Display Interface Enum Dynamic Data : Data ID 7";
BA_ "VNSigAllNodes" SG_ 2158936064 ODIEDD_Data7Value 1;
BA_ "GenSigDeltaValue" SG_ 2158936064 ODIEDD_Data6Value 1;
BA_ "GenSigSendType" SG_ 2158936064 ODIEDD_Data6Value 12;
BA_ "GenSigSendOnInit" SG_ 2158936064 ODIEDD_Data6Value 1;
BA_ "VNSigInfotainment" SG_ 2158936064 ODIEDD_Data6Value 1;
BA_ "SignalType" SG_ 2158936064 ODIEDD_Data6Value "UNM";
BA_ "PacketOrder" SG_ 2158936064 ODIEDD_Data6Value 6;
BA_ "SignalLongName" SG_ 2158936064 ODIEDD_Data6Value "Open Display Interface Enum Dynamic Data : Data ID 6";
BA_ "VNSigAllNodes" SG_ 2158936064 ODIEDD_Data6Value 1;
BA_ "GenSigDeltaValue" SG_ 2158936064 ODIEDD_Data5Value 1;
BA_ "GenSigSendType" SG_ 2158936064 ODIEDD_Data5Value 12;
BA_ "GenSigSendOnInit" SG_ 2158936064 ODIEDD_Data5Value 1;
BA_ "VNSigInfotainment" SG_ 2158936064 ODIEDD_Data5Value 1;
BA_ "SignalType" SG_ 2158936064 ODIEDD_Data5Value "UNM";
BA_ "PacketOrder" SG_ 2158936064 ODIEDD_Data5Value 5;
BA_ "SignalLongName" SG_ 2158936064 ODIEDD_Data5Value "Open Display Interface Enum Dynamic Data : Data ID 5";
BA_ "VNSigAllNodes" SG_ 2158936064 ODIEDD_Data5Value 1;
BA_ "GenSigDeltaValue" SG_ 2158936064 ODIEDD_Data4Value 1;
BA_ "GenSigSendType" SG_ 2158936064 ODIEDD_Data4Value 12;
BA_ "GenSigSendOnInit" SG_ 2158936064 ODIEDD_Data4Value 1;
BA_ "VNSigInfotainment" SG_ 2158936064 ODIEDD_Data4Value 1;
BA_ "SignalType" SG_ 2158936064 ODIEDD_Data4Value "UNM";
BA_ "PacketOrder" SG_ 2158936064 ODIEDD_Data4Value 4;
BA_ "SignalLongName" SG_ 2158936064 ODIEDD_Data4Value "Open Display Interface Enum Dynamic Data : Data ID 4";
BA_ "VNSigAllNodes" SG_ 2158936064 ODIEDD_Data4Value 1;
BA_ "GenSigDeltaValue" SG_ 2158936064 ODIEDD_Data3Value 1;
BA_ "GenSigSendType" SG_ 2158936064 ODIEDD_Data3Value 12;
BA_ "GenSigSendOnInit" SG_ 2158936064 ODIEDD_Data3Value 1;
BA_ "VNSigInfotainment" SG_ 2158936064 ODIEDD_Data3Value 1;
BA_ "SignalType" SG_ 2158936064 ODIEDD_Data3Value "UNM";
BA_ "PacketOrder" SG_ 2158936064 ODIEDD_Data3Value 3;
BA_ "SignalLongName" SG_ 2158936064 ODIEDD_Data3Value "Open Display Interface Enum Dynamic Data : Data ID 3";
BA_ "VNSigAllNodes" SG_ 2158936064 ODIEDD_Data3Value 1;
BA_ "GenSigDeltaValue" SG_ 2158936064 ODIEDD_Data2Value 1;
BA_ "GenSigSendType" SG_ 2158936064 ODIEDD_Data2Value 12;
BA_ "GenSigSendOnInit" SG_ 2158936064 ODIEDD_Data2Value 1;
BA_ "VNSigInfotainment" SG_ 2158936064 ODIEDD_Data2Value 1;
BA_ "SignalType" SG_ 2158936064 ODIEDD_Data2Value "UNM";
BA_ "PacketOrder" SG_ 2158936064 ODIEDD_Data2Value 2;
BA_ "SignalLongName" SG_ 2158936064 ODIEDD_Data2Value "Open Display Interface Enum Dynamic Data : Data ID 2";
BA_ "VNSigAllNodes" SG_ 2158936064 ODIEDD_Data2Value 1;
BA_ "GenSigDeltaValue" SG_ 2158936064 ODIEDD_Data1Value 1;
BA_ "GenSigSendType" SG_ 2158936064 ODIEDD_Data1Value 12;
BA_ "GenSigSendOnInit" SG_ 2158936064 ODIEDD_Data1Value 1;
BA_ "VNSigInfotainment" SG_ 2158936064 ODIEDD_Data1Value 1;
BA_ "SignalType" SG_ 2158936064 ODIEDD_Data1Value "UNM";
BA_ "PacketOrder" SG_ 2158936064 ODIEDD_Data1Value 1;
BA_ "SignalLongName" SG_ 2158936064 ODIEDD_Data1Value "Open Display Interface Enum Dynamic Data : Data ID 1";
BA_ "VNSigAllNodes" SG_ 2158936064 ODIEDD_Data1Value 1;
BA_ "GenSigDeltaValue" SG_ 2158936064 ODIEDD_FUCID 1;
BA_ "GenSigSendType" SG_ 2158936064 ODIEDD_FUCID 12;
BA_ "GenSigSendOnInit" SG_ 2158936064 ODIEDD_FUCID 1;
BA_ "VNSigInfotainment" SG_ 2158936064 ODIEDD_FUCID 1;
BA_ "SignalType" SG_ 2158936064 ODIEDD_FUCID "UNM";
BA_ "PacketOrder" SG_ 2158936064 ODIEDD_FUCID 19;
BA_ "SignalLongName" SG_ 2158936064 ODIEDD_FUCID "Open Display Interface Enum Dynamic Data : Functional Unit Class ID";
BA_ "VNSigAllNodes" SG_ 2158936064 ODIEDD_FUCID 1;
BA_ "GenSigDeltaValue" SG_ 2158845952 ODIAC_FUCID 1;
BA_ "GenSigSendType" SG_ 2158845952 ODIAC_FUCID 12;
BA_ "VNSigInfotainment" SG_ 2158845952 ODIAC_FUCID 1;
BA_ "SignalType" SG_ 2158845952 ODIAC_FUCID "UNM";
BA_ "PacketOrder" SG_ 2158845952 ODIAC_FUCID 2;
BA_ "SignalLongName" SG_ 2158845952 ODIAC_FUCID "Open Display Interface Action CenterStack : FU Class ID";
BA_ "VNSigAllNodes" SG_ 2158845952 ODIAC_FUCID 1;
BA_ "GenSigSendType" SG_ 2158845952 ODIAC_DspMID 10;
BA_ "VNSigInfotainment" SG_ 2158845952 ODIAC_DspMID 1;
BA_ "SignalType" SG_ 2158845952 ODIAC_DspMID "ENM";
BA_ "PacketOrder" SG_ 2158845952 ODIAC_DspMID 4;
BA_ "SignalLongName" SG_ 2158845952 ODIAC_DspMID "Open Display Interface Action CenterStack : Display Mask ID";
BA_ "VNSigAllNodes" SG_ 2158845952 ODIAC_DspMID 1;
BA_ "GenSigDeltaValue" SG_ 2158845952 ODIAC_DaTy 1;
BA_ "GenSigSendType" SG_ 2158845952 ODIAC_DaTy 10;
BA_ "VNSigInfotainment" SG_ 2158845952 ODIAC_DaTy 1;
BA_ "SignalType" SG_ 2158845952 ODIAC_DaTy "ENM";
BA_ "PacketOrder" SG_ 2158845952 ODIAC_DaTy 1;
BA_ "SignalLongName" SG_ 2158845952 ODIAC_DaTy "Open Display Interface Action CenterStack : DataType";
BA_ "VNSigAllNodes" SG_ 2158845952 ODIAC_DaTy 1;
BA_ "GenSigDeltaValue" SG_ 2158845952 ODIAC_ActnVal 1;
BA_ "GenSigSendType" SG_ 2158845952 ODIAC_ActnVal 12;
BA_ "VNSigInfotainment" SG_ 2158845952 ODIAC_ActnVal 1;
BA_ "SignalType" SG_ 2158845952 ODIAC_ActnVal "UNM";
BA_ "PacketOrder" SG_ 2158845952 ODIAC_ActnVal 5;
BA_ "SignalLongName" SG_ 2158845952 ODIAC_ActnVal "Open Display Interface Action CenterStack : Action Value";
BA_ "VNSigAllNodes" SG_ 2158845952 ODIAC_ActnVal 1;
BA_ "GenSigDeltaValue" SG_ 2158845952 ODIAC_ActnID 1;
BA_ "GenSigSendType" SG_ 2158845952 ODIAC_ActnID 12;
BA_ "VNSigInfotainment" SG_ 2158845952 ODIAC_ActnID 1;
BA_ "SignalType" SG_ 2158845952 ODIAC_ActnID "UNM";
BA_ "PacketOrder" SG_ 2158845952 ODIAC_ActnID 3;
BA_ "SignalLongName" SG_ 2158845952 ODIAC_ActnID "Open Display Interface Action CenterStack : Action ID";
BA_ "VNSigAllNodes" SG_ 2158845952 ODIAC_ActnID 1;
BA_ "GenSigDeltaValue" SG_ 2158886912 ODDLI_SubIdReqM 1;
BA_ "GenSigSendType" SG_ 2158886912 ODDLI_SubIdReqM 12;
BA_ "VNSigInfotainment" SG_ 2158886912 ODDLI_SubIdReqM 1;
BA_ "SignalType" SG_ 2158886912 ODDLI_SubIdReqM "UNM";
BA_ "PacketOrder" SG_ 2158886912 ODDLI_SubIdReqM 10;
BA_ "SignalLongName" SG_ 2158886912 ODDLI_SubIdReqM "Open Display Interface Dynamic Data List Request IPC : Sub Id Request Mask";
BA_ "VNSigAllNodes" SG_ 2158886912 ODDLI_SubIdReqM 1;
BA_ "GenSigSendType" SG_ 2158886912 ODDLI_WrpArnd 10;
BA_ "VNSigInfotainment" SG_ 2158886912 ODDLI_WrpArnd 1;
BA_ "SignalType" SG_ 2158886912 ODDLI_WrpArnd "BLN";
BA_ "PacketOrder" SG_ 2158886912 ODDLI_WrpArnd 9;
BA_ "SignalLongName" SG_ 2158886912 ODDLI_WrpArnd "Open Display Interface Dynamic Data List Request IPC : Wrap Around";
BA_ "VNSigAllNodes" SG_ 2158886912 ODDLI_WrpArnd 1;
BA_ "GenSigSendType" SG_ 2158886912 ODDLI_ReqType 10;
BA_ "VNSigInfotainment" SG_ 2158886912 ODDLI_ReqType 1;
BA_ "SignalType" SG_ 2158886912 ODDLI_ReqType "ENM";
BA_ "PacketOrder" SG_ 2158886912 ODDLI_ReqType 7;
BA_ "SignalLongName" SG_ 2158886912 ODDLI_ReqType "Open Display Interface Dynamic Data List Request IPC : Request Type";
BA_ "VNSigAllNodes" SG_ 2158886912 ODDLI_ReqType 1;
BA_ "GenSigSendType" SG_ 2158886912 ODDLI_ReqDir 10;
BA_ "VNSigInfotainment" SG_ 2158886912 ODDLI_ReqDir 1;
BA_ "SignalType" SG_ 2158886912 ODDLI_ReqDir "BLN";
BA_ "PacketOrder" SG_ 2158886912 ODDLI_ReqDir 5;
BA_ "SignalLongName" SG_ 2158886912 ODDLI_ReqDir "Open Display Interface Dynamic Data List Request IPC : Req Direction";
BA_ "VNSigAllNodes" SG_ 2158886912 ODDLI_ReqDir 1;
BA_ "GenSigDeltaValue" SG_ 2158886912 ODDLI_NmEntries 1;
BA_ "GenSigSendType" SG_ 2158886912 ODDLI_NmEntries 12;
BA_ "VNSigInfotainment" SG_ 2158886912 ODDLI_NmEntries 1;
BA_ "SignalType" SG_ 2158886912 ODDLI_NmEntries "UNM";
BA_ "PacketOrder" SG_ 2158886912 ODDLI_NmEntries 4;
BA_ "SignalLongName" SG_ 2158886912 ODDLI_NmEntries "Open Display Interface Dynamic Data List Request IPC : Num Entries";
BA_ "VNSigAllNodes" SG_ 2158886912 ODDLI_NmEntries 1;
BA_ "GenSigDeltaValue" SG_ 2158886912 ODDLI_Idx 1;
BA_ "GenSigSendType" SG_ 2158886912 ODDLI_Idx 12;
BA_ "VNSigInfotainment" SG_ 2158886912 ODDLI_Idx 1;
BA_ "SignalType" SG_ 2158886912 ODDLI_Idx "UNM";
BA_ "PacketOrder" SG_ 2158886912 ODDLI_Idx 6;
BA_ "SignalLongName" SG_ 2158886912 ODDLI_Idx "Open Display Interface Dynamic Data List Request IPC : Index";
BA_ "VNSigAllNodes" SG_ 2158886912 ODDLI_Idx 1;
BA_ "GenSigDeltaValue" SG_ 2158886912 ODDLI_FUCID 1;
BA_ "GenSigSendType" SG_ 2158886912 ODDLI_FUCID 12;
BA_ "VNSigInfotainment" SG_ 2158886912 ODDLI_FUCID 1;
BA_ "SignalType" SG_ 2158886912 ODDLI_FUCID "UNM";
BA_ "PacketOrder" SG_ 2158886912 ODDLI_FUCID 1;
BA_ "SignalLongName" SG_ 2158886912 ODDLI_FUCID "Open Display Interface Dynamic Data List Request IPC : Functional Unit Class ID";
BA_ "VNSigAllNodes" SG_ 2158886912 ODDLI_FUCID 1;
BA_ "GenSigSendType" SG_ 2158886912 ODDLI_DspMID 10;
BA_ "VNSigInfotainment" SG_ 2158886912 ODDLI_DspMID 1;
BA_ "SignalType" SG_ 2158886912 ODDLI_DspMID "ENM";
BA_ "PacketOrder" SG_ 2158886912 ODDLI_DspMID 3;
BA_ "SignalLongName" SG_ 2158886912 ODDLI_DspMID "Open Display Interface Dynamic Data List Request IPC : Display Mask Id";
BA_ "VNSigAllNodes" SG_ 2158886912 ODDLI_DspMID 1;
BA_ "GenSigDeltaValue" SG_ 2158886912 ODDLI_DataId 1;
BA_ "GenSigSendType" SG_ 2158886912 ODDLI_DataId 12;
BA_ "VNSigInfotainment" SG_ 2158886912 ODDLI_DataId 1;
BA_ "SignalType" SG_ 2158886912 ODDLI_DataId "UNM";
BA_ "PacketOrder" SG_ 2158886912 ODDLI_DataId 2;
BA_ "SignalLongName" SG_ 2158886912 ODDLI_DataId "Open Display Interface Dynamic Data List Request IPC : Data Id";
BA_ "VNSigAllNodes" SG_ 2158886912 ODDLI_DataId 1;
BA_ "GenSigSendType" SG_ 2158886912 ODDLI_BckgndFlag 10;
BA_ "VNSigInfotainment" SG_ 2158886912 ODDLI_BckgndFlag 1;
BA_ "SignalType" SG_ 2158886912 ODDLI_BckgndFlag "ENM";
BA_ "PacketOrder" SG_ 2158886912 ODDLI_BckgndFlag 8;
BA_ "SignalLongName" SG_ 2158886912 ODDLI_BckgndFlag "Open Display Interface Dynamic Data List Request IPC : Background Flag";
BA_ "VNSigAllNodes" SG_ 2158886912 ODDLI_BckgndFlag 1;
BA_ "VNSigPrimaryTriggering" SG_ 1596 VectraSpcNWMgtD 1;
BA_ "VNSigRemoteDiagnostics" SG_ 1596 VectraSpcNWMgtD 1;
BA_ "VNSigInfotainment" SG_ 1596 VectraSpcNWMgtD 1;
BA_ "VNSigParkedVehicle" SG_ 1596 VectraSpcNWMgtD 1;
BA_ "VNSigIntermediate" SG_ 1596 VectraSpcNWMgtD 1;
BA_ "VNSigUnused_4" SG_ 1596 VectraSpcNWMgtD 1;
BA_ "SignalType" SG_ 1596 VectraSpcNWMgtD "UNM";
BA_ "SignalLongName" SG_ 1596 VectraSpcNWMgtD "Vectra Specific Network Management Data";
BA_ "VNSigDiagnostic" SG_ 1596 VectraSpcNWMgtD 1;
BA_ "VNSigAllNodes" SG_ 1596 VectraSpcNWMgtD 1;
BA_ "GenSigSendType" SG_ 2151366656 AxlLcksVDA 10;
BA_ "SignalType" SG_ 2151366656 AxlLcksVDA "ENM";
BA_ "SignalLongName" SG_ 2151366656 AxlLcksVDA "Axle Locks Virtual Device Availability";
BA_ "GenSigStartValue" SG_ 2151366656 AxlLcksVDA 1;
BA_ "VNSigAllNodes" SG_ 2151366656 AxlLcksVDA 1;
BA_ "GenSigSendType" SG_ 2151366656 AxlLckUnavailIndReq 10;
BA_ "SignalType" SG_ 2151366656 AxlLckUnavailIndReq "ENM";
BA_ "SignalLongName" SG_ 2151366656 AxlLckUnavailIndReq "Axle Locks Unavailable Indication Request";
BA_ "VNSigAllNodes" SG_ 2151366656 AxlLckUnavailIndReq 1;
BA_ "GenSigSendType" SG_ 2151366656 AxlLcksServIO 10;
BA_ "SignalType" SG_ 2151366656 AxlLcksServIO "BLN";
BA_ "SignalLongName" SG_ 2151366656 AxlLcksServIO "Axle Locks Service Indication On";
BA_ "VNSigAllNodes" SG_ 2151366656 AxlLcksServIO 1;
BA_ "GenSigSendType" SG_ 2151366656 RrAxlLckIO 10;
BA_ "SignalType" SG_ 2151366656 RrAxlLckIO "BLN";
BA_ "SignalLongName" SG_ 2151366656 RrAxlLckIO "Rear Axle Lock Indication On";
BA_ "VNSigAllNodes" SG_ 2151366656 RrAxlLckIO 1;
BA_ "GenSigSendType" SG_ 2151366656 FrntAxlLckIO 10;
BA_ "SignalType" SG_ 2151366656 FrntAxlLckIO "BLN";
BA_ "SignalLongName" SG_ 2151366656 FrntAxlLckIO "Front Axle Lock Indication On";
BA_ "VNSigAllNodes" SG_ 2151366656 FrntAxlLckIO 1;
BA_ "GenSigSendType" SG_ 2151366656 PrkBrkSwAtv 10;
BA_ "GenSigSendOnInit" SG_ 2151366656 PrkBrkSwAtv 1;
BA_ "SignalType" SG_ 2151366656 PrkBrkSwAtv "BLN";
BA_ "SignalLongName" SG_ 2151366656 PrkBrkSwAtv "Park Brake Switch Active";
BA_ "VNSigAllNodes" SG_ 2151366656 PrkBrkSwAtv 1;
BA_ "SignalType" SG_ 2149842944 AdptDrvrSeatStng "ENM";
BA_ "SignalLongName" SG_ 2149842944 AdptDrvrSeatStng "Adaptive Driver Seat Setting";
BA_ "VNSigAllNodes" SG_ 2149842944 AdptDrvrSeatStng 1;
BA_ "SignalType" SG_ 2149842944 IMUProtLonAccV "ENM";
BA_ "SignalLongName" SG_ 2149842944 IMUProtLonAccV "Inertial Measurement Unit Protected Longitudinal Acceleration Validity";
BA_ "VNSigAllNodes" SG_ 2149842944 IMUProtLonAccV 1;
BA_ "SignalType" SG_ 2149842944 IMUProtLonAcc "SNM";
BA_ "SignalLongName" SG_ 2149842944 IMUProtLonAcc "Inertial Measurement Unit Protected Longitudinal Acceleration";
BA_ "VNSigAllNodes" SG_ 2149842944 IMUProtLonAcc 1;
BA_ "SignalType" SG_ 2149842944 VSELatAccV "ENM";
BA_ "SignalLongName" SG_ 2149842944 VSELatAccV "Vehicle Stability Enhancement Lateral Acceleration Validity";
BA_ "VNSigAllNodes" SG_ 2149842944 VSELatAccV 1;
BA_ "SignalType" SG_ 2149842944 VSELatAcc "SNM";
BA_ "SignalLongName" SG_ 2149842944 VSELatAcc "Vehicle Stability Enhancement Lateral Acceleration";
BA_ "VNSigAllNodes" SG_ 2149842944 VSELatAcc 1;
BA_ "SignalType" SG_ 2149842944 StrWhAngV "ENM";
BA_ "SignalLongName" SG_ 2149842944 StrWhAngV "Steering Wheel Angle Validity";
BA_ "VNSigAllNodes" SG_ 2149842944 StrWhAngV 1;
BA_ "SignalType" SG_ 2149842944 TCSysAtv "BLN";
BA_ "SignalLongName" SG_ 2149842944 TCSysAtv "Traction Control System Active";
BA_ "VNSigAllNodes" SG_ 2149842944 TCSysAtv 1;
BA_ "SignalType" SG_ 2149842944 BrkSysAutBrkFld "BLN";
BA_ "SignalLongName" SG_ 2149842944 BrkSysAutBrkFld "Brake System Automatic Braking Failed";
BA_ "VNSigAllNodes" SG_ 2149842944 BrkSysAutBrkFld 1;
BA_ "SignalType" SG_ 2149842944 StrWhlAngSenCalStat "ENM";
BA_ "SignalLongName" SG_ 2149842944 StrWhlAngSenCalStat "Steering Wheel Angle Sensor Calibration Status";
BA_ "VNSigAllNodes" SG_ 2149842944 StrWhlAngSenCalStat 1;
BA_ "SignalType" SG_ 2149842944 VehStabEnhmntStat "ENM";
BA_ "SignalLongName" SG_ 2149842944 VehStabEnhmntStat "Vehicle Stability Enhancement Status";
BA_ "VNSigAllNodes" SG_ 2149842944 VehStabEnhmntStat 1;
BA_ "SignalType" SG_ 2149842944 VehStabEnhmntMd "ENM";
BA_ "SignalLongName" SG_ 2149842944 VehStabEnhmntMd "Vehicle Stability Enhancement Mode";
BA_ "VNSigAllNodes" SG_ 2149842944 VehStabEnhmntMd 1;
BA_ "SignalType" SG_ 2149842944 VSEAct "BLN";
BA_ "SignalLongName" SG_ 2149842944 VSEAct "Vehicle Stability Enhancement System Active";
BA_ "VNSigAllNodes" SG_ 2149842944 VSEAct 1;
BA_ "SignalType" SG_ 2149842944 TCSysOpStat "ENM";
BA_ "SignalLongName" SG_ 2149842944 TCSysOpStat "Traction Control System Operating Status";
BA_ "VNSigAllNodes" SG_ 2149842944 TCSysOpStat 1;
BA_ "SignalType" SG_ 2149842944 TCSysOpMd "ENM";
BA_ "SignalLongName" SG_ 2149842944 TCSysOpMd "Traction Control System Operating Mode";
BA_ "VNSigAllNodes" SG_ 2149842944 TCSysOpMd 1;
BA_ "SignalType" SG_ 2149842944 StWhAnVDA "ENM";
BA_ "SignalLongName" SG_ 2149842944 StWhAnVDA "Steering Wheel Angle Virtual Device Availability";
BA_ "GenSigStartValue" SG_ 2149842944 StWhAnVDA 1;
BA_ "VNSigAllNodes" SG_ 2149842944 StWhAnVDA 1;
BA_ "SignalType" SG_ 2149842944 StrWhAng "SNM";
BA_ "SignalLongName" SG_ 2149842944 StrWhAng "Steering Wheel Angle";
BA_ "VNSigAllNodes" SG_ 2149842944 StrWhAng 1;
BA_ "SignalType" SG_ 1603 DgnInf "UNM";
BA_ "SignalLongName" SG_ 1603 DgnInf "Diagnostic Information";
BA_ "VNSigDiagnostic" SG_ 1603 DgnInf 1;
BA_ "VNSigAllNodes" SG_ 1603 DgnInf 1;
BA_ "VNSigPrimaryTriggering" SG_ 1574 VectraSpcNWMgtD 1;
BA_ "VNSigRemoteDiagnostics" SG_ 1574 VectraSpcNWMgtD 1;
BA_ "VNSigInfotainment" SG_ 1574 VectraSpcNWMgtD 1;
BA_ "VNSigParkedVehicle" SG_ 1574 VectraSpcNWMgtD 1;
BA_ "VNSigIntermediate" SG_ 1574 VectraSpcNWMgtD 1;
BA_ "VNSigUnused_4" SG_ 1574 VectraSpcNWMgtD 1;
BA_ "SignalType" SG_ 1574 VectraSpcNWMgtD "UNM";
BA_ "SignalLongName" SG_ 1574 VectraSpcNWMgtD "Vectra Specific Network Management Data";
BA_ "VNSigDiagnostic" SG_ 1574 VectraSpcNWMgtD 1;
BA_ "VNSigAllNodes" SG_ 1574 VectraSpcNWMgtD 1;
BA_ "VNSigPrimaryTriggering" SG_ 1571 VectraSpcNWMgtD 1;
BA_ "VNSigRemoteDiagnostics" SG_ 1571 VectraSpcNWMgtD 1;
BA_ "VNSigInfotainment" SG_ 1571 VectraSpcNWMgtD 1;
BA_ "VNSigParkedVehicle" SG_ 1571 VectraSpcNWMgtD 1;
BA_ "VNSigIntermediate" SG_ 1571 VectraSpcNWMgtD 1;
BA_ "VNSigUnused_4" SG_ 1571 VectraSpcNWMgtD 1;
BA_ "SignalType" SG_ 1571 VectraSpcNWMgtD "UNM";
BA_ "SignalLongName" SG_ 1571 VectraSpcNWMgtD "Vectra Specific Network Management Data";
BA_ "VNSigDiagnostic" SG_ 1571 VectraSpcNWMgtD 1;
BA_ "VNSigAllNodes" SG_ 1571 VectraSpcNWMgtD 1;
BA_ "SignalType" SG_ 1347 DgnInf_LS543 "UNM";
BA_ "SignalLongName" SG_ 1347 DgnInf_LS543 "Diagnostic Information LS543";
BA_ "VNSigDiagnostic" SG_ 1347 DgnInf_LS543 1;
BA_ "VNSigAllNodes" SG_ 1347 DgnInf_LS543 1;
BA_ "SignalType" SG_ 582 DgnInf "UNM";
BA_ "SignalLongName" SG_ 582 DgnInf "Diagnostic Information";
BA_ "VNSigDiagnostic" SG_ 582 DgnInf 1;
BA_ "VNSigAllNodes" SG_ 582 DgnInf 1;
BA_ "SignalType" SG_ 579 DgnInf "UNM";
BA_ "SignalLongName" SG_ 579 DgnInf "Diagnostic Information";
BA_ "VNSigDiagnostic" SG_ 579 DgnInf 1;
BA_ "VNSigAllNodes" SG_ 579 DgnInf 1;
BA_ "VNSigPrimaryTriggering" SG_ 1577 VectraSpcNWMgtD 1;
BA_ "VNSigRemoteDiagnostics" SG_ 1577 VectraSpcNWMgtD 1;
BA_ "VNSigInfotainment" SG_ 1577 VectraSpcNWMgtD 1;
BA_ "VNSigParkedVehicle" SG_ 1577 VectraSpcNWMgtD 1;
BA_ "VNSigIntermediate" SG_ 1577 VectraSpcNWMgtD 1;
BA_ "VNSigUnused_4" SG_ 1577 VectraSpcNWMgtD 1;
BA_ "SignalType" SG_ 1577 VectraSpcNWMgtD "UNM";
BA_ "SignalLongName" SG_ 1577 VectraSpcNWMgtD "Vectra Specific Network Management Data";
BA_ "VNSigDiagnostic" SG_ 1577 VectraSpcNWMgtD 1;
BA_ "VNSigAllNodes" SG_ 1577 VectraSpcNWMgtD 1;
BA_ "SignalType" SG_ 1609 DgnInf "UNM";
BA_ "SignalLongName" SG_ 1609 DgnInf "Diagnostic Information";
BA_ "VNSigDiagnostic" SG_ 1609 DgnInf 1;
BA_ "VNSigAllNodes" SG_ 1609 DgnInf 1;
BA_ "GenSigDeltaValue" SG_ 2159132672 ODIAR_FUCID 1;
BA_ "GenSigSendType" SG_ 2159132672 ODIAR_FUCID 12;
BA_ "VNSigInfotainment" SG_ 2159132672 ODIAR_FUCID 1;
BA_ "SignalType" SG_ 2159132672 ODIAR_FUCID "UNM";
BA_ "PacketOrder" SG_ 2159132672 ODIAR_FUCID 2;
BA_ "SignalLongName" SG_ 2159132672 ODIAR_FUCID "Open Display Interface Action Rear Seat Display : FU Class ID";
BA_ "VNSigAllNodes" SG_ 2159132672 ODIAR_FUCID 1;
BA_ "GenSigSendType" SG_ 2159132672 ODIAR_DspMID 10;
BA_ "VNSigInfotainment" SG_ 2159132672 ODIAR_DspMID 1;
BA_ "SignalType" SG_ 2159132672 ODIAR_DspMID "ENM";
BA_ "PacketOrder" SG_ 2159132672 ODIAR_DspMID 4;
BA_ "SignalLongName" SG_ 2159132672 ODIAR_DspMID "Open Display Interface Action Rear Seat Display : Display Mask ID";
BA_ "VNSigAllNodes" SG_ 2159132672 ODIAR_DspMID 1;
BA_ "GenSigDeltaValue" SG_ 2159132672 ODIAR_DaTy 1;
BA_ "GenSigSendType" SG_ 2159132672 ODIAR_DaTy 10;
BA_ "VNSigInfotainment" SG_ 2159132672 ODIAR_DaTy 1;
BA_ "SignalType" SG_ 2159132672 ODIAR_DaTy "ENM";
BA_ "PacketOrder" SG_ 2159132672 ODIAR_DaTy 1;
BA_ "SignalLongName" SG_ 2159132672 ODIAR_DaTy "Open Display Interface Action Rear Seat Display : DataType";
BA_ "VNSigAllNodes" SG_ 2159132672 ODIAR_DaTy 1;
BA_ "GenSigDeltaValue" SG_ 2159132672 ODIAR_ActnVal 1;
BA_ "GenSigSendType" SG_ 2159132672 ODIAR_ActnVal 12;
BA_ "VNSigInfotainment" SG_ 2159132672 ODIAR_ActnVal 1;
BA_ "SignalType" SG_ 2159132672 ODIAR_ActnVal "UNM";
BA_ "PacketOrder" SG_ 2159132672 ODIAR_ActnVal 5;
BA_ "SignalLongName" SG_ 2159132672 ODIAR_ActnVal "Open Display Interface Action Rear Seat Display : Action Value";
BA_ "VNSigAllNodes" SG_ 2159132672 ODIAR_ActnVal 1;
BA_ "GenSigDeltaValue" SG_ 2159132672 ODIAR_ActnID 1;
BA_ "GenSigSendType" SG_ 2159132672 ODIAR_ActnID 12;
BA_ "VNSigInfotainment" SG_ 2159132672 ODIAR_ActnID 1;
BA_ "SignalType" SG_ 2159132672 ODIAR_ActnID "UNM";
BA_ "PacketOrder" SG_ 2159132672 ODIAR_ActnID 3;
BA_ "SignalLongName" SG_ 2159132672 ODIAR_ActnID "Open Display Interface Action Rear Seat Display : Action ID";
BA_ "VNSigAllNodes" SG_ 2159132672 ODIAR_ActnID 1;
BA_ "GenSigDeltaValue" SG_ 2158968832 ODI_RSD2CntrStck 1;
BA_ "GenSigSendType" SG_ 2158968832 ODI_RSD2CntrStck 12;
BA_ "VNSigInfotainment" SG_ 2158968832 ODI_RSD2CntrStck 1;
BA_ "SignalType" SG_ 2158968832 ODI_RSD2CntrStck "UNM";
BA_ "SignalLongName" SG_ 2158968832 ODI_RSD2CntrStck "Open Display Interface Rear Seat Display 2 Centerstack";
BA_ "VNSigAllNodes" SG_ 2158968832 ODI_RSD2CntrStck 1;
BA_ "GenSigDeltaValue" SG_ 2158960640 ODIIC_FUCID 1;
BA_ "GenSigSendType" SG_ 2158960640 ODIIC_FUCID 12;
BA_ "GenSigSendOnInit" SG_ 2158960640 ODIIC_FUCID 1;
BA_ "VNSigInfotainment" SG_ 2158960640 ODIIC_FUCID 1;
BA_ "SignalType" SG_ 2158960640 ODIIC_FUCID "UNM";
BA_ "PacketOrder" SG_ 2158960640 ODIIC_FUCID 1;
BA_ "SignalLongName" SG_ 2158960640 ODIIC_FUCID "Open Display Interface Indication Centerstack: Functional Unit Class ID";
BA_ "VNSigAllNodes" SG_ 2158960640 ODIIC_FUCID 1;
BA_ "GenSigSendType" SG_ 2158960640 ODIIC_ODIInd9 10;
BA_ "GenSigSendOnInit" SG_ 2158960640 ODIIC_ODIInd9 1;
BA_ "VNSigInfotainment" SG_ 2158960640 ODIIC_ODIInd9 1;
BA_ "SignalType" SG_ 2158960640 ODIIC_ODIInd9 "BLN";
BA_ "PacketOrder" SG_ 2158960640 ODIIC_ODIInd9 10;
BA_ "SignalLongName" SG_ 2158960640 ODIIC_ODIInd9 "Open Display Interface Indication Centerstack : Open Display Interface Indication 9";
BA_ "VNSigAllNodes" SG_ 2158960640 ODIIC_ODIInd9 1;
BA_ "GenSigSendType" SG_ 2158960640 ODIIC_ODIInd8 10;
BA_ "GenSigSendOnInit" SG_ 2158960640 ODIIC_ODIInd8 1;
BA_ "VNSigInfotainment" SG_ 2158960640 ODIIC_ODIInd8 1;
BA_ "SignalType" SG_ 2158960640 ODIIC_ODIInd8 "BLN";
BA_ "PacketOrder" SG_ 2158960640 ODIIC_ODIInd8 9;
BA_ "SignalLongName" SG_ 2158960640 ODIIC_ODIInd8 "Open Display Interface Indication Centerstack : Open Display Interface Indication 8";
BA_ "VNSigAllNodes" SG_ 2158960640 ODIIC_ODIInd8 1;
BA_ "GenSigSendType" SG_ 2158960640 ODIIC_ODIInd7 10;
BA_ "GenSigSendOnInit" SG_ 2158960640 ODIIC_ODIInd7 1;
BA_ "VNSigInfotainment" SG_ 2158960640 ODIIC_ODIInd7 1;
BA_ "SignalType" SG_ 2158960640 ODIIC_ODIInd7 "BLN";
BA_ "PacketOrder" SG_ 2158960640 ODIIC_ODIInd7 8;
BA_ "SignalLongName" SG_ 2158960640 ODIIC_ODIInd7 "Open Display Interface Indication Centerstack : Open Display Interface Indication 7";
BA_ "VNSigAllNodes" SG_ 2158960640 ODIIC_ODIInd7 1;
BA_ "GenSigSendType" SG_ 2158960640 ODIIC_ODIInd6 10;
BA_ "GenSigSendOnInit" SG_ 2158960640 ODIIC_ODIInd6 1;
BA_ "VNSigInfotainment" SG_ 2158960640 ODIIC_ODIInd6 1;
BA_ "SignalType" SG_ 2158960640 ODIIC_ODIInd6 "BLN";
BA_ "PacketOrder" SG_ 2158960640 ODIIC_ODIInd6 7;
BA_ "SignalLongName" SG_ 2158960640 ODIIC_ODIInd6 "Open Display Interface Indication Centerstack : Open Display Interface Indication 6";
BA_ "VNSigAllNodes" SG_ 2158960640 ODIIC_ODIInd6 1;
BA_ "GenSigSendType" SG_ 2158960640 ODIIC_ODIInd56 10;
BA_ "GenSigSendOnInit" SG_ 2158960640 ODIIC_ODIInd56 1;
BA_ "VNSigInfotainment" SG_ 2158960640 ODIIC_ODIInd56 1;
BA_ "SignalType" SG_ 2158960640 ODIIC_ODIInd56 "BLN";
BA_ "PacketOrder" SG_ 2158960640 ODIIC_ODIInd56 57;
BA_ "SignalLongName" SG_ 2158960640 ODIIC_ODIInd56 "Open Display Interface Indication Centerstack : Open Display Interface Indication 56";
BA_ "VNSigAllNodes" SG_ 2158960640 ODIIC_ODIInd56 1;
BA_ "GenSigSendType" SG_ 2158960640 ODIIC_ODIInd55 10;
BA_ "GenSigSendOnInit" SG_ 2158960640 ODIIC_ODIInd55 1;
BA_ "VNSigInfotainment" SG_ 2158960640 ODIIC_ODIInd55 1;
BA_ "SignalType" SG_ 2158960640 ODIIC_ODIInd55 "BLN";
BA_ "PacketOrder" SG_ 2158960640 ODIIC_ODIInd55 56;
BA_ "SignalLongName" SG_ 2158960640 ODIIC_ODIInd55 "Open Display Interface Indication Centerstack : Open Display Interface Indication 55";
BA_ "VNSigAllNodes" SG_ 2158960640 ODIIC_ODIInd55 1;
BA_ "GenSigSendType" SG_ 2158960640 ODIIC_ODIInd54 10;
BA_ "GenSigSendOnInit" SG_ 2158960640 ODIIC_ODIInd54 1;
BA_ "VNSigInfotainment" SG_ 2158960640 ODIIC_ODIInd54 1;
BA_ "SignalType" SG_ 2158960640 ODIIC_ODIInd54 "BLN";
BA_ "PacketOrder" SG_ 2158960640 ODIIC_ODIInd54 55;
BA_ "SignalLongName" SG_ 2158960640 ODIIC_ODIInd54 "Open Display Interface Indication Centerstack : Open Display Interface Indication 54";
BA_ "VNSigAllNodes" SG_ 2158960640 ODIIC_ODIInd54 1;
BA_ "GenSigSendType" SG_ 2158960640 ODIIC_ODIInd53 10;
BA_ "GenSigSendOnInit" SG_ 2158960640 ODIIC_ODIInd53 1;
BA_ "VNSigInfotainment" SG_ 2158960640 ODIIC_ODIInd53 1;
BA_ "SignalType" SG_ 2158960640 ODIIC_ODIInd53 "BLN";
BA_ "PacketOrder" SG_ 2158960640 ODIIC_ODIInd53 54;
BA_ "SignalLongName" SG_ 2158960640 ODIIC_ODIInd53 "Open Display Interface Indication Centerstack : Open Display Interface Indication 53";
BA_ "VNSigAllNodes" SG_ 2158960640 ODIIC_ODIInd53 1;
BA_ "GenSigSendType" SG_ 2158960640 ODIIC_ODIInd52 10;
BA_ "GenSigSendOnInit" SG_ 2158960640 ODIIC_ODIInd52 1;
BA_ "VNSigInfotainment" SG_ 2158960640 ODIIC_ODIInd52 1;
BA_ "SignalType" SG_ 2158960640 ODIIC_ODIInd52 "BLN";
BA_ "PacketOrder" SG_ 2158960640 ODIIC_ODIInd52 53;
BA_ "SignalLongName" SG_ 2158960640 ODIIC_ODIInd52 "Open Display Interface Indication Centerstack : Open Display Interface Indication 52";
BA_ "VNSigAllNodes" SG_ 2158960640 ODIIC_ODIInd52 1;
BA_ "GenSigSendType" SG_ 2158960640 ODIIC_ODIInd51 10;
BA_ "GenSigSendOnInit" SG_ 2158960640 ODIIC_ODIInd51 1;
BA_ "VNSigInfotainment" SG_ 2158960640 ODIIC_ODIInd51 1;
BA_ "SignalType" SG_ 2158960640 ODIIC_ODIInd51 "BLN";
BA_ "PacketOrder" SG_ 2158960640 ODIIC_ODIInd51 52;
BA_ "SignalLongName" SG_ 2158960640 ODIIC_ODIInd51 "Open Display Interface Indication Centerstack : Open Display Interface Indication 51";
BA_ "VNSigAllNodes" SG_ 2158960640 ODIIC_ODIInd51 1;
BA_ "GenSigSendType" SG_ 2158960640 ODIIC_ODIInd50 10;
BA_ "GenSigSendOnInit" SG_ 2158960640 ODIIC_ODIInd50 1;
BA_ "VNSigInfotainment" SG_ 2158960640 ODIIC_ODIInd50 1;
BA_ "SignalType" SG_ 2158960640 ODIIC_ODIInd50 "BLN";
BA_ "PacketOrder" SG_ 2158960640 ODIIC_ODIInd50 51;
BA_ "SignalLongName" SG_ 2158960640 ODIIC_ODIInd50 "Open Display Interface Indication Centerstack : Open Display Interface Indication 50";
BA_ "VNSigAllNodes" SG_ 2158960640 ODIIC_ODIInd50 1;
BA_ "GenSigSendType" SG_ 2158960640 ODIIC_ODIInd5 10;
BA_ "GenSigSendOnInit" SG_ 2158960640 ODIIC_ODIInd5 1;
BA_ "VNSigInfotainment" SG_ 2158960640 ODIIC_ODIInd5 1;
BA_ "SignalType" SG_ 2158960640 ODIIC_ODIInd5 "BLN";
BA_ "PacketOrder" SG_ 2158960640 ODIIC_ODIInd5 6;
BA_ "SignalLongName" SG_ 2158960640 ODIIC_ODIInd5 "Open Display Interface Indication Centerstack : Open Display Interface Indication 5";
BA_ "VNSigAllNodes" SG_ 2158960640 ODIIC_ODIInd5 1;
BA_ "GenSigSendType" SG_ 2158960640 ODIIC_ODIInd49 10;
BA_ "GenSigSendOnInit" SG_ 2158960640 ODIIC_ODIInd49 1;
BA_ "VNSigInfotainment" SG_ 2158960640 ODIIC_ODIInd49 1;
BA_ "SignalType" SG_ 2158960640 ODIIC_ODIInd49 "BLN";
BA_ "PacketOrder" SG_ 2158960640 ODIIC_ODIInd49 50;
BA_ "SignalLongName" SG_ 2158960640 ODIIC_ODIInd49 "Open Display Interface Indication Centerstack : Open Display Interface Indication 49";
BA_ "VNSigAllNodes" SG_ 2158960640 ODIIC_ODIInd49 1;
BA_ "GenSigSendType" SG_ 2158960640 ODIIC_ODIInd48 10;
BA_ "GenSigSendOnInit" SG_ 2158960640 ODIIC_ODIInd48 1;
BA_ "VNSigInfotainment" SG_ 2158960640 ODIIC_ODIInd48 1;
BA_ "SignalType" SG_ 2158960640 ODIIC_ODIInd48 "BLN";
BA_ "PacketOrder" SG_ 2158960640 ODIIC_ODIInd48 49;
BA_ "SignalLongName" SG_ 2158960640 ODIIC_ODIInd48 "Open Display Interface Indication Centerstack : Open Display Interface Indication 48";
BA_ "VNSigAllNodes" SG_ 2158960640 ODIIC_ODIInd48 1;
BA_ "GenSigSendType" SG_ 2158960640 ODIIC_ODIInd47 10;
BA_ "GenSigSendOnInit" SG_ 2158960640 ODIIC_ODIInd47 1;
BA_ "VNSigInfotainment" SG_ 2158960640 ODIIC_ODIInd47 1;
BA_ "SignalType" SG_ 2158960640 ODIIC_ODIInd47 "BLN";
BA_ "PacketOrder" SG_ 2158960640 ODIIC_ODIInd47 48;
BA_ "SignalLongName" SG_ 2158960640 ODIIC_ODIInd47 "Open Display Interface Indication Centerstack : Open Display Interface Indication 47";
BA_ "VNSigAllNodes" SG_ 2158960640 ODIIC_ODIInd47 1;
BA_ "GenSigSendType" SG_ 2158960640 ODIIC_ODIInd46 10;
BA_ "GenSigSendOnInit" SG_ 2158960640 ODIIC_ODIInd46 1;
BA_ "VNSigInfotainment" SG_ 2158960640 ODIIC_ODIInd46 1;
BA_ "SignalType" SG_ 2158960640 ODIIC_ODIInd46 "BLN";
BA_ "PacketOrder" SG_ 2158960640 ODIIC_ODIInd46 47;
BA_ "SignalLongName" SG_ 2158960640 ODIIC_ODIInd46 "Open Display Interface Indication Centerstack : Open Display Interface Indication 46";
BA_ "VNSigAllNodes" SG_ 2158960640 ODIIC_ODIInd46 1;
BA_ "GenSigSendType" SG_ 2158960640 ODIIC_ODIInd45 10;
BA_ "GenSigSendOnInit" SG_ 2158960640 ODIIC_ODIInd45 1;
BA_ "VNSigInfotainment" SG_ 2158960640 ODIIC_ODIInd45 1;
BA_ "SignalType" SG_ 2158960640 ODIIC_ODIInd45 "BLN";
BA_ "PacketOrder" SG_ 2158960640 ODIIC_ODIInd45 46;
BA_ "SignalLongName" SG_ 2158960640 ODIIC_ODIInd45 "Open Display Interface Indication Centerstack : Open Display Interface Indication 45";
BA_ "VNSigAllNodes" SG_ 2158960640 ODIIC_ODIInd45 1;
BA_ "GenSigSendType" SG_ 2158960640 ODIIC_ODIInd44 10;
BA_ "GenSigSendOnInit" SG_ 2158960640 ODIIC_ODIInd44 1;
BA_ "VNSigInfotainment" SG_ 2158960640 ODIIC_ODIInd44 1;
BA_ "SignalType" SG_ 2158960640 ODIIC_ODIInd44 "BLN";
BA_ "PacketOrder" SG_ 2158960640 ODIIC_ODIInd44 45;
BA_ "SignalLongName" SG_ 2158960640 ODIIC_ODIInd44 "Open Display Interface Indication Centerstack : Open Display Interface Indication 44";
BA_ "VNSigAllNodes" SG_ 2158960640 ODIIC_ODIInd44 1;
BA_ "GenSigSendType" SG_ 2158960640 ODIIC_ODIInd43 10;
BA_ "GenSigSendOnInit" SG_ 2158960640 ODIIC_ODIInd43 1;
BA_ "VNSigInfotainment" SG_ 2158960640 ODIIC_ODIInd43 1;
BA_ "SignalType" SG_ 2158960640 ODIIC_ODIInd43 "BLN";
BA_ "PacketOrder" SG_ 2158960640 ODIIC_ODIInd43 44;
BA_ "SignalLongName" SG_ 2158960640 ODIIC_ODIInd43 "Open Display Interface Indication Centerstack : Open Display Interface Indication 43";
BA_ "VNSigAllNodes" SG_ 2158960640 ODIIC_ODIInd43 1;
BA_ "GenSigSendType" SG_ 2158960640 ODIIC_ODIInd42 10;
BA_ "GenSigSendOnInit" SG_ 2158960640 ODIIC_ODIInd42 1;
BA_ "VNSigInfotainment" SG_ 2158960640 ODIIC_ODIInd42 1;
BA_ "SignalType" SG_ 2158960640 ODIIC_ODIInd42 "BLN";
BA_ "PacketOrder" SG_ 2158960640 ODIIC_ODIInd42 43;
BA_ "SignalLongName" SG_ 2158960640 ODIIC_ODIInd42 "Open Display Interface Indication Centerstack : Open Display Interface Indication 42";
BA_ "VNSigAllNodes" SG_ 2158960640 ODIIC_ODIInd42 1;
BA_ "GenSigSendType" SG_ 2158960640 ODIIC_ODIInd41 10;
BA_ "GenSigSendOnInit" SG_ 2158960640 ODIIC_ODIInd41 1;
BA_ "VNSigInfotainment" SG_ 2158960640 ODIIC_ODIInd41 1;
BA_ "SignalType" SG_ 2158960640 ODIIC_ODIInd41 "BLN";
BA_ "PacketOrder" SG_ 2158960640 ODIIC_ODIInd41 42;
BA_ "SignalLongName" SG_ 2158960640 ODIIC_ODIInd41 "Open Display Interface Indication Centerstack : Open Display Interface Indication 41";
BA_ "VNSigAllNodes" SG_ 2158960640 ODIIC_ODIInd41 1;
BA_ "GenSigSendType" SG_ 2158960640 ODIIC_ODIInd40 10;
BA_ "GenSigSendOnInit" SG_ 2158960640 ODIIC_ODIInd40 1;
BA_ "VNSigInfotainment" SG_ 2158960640 ODIIC_ODIInd40 1;
BA_ "SignalType" SG_ 2158960640 ODIIC_ODIInd40 "BLN";
BA_ "PacketOrder" SG_ 2158960640 ODIIC_ODIInd40 41;
BA_ "SignalLongName" SG_ 2158960640 ODIIC_ODIInd40 "Open Display Interface Indication Centerstack : Open Display Interface Indication 40";
BA_ "VNSigAllNodes" SG_ 2158960640 ODIIC_ODIInd40 1;
BA_ "GenSigSendType" SG_ 2158960640 ODIIC_ODIInd4 10;
BA_ "GenSigSendOnInit" SG_ 2158960640 ODIIC_ODIInd4 1;
BA_ "VNSigInfotainment" SG_ 2158960640 ODIIC_ODIInd4 1;
BA_ "SignalType" SG_ 2158960640 ODIIC_ODIInd4 "BLN";
BA_ "PacketOrder" SG_ 2158960640 ODIIC_ODIInd4 5;
BA_ "SignalLongName" SG_ 2158960640 ODIIC_ODIInd4 "Open Display Interface Indication Centerstack : Open Display Interface Indication 4";
BA_ "VNSigAllNodes" SG_ 2158960640 ODIIC_ODIInd4 1;
BA_ "GenSigSendType" SG_ 2158960640 ODIIC_ODIInd39 10;
BA_ "GenSigSendOnInit" SG_ 2158960640 ODIIC_ODIInd39 1;
BA_ "VNSigInfotainment" SG_ 2158960640 ODIIC_ODIInd39 1;
BA_ "SignalType" SG_ 2158960640 ODIIC_ODIInd39 "BLN";
BA_ "PacketOrder" SG_ 2158960640 ODIIC_ODIInd39 40;
BA_ "SignalLongName" SG_ 2158960640 ODIIC_ODIInd39 "Open Display Interface Indication Centerstack : Open Display Interface Indication 39";
BA_ "VNSigAllNodes" SG_ 2158960640 ODIIC_ODIInd39 1;
BA_ "GenSigSendType" SG_ 2158960640 ODIIC_ODIInd38 10;
BA_ "GenSigSendOnInit" SG_ 2158960640 ODIIC_ODIInd38 1;
BA_ "VNSigInfotainment" SG_ 2158960640 ODIIC_ODIInd38 1;
BA_ "SignalType" SG_ 2158960640 ODIIC_ODIInd38 "BLN";
BA_ "PacketOrder" SG_ 2158960640 ODIIC_ODIInd38 39;
BA_ "SignalLongName" SG_ 2158960640 ODIIC_ODIInd38 "Open Display Interface Indication Centerstack : Open Display Interface Indication 38";
BA_ "VNSigAllNodes" SG_ 2158960640 ODIIC_ODIInd38 1;
BA_ "GenSigSendType" SG_ 2158960640 ODIIC_ODIInd37 10;
BA_ "GenSigSendOnInit" SG_ 2158960640 ODIIC_ODIInd37 1;
BA_ "VNSigInfotainment" SG_ 2158960640 ODIIC_ODIInd37 1;
BA_ "SignalType" SG_ 2158960640 ODIIC_ODIInd37 "BLN";
BA_ "PacketOrder" SG_ 2158960640 ODIIC_ODIInd37 38;
BA_ "SignalLongName" SG_ 2158960640 ODIIC_ODIInd37 "Open Display Interface Indication Centerstack : Open Display Interface Indication 37";
BA_ "VNSigAllNodes" SG_ 2158960640 ODIIC_ODIInd37 1;
BA_ "GenSigSendType" SG_ 2158960640 ODIIC_ODIInd36 10;
BA_ "GenSigSendOnInit" SG_ 2158960640 ODIIC_ODIInd36 1;
BA_ "VNSigInfotainment" SG_ 2158960640 ODIIC_ODIInd36 1;
BA_ "SignalType" SG_ 2158960640 ODIIC_ODIInd36 "BLN";
BA_ "PacketOrder" SG_ 2158960640 ODIIC_ODIInd36 37;
BA_ "SignalLongName" SG_ 2158960640 ODIIC_ODIInd36 "Open Display Interface Indication Centerstack : Open Display Interface Indication 36";
BA_ "VNSigAllNodes" SG_ 2158960640 ODIIC_ODIInd36 1;
BA_ "GenSigSendType" SG_ 2158960640 ODIIC_ODIInd35 10;
BA_ "GenSigSendOnInit" SG_ 2158960640 ODIIC_ODIInd35 1;
BA_ "VNSigInfotainment" SG_ 2158960640 ODIIC_ODIInd35 1;
BA_ "SignalType" SG_ 2158960640 ODIIC_ODIInd35 "BLN";
BA_ "PacketOrder" SG_ 2158960640 ODIIC_ODIInd35 36;
BA_ "SignalLongName" SG_ 2158960640 ODIIC_ODIInd35 "Open Display Interface Indication Centerstack : Open Display Interface Indication 35";
BA_ "VNSigAllNodes" SG_ 2158960640 ODIIC_ODIInd35 1;
BA_ "GenSigSendType" SG_ 2158960640 ODIIC_ODIInd34 10;
BA_ "GenSigSendOnInit" SG_ 2158960640 ODIIC_ODIInd34 1;
BA_ "VNSigInfotainment" SG_ 2158960640 ODIIC_ODIInd34 1;
BA_ "SignalType" SG_ 2158960640 ODIIC_ODIInd34 "BLN";
BA_ "PacketOrder" SG_ 2158960640 ODIIC_ODIInd34 35;
BA_ "SignalLongName" SG_ 2158960640 ODIIC_ODIInd34 "Open Display Interface Indication Centerstack : Open Display Interface Indication 34";
BA_ "VNSigAllNodes" SG_ 2158960640 ODIIC_ODIInd34 1;
BA_ "GenSigSendType" SG_ 2158960640 ODIIC_ODIInd33 10;
BA_ "GenSigSendOnInit" SG_ 2158960640 ODIIC_ODIInd33 1;
BA_ "VNSigInfotainment" SG_ 2158960640 ODIIC_ODIInd33 1;
BA_ "SignalType" SG_ 2158960640 ODIIC_ODIInd33 "BLN";
BA_ "PacketOrder" SG_ 2158960640 ODIIC_ODIInd33 34;
BA_ "SignalLongName" SG_ 2158960640 ODIIC_ODIInd33 "Open Display Interface Indication Centerstack : Open Display Interface Indication 33";
BA_ "VNSigAllNodes" SG_ 2158960640 ODIIC_ODIInd33 1;
BA_ "GenSigSendType" SG_ 2158960640 ODIIC_ODIInd32 10;
BA_ "GenSigSendOnInit" SG_ 2158960640 ODIIC_ODIInd32 1;
BA_ "VNSigInfotainment" SG_ 2158960640 ODIIC_ODIInd32 1;
BA_ "SignalType" SG_ 2158960640 ODIIC_ODIInd32 "BLN";
BA_ "PacketOrder" SG_ 2158960640 ODIIC_ODIInd32 33;
BA_ "SignalLongName" SG_ 2158960640 ODIIC_ODIInd32 "Open Display Interface Indication Centerstack : Open Display Interface Indication 32";
BA_ "VNSigAllNodes" SG_ 2158960640 ODIIC_ODIInd32 1;
BA_ "GenSigSendType" SG_ 2158960640 ODIIC_ODIInd31 10;
BA_ "GenSigSendOnInit" SG_ 2158960640 ODIIC_ODIInd31 1;
BA_ "VNSigInfotainment" SG_ 2158960640 ODIIC_ODIInd31 1;
BA_ "SignalType" SG_ 2158960640 ODIIC_ODIInd31 "BLN";
BA_ "PacketOrder" SG_ 2158960640 ODIIC_ODIInd31 32;
BA_ "SignalLongName" SG_ 2158960640 ODIIC_ODIInd31 "Open Display Interface Indication Centerstack : Open Display Interface Indication 31";
BA_ "VNSigAllNodes" SG_ 2158960640 ODIIC_ODIInd31 1;
BA_ "GenSigSendType" SG_ 2158960640 ODIIC_ODIInd30 10;
BA_ "GenSigSendOnInit" SG_ 2158960640 ODIIC_ODIInd30 1;
BA_ "VNSigInfotainment" SG_ 2158960640 ODIIC_ODIInd30 1;
BA_ "SignalType" SG_ 2158960640 ODIIC_ODIInd30 "BLN";
BA_ "PacketOrder" SG_ 2158960640 ODIIC_ODIInd30 31;
BA_ "SignalLongName" SG_ 2158960640 ODIIC_ODIInd30 "Open Display Interface Indication Centerstack : Open Display Interface Indication 30";
BA_ "VNSigAllNodes" SG_ 2158960640 ODIIC_ODIInd30 1;
BA_ "GenSigSendType" SG_ 2158960640 ODIIC_ODIInd3 10;
BA_ "GenSigSendOnInit" SG_ 2158960640 ODIIC_ODIInd3 1;
BA_ "VNSigInfotainment" SG_ 2158960640 ODIIC_ODIInd3 1;
BA_ "SignalType" SG_ 2158960640 ODIIC_ODIInd3 "BLN";
BA_ "PacketOrder" SG_ 2158960640 ODIIC_ODIInd3 4;
BA_ "SignalLongName" SG_ 2158960640 ODIIC_ODIInd3 "Open Display Interface Indication Centerstack : Open Display Interface Indication 3";
BA_ "VNSigAllNodes" SG_ 2158960640 ODIIC_ODIInd3 1;
BA_ "GenSigSendType" SG_ 2158960640 ODIIC_ODIInd29 10;
BA_ "GenSigSendOnInit" SG_ 2158960640 ODIIC_ODIInd29 1;
BA_ "VNSigInfotainment" SG_ 2158960640 ODIIC_ODIInd29 1;
BA_ "SignalType" SG_ 2158960640 ODIIC_ODIInd29 "BLN";
BA_ "PacketOrder" SG_ 2158960640 ODIIC_ODIInd29 30;
BA_ "SignalLongName" SG_ 2158960640 ODIIC_ODIInd29 "Open Display Interface Indication Centerstack : Open Display Interface Indication 29";
BA_ "VNSigAllNodes" SG_ 2158960640 ODIIC_ODIInd29 1;
BA_ "GenSigSendType" SG_ 2158960640 ODIIC_ODIInd28 10;
BA_ "GenSigSendOnInit" SG_ 2158960640 ODIIC_ODIInd28 1;
BA_ "VNSigInfotainment" SG_ 2158960640 ODIIC_ODIInd28 1;
BA_ "SignalType" SG_ 2158960640 ODIIC_ODIInd28 "BLN";
BA_ "PacketOrder" SG_ 2158960640 ODIIC_ODIInd28 29;
BA_ "SignalLongName" SG_ 2158960640 ODIIC_ODIInd28 "Open Display Interface Indication Centerstack : Open Display Interface Indication 28";
BA_ "VNSigAllNodes" SG_ 2158960640 ODIIC_ODIInd28 1;
BA_ "GenSigSendType" SG_ 2158960640 ODIIC_ODIInd27 10;
BA_ "GenSigSendOnInit" SG_ 2158960640 ODIIC_ODIInd27 1;
BA_ "VNSigInfotainment" SG_ 2158960640 ODIIC_ODIInd27 1;
BA_ "SignalType" SG_ 2158960640 ODIIC_ODIInd27 "BLN";
BA_ "PacketOrder" SG_ 2158960640 ODIIC_ODIInd27 28;
BA_ "SignalLongName" SG_ 2158960640 ODIIC_ODIInd27 "Open Display Interface Indication Centerstack : Open Display Interface Indication 27";
BA_ "VNSigAllNodes" SG_ 2158960640 ODIIC_ODIInd27 1;
BA_ "GenSigSendType" SG_ 2158960640 ODIIC_ODIInd26 10;
BA_ "GenSigSendOnInit" SG_ 2158960640 ODIIC_ODIInd26 1;
BA_ "VNSigInfotainment" SG_ 2158960640 ODIIC_ODIInd26 1;
BA_ "SignalType" SG_ 2158960640 ODIIC_ODIInd26 "BLN";
BA_ "PacketOrder" SG_ 2158960640 ODIIC_ODIInd26 27;
BA_ "SignalLongName" SG_ 2158960640 ODIIC_ODIInd26 "Open Display Interface Indication Centerstack : Open Display Interface Indication 26";
BA_ "VNSigAllNodes" SG_ 2158960640 ODIIC_ODIInd26 1;
BA_ "GenSigSendType" SG_ 2158960640 ODIIC_ODIInd25 10;
BA_ "GenSigSendOnInit" SG_ 2158960640 ODIIC_ODIInd25 1;
BA_ "VNSigInfotainment" SG_ 2158960640 ODIIC_ODIInd25 1;
BA_ "SignalType" SG_ 2158960640 ODIIC_ODIInd25 "BLN";
BA_ "PacketOrder" SG_ 2158960640 ODIIC_ODIInd25 26;
BA_ "SignalLongName" SG_ 2158960640 ODIIC_ODIInd25 "Open Display Interface Indication Centerstack : Open Display Interface Indication 25";
BA_ "VNSigAllNodes" SG_ 2158960640 ODIIC_ODIInd25 1;
BA_ "GenSigSendType" SG_ 2158960640 ODIIC_ODIInd24 10;
BA_ "GenSigSendOnInit" SG_ 2158960640 ODIIC_ODIInd24 1;
BA_ "VNSigInfotainment" SG_ 2158960640 ODIIC_ODIInd24 1;
BA_ "SignalType" SG_ 2158960640 ODIIC_ODIInd24 "BLN";
BA_ "PacketOrder" SG_ 2158960640 ODIIC_ODIInd24 25;
BA_ "SignalLongName" SG_ 2158960640 ODIIC_ODIInd24 "Open Display Interface Indication Centerstack : Open Display Interface Indication 24";
BA_ "VNSigAllNodes" SG_ 2158960640 ODIIC_ODIInd24 1;
BA_ "GenSigSendType" SG_ 2158960640 ODIIC_ODIInd23 10;
BA_ "GenSigSendOnInit" SG_ 2158960640 ODIIC_ODIInd23 1;
BA_ "VNSigInfotainment" SG_ 2158960640 ODIIC_ODIInd23 1;
BA_ "SignalType" SG_ 2158960640 ODIIC_ODIInd23 "BLN";
BA_ "PacketOrder" SG_ 2158960640 ODIIC_ODIInd23 24;
BA_ "SignalLongName" SG_ 2158960640 ODIIC_ODIInd23 "Open Display Interface Indication Centerstack : Open Display Interface Indication 23";
BA_ "VNSigAllNodes" SG_ 2158960640 ODIIC_ODIInd23 1;
BA_ "GenSigSendType" SG_ 2158960640 ODIIC_ODIInd22 10;
BA_ "GenSigSendOnInit" SG_ 2158960640 ODIIC_ODIInd22 1;
BA_ "VNSigInfotainment" SG_ 2158960640 ODIIC_ODIInd22 1;
BA_ "SignalType" SG_ 2158960640 ODIIC_ODIInd22 "BLN";
BA_ "PacketOrder" SG_ 2158960640 ODIIC_ODIInd22 23;
BA_ "SignalLongName" SG_ 2158960640 ODIIC_ODIInd22 "Open Display Interface Indication Centerstack : Open Display Interface Indication 22";
BA_ "VNSigAllNodes" SG_ 2158960640 ODIIC_ODIInd22 1;
BA_ "GenSigSendType" SG_ 2158960640 ODIIC_ODIInd21 10;
BA_ "GenSigSendOnInit" SG_ 2158960640 ODIIC_ODIInd21 1;
BA_ "VNSigInfotainment" SG_ 2158960640 ODIIC_ODIInd21 1;
BA_ "SignalType" SG_ 2158960640 ODIIC_ODIInd21 "BLN";
BA_ "PacketOrder" SG_ 2158960640 ODIIC_ODIInd21 22;
BA_ "SignalLongName" SG_ 2158960640 ODIIC_ODIInd21 "Open Display Interface Indication Centerstack : Open Display Interface Indication 21";
BA_ "VNSigAllNodes" SG_ 2158960640 ODIIC_ODIInd21 1;
BA_ "GenSigSendType" SG_ 2158960640 ODIIC_ODIInd20 10;
BA_ "GenSigSendOnInit" SG_ 2158960640 ODIIC_ODIInd20 1;
BA_ "VNSigInfotainment" SG_ 2158960640 ODIIC_ODIInd20 1;
BA_ "SignalType" SG_ 2158960640 ODIIC_ODIInd20 "BLN";
BA_ "PacketOrder" SG_ 2158960640 ODIIC_ODIInd20 21;
BA_ "SignalLongName" SG_ 2158960640 ODIIC_ODIInd20 "Open Display Interface Indication Centerstack : Open Display Interface Indication 20";
BA_ "VNSigAllNodes" SG_ 2158960640 ODIIC_ODIInd20 1;
BA_ "GenSigSendType" SG_ 2158960640 ODIIC_ODIInd2 10;
BA_ "GenSigSendOnInit" SG_ 2158960640 ODIIC_ODIInd2 1;
BA_ "VNSigInfotainment" SG_ 2158960640 ODIIC_ODIInd2 1;
BA_ "SignalType" SG_ 2158960640 ODIIC_ODIInd2 "BLN";
BA_ "PacketOrder" SG_ 2158960640 ODIIC_ODIInd2 3;
BA_ "SignalLongName" SG_ 2158960640 ODIIC_ODIInd2 "Open Display Interface Indication Centerstack : Open Display Interface Indication 2";
BA_ "VNSigAllNodes" SG_ 2158960640 ODIIC_ODIInd2 1;
BA_ "GenSigSendType" SG_ 2158960640 ODIIC_ODIInd19 10;
BA_ "GenSigSendOnInit" SG_ 2158960640 ODIIC_ODIInd19 1;
BA_ "VNSigInfotainment" SG_ 2158960640 ODIIC_ODIInd19 1;
BA_ "SignalType" SG_ 2158960640 ODIIC_ODIInd19 "BLN";
BA_ "PacketOrder" SG_ 2158960640 ODIIC_ODIInd19 20;
BA_ "SignalLongName" SG_ 2158960640 ODIIC_ODIInd19 "Open Display Interface Indication Centerstack : Open Display Interface Indication 19";
BA_ "VNSigAllNodes" SG_ 2158960640 ODIIC_ODIInd19 1;
BA_ "GenSigSendType" SG_ 2158960640 ODIIC_ODIInd18 10;
BA_ "GenSigSendOnInit" SG_ 2158960640 ODIIC_ODIInd18 1;
BA_ "VNSigInfotainment" SG_ 2158960640 ODIIC_ODIInd18 1;
BA_ "SignalType" SG_ 2158960640 ODIIC_ODIInd18 "BLN";
BA_ "PacketOrder" SG_ 2158960640 ODIIC_ODIInd18 19;
BA_ "SignalLongName" SG_ 2158960640 ODIIC_ODIInd18 "Open Display Interface Indication Centerstack : Open Display Interface Indication 18";
BA_ "VNSigAllNodes" SG_ 2158960640 ODIIC_ODIInd18 1;
BA_ "GenSigSendType" SG_ 2158960640 ODIIC_ODIInd17 10;
BA_ "GenSigSendOnInit" SG_ 2158960640 ODIIC_ODIInd17 1;
BA_ "VNSigInfotainment" SG_ 2158960640 ODIIC_ODIInd17 1;
BA_ "SignalType" SG_ 2158960640 ODIIC_ODIInd17 "BLN";
BA_ "PacketOrder" SG_ 2158960640 ODIIC_ODIInd17 18;
BA_ "SignalLongName" SG_ 2158960640 ODIIC_ODIInd17 "Open Display Interface Indication Centerstack : Open Display Interface Indication 17";
BA_ "VNSigAllNodes" SG_ 2158960640 ODIIC_ODIInd17 1;
BA_ "GenSigSendType" SG_ 2158960640 ODIIC_ODIInd16 10;
BA_ "GenSigSendOnInit" SG_ 2158960640 ODIIC_ODIInd16 1;
BA_ "VNSigInfotainment" SG_ 2158960640 ODIIC_ODIInd16 1;
BA_ "SignalType" SG_ 2158960640 ODIIC_ODIInd16 "BLN";
BA_ "PacketOrder" SG_ 2158960640 ODIIC_ODIInd16 17;
BA_ "SignalLongName" SG_ 2158960640 ODIIC_ODIInd16 "Open Display Interface Indication Centerstack : Open Display Interface Indication 16";
BA_ "VNSigAllNodes" SG_ 2158960640 ODIIC_ODIInd16 1;
BA_ "GenSigSendType" SG_ 2158960640 ODIIC_ODIInd15 10;
BA_ "GenSigSendOnInit" SG_ 2158960640 ODIIC_ODIInd15 1;
BA_ "VNSigInfotainment" SG_ 2158960640 ODIIC_ODIInd15 1;
BA_ "SignalType" SG_ 2158960640 ODIIC_ODIInd15 "BLN";
BA_ "PacketOrder" SG_ 2158960640 ODIIC_ODIInd15 16;
BA_ "SignalLongName" SG_ 2158960640 ODIIC_ODIInd15 "Open Display Interface Indication Centerstack : Open Display Interface Indication 15";
BA_ "VNSigAllNodes" SG_ 2158960640 ODIIC_ODIInd15 1;
BA_ "GenSigSendType" SG_ 2158960640 ODIIC_ODIInd14 10;
BA_ "GenSigSendOnInit" SG_ 2158960640 ODIIC_ODIInd14 1;
BA_ "VNSigInfotainment" SG_ 2158960640 ODIIC_ODIInd14 1;
BA_ "SignalType" SG_ 2158960640 ODIIC_ODIInd14 "BLN";
BA_ "PacketOrder" SG_ 2158960640 ODIIC_ODIInd14 15;
BA_ "SignalLongName" SG_ 2158960640 ODIIC_ODIInd14 "Open Display Interface Indication Centerstack : Open Display Interface Indication 14";
BA_ "VNSigAllNodes" SG_ 2158960640 ODIIC_ODIInd14 1;
BA_ "GenSigSendType" SG_ 2158960640 ODIIC_ODIInd13 10;
BA_ "GenSigSendOnInit" SG_ 2158960640 ODIIC_ODIInd13 1;
BA_ "VNSigInfotainment" SG_ 2158960640 ODIIC_ODIInd13 1;
BA_ "SignalType" SG_ 2158960640 ODIIC_ODIInd13 "BLN";
BA_ "PacketOrder" SG_ 2158960640 ODIIC_ODIInd13 14;
BA_ "SignalLongName" SG_ 2158960640 ODIIC_ODIInd13 "Open Display Interface Indication Centerstack : Open Display Interface Indication 13";
BA_ "VNSigAllNodes" SG_ 2158960640 ODIIC_ODIInd13 1;
BA_ "GenSigSendType" SG_ 2158960640 ODIIC_ODIInd12 10;
BA_ "GenSigSendOnInit" SG_ 2158960640 ODIIC_ODIInd12 1;
BA_ "VNSigInfotainment" SG_ 2158960640 ODIIC_ODIInd12 1;
BA_ "SignalType" SG_ 2158960640 ODIIC_ODIInd12 "BLN";
BA_ "PacketOrder" SG_ 2158960640 ODIIC_ODIInd12 13;
BA_ "SignalLongName" SG_ 2158960640 ODIIC_ODIInd12 "Open Display Interface Indication Centerstack : Open Display Interface Indication 12";
BA_ "VNSigAllNodes" SG_ 2158960640 ODIIC_ODIInd12 1;
BA_ "GenSigSendType" SG_ 2158960640 ODIIC_ODIInd11 10;
BA_ "GenSigSendOnInit" SG_ 2158960640 ODIIC_ODIInd11 1;
BA_ "VNSigInfotainment" SG_ 2158960640 ODIIC_ODIInd11 1;
BA_ "SignalType" SG_ 2158960640 ODIIC_ODIInd11 "BLN";
BA_ "PacketOrder" SG_ 2158960640 ODIIC_ODIInd11 12;
BA_ "SignalLongName" SG_ 2158960640 ODIIC_ODIInd11 "Open Display Interface Indication Centerstack : Open Display Interface Indication 11";
BA_ "VNSigAllNodes" SG_ 2158960640 ODIIC_ODIInd11 1;
BA_ "GenSigSendType" SG_ 2158960640 ODIIC_ODIInd10 10;
BA_ "GenSigSendOnInit" SG_ 2158960640 ODIIC_ODIInd10 1;
BA_ "VNSigInfotainment" SG_ 2158960640 ODIIC_ODIInd10 1;
BA_ "SignalType" SG_ 2158960640 ODIIC_ODIInd10 "BLN";
BA_ "PacketOrder" SG_ 2158960640 ODIIC_ODIInd10 11;
BA_ "SignalLongName" SG_ 2158960640 ODIIC_ODIInd10 "Open Display Interface Indication Centerstack : Open Display Interface Indication 10";
BA_ "VNSigAllNodes" SG_ 2158960640 ODIIC_ODIInd10 1;
BA_ "GenSigSendType" SG_ 2158960640 ODIIC_ODIInd1 10;
BA_ "GenSigSendOnInit" SG_ 2158960640 ODIIC_ODIInd1 1;
BA_ "VNSigInfotainment" SG_ 2158960640 ODIIC_ODIInd1 1;
BA_ "SignalType" SG_ 2158960640 ODIIC_ODIInd1 "BLN";
BA_ "PacketOrder" SG_ 2158960640 ODIIC_ODIInd1 2;
BA_ "SignalLongName" SG_ 2158960640 ODIIC_ODIInd1 "Open Display Interface Indication Centerstack : Open Display Interface Indication 1";
BA_ "VNSigAllNodes" SG_ 2158960640 ODIIC_ODIInd1 1;
BA_ "GenSigDeltaValue" SG_ 2158977024 ODIEC_MultiFrRetCh 1;
BA_ "GenSigSendType" SG_ 2158977024 ODIEC_MultiFrRetCh 12;
BA_ "VNSigInfotainment" SG_ 2158977024 ODIEC_MultiFrRetCh 1;
BA_ "SignalType" SG_ 2158977024 ODIEC_MultiFrRetCh "UNM";
BA_ "PacketOrder" SG_ 2158977024 ODIEC_MultiFrRetCh 3;
BA_ "SignalLongName" SG_ 2158977024 ODIEC_MultiFrRetCh "Open Display Interface Event Packet Centerstack : MultiFrameReturnChannel";
BA_ "VNSigAllNodes" SG_ 2158977024 ODIEC_MultiFrRetCh 1;
BA_ "GenSigDeltaValue" SG_ 2158977024 ODIEC_FUCID 1;
BA_ "GenSigSendType" SG_ 2158977024 ODIEC_FUCID 12;
BA_ "VNSigInfotainment" SG_ 2158977024 ODIEC_FUCID 1;
BA_ "SignalType" SG_ 2158977024 ODIEC_FUCID "UNM";
BA_ "PacketOrder" SG_ 2158977024 ODIEC_FUCID 2;
BA_ "SignalLongName" SG_ 2158977024 ODIEC_FUCID "Open Display Interface Event Packet Centerstack : Functional Unit Class ID";
BA_ "VNSigAllNodes" SG_ 2158977024 ODIEC_FUCID 1;
BA_ "GenSigDeltaValue" SG_ 2158977024 ODIEC_EvID 1;
BA_ "GenSigSendType" SG_ 2158977024 ODIEC_EvID 12;
BA_ "VNSigInfotainment" SG_ 2158977024 ODIEC_EvID 1;
BA_ "SignalType" SG_ 2158977024 ODIEC_EvID "UNM";
BA_ "PacketOrder" SG_ 2158977024 ODIEC_EvID 1;
BA_ "SignalLongName" SG_ 2158977024 ODIEC_EvID "Open Display Interface Event Packet Centerstack : Event ID";
BA_ "VNSigAllNodes" SG_ 2158977024 ODIEC_EvID 1;
BA_ "GenSigSendType" SG_ 2158952448 ODDMR_ReqType 10;
BA_ "VNSigInfotainment" SG_ 2158952448 ODDMR_ReqType 1;
BA_ "SignalType" SG_ 2158952448 ODDMR_ReqType "ENM";
BA_ "PacketOrder" SG_ 2158952448 ODDMR_ReqType 1;
BA_ "SignalLongName" SG_ 2158952448 ODDMR_ReqType "Open Display Interface Dynamic Data Multi Request Rear Seat Display : Request Type";
BA_ "VNSigAllNodes" SG_ 2158952448 ODDMR_ReqType 1;
BA_ "GenSigDeltaValue" SG_ 2158952448 ODDMR_FUCID 1;
BA_ "GenSigSendType" SG_ 2158952448 ODDMR_FUCID 12;
BA_ "VNSigInfotainment" SG_ 2158952448 ODDMR_FUCID 1;
BA_ "SignalType" SG_ 2158952448 ODDMR_FUCID "UNM";
BA_ "PacketOrder" SG_ 2158952448 ODDMR_FUCID 6;
BA_ "SignalLongName" SG_ 2158952448 ODDMR_FUCID "Open Display Interface Dynamic Data Multi Request Rear Seat Display : Functional Unit Class ID";
BA_ "VNSigAllNodes" SG_ 2158952448 ODDMR_FUCID 1;
BA_ "GenSigSendType" SG_ 2158952448 ODDMR_DispMID 10;
BA_ "VNSigInfotainment" SG_ 2158952448 ODDMR_DispMID 1;
BA_ "SignalType" SG_ 2158952448 ODDMR_DispMID "ENM";
BA_ "PacketOrder" SG_ 2158952448 ODDMR_DispMID 7;
BA_ "SignalLongName" SG_ 2158952448 ODDMR_DispMID "Open Display Interface Dynamic Data Multi Request Rear Seat Display : Display Mask Id";
BA_ "VNSigAllNodes" SG_ 2158952448 ODDMR_DispMID 1;
BA_ "GenSigSendType" SG_ 2158952448 ODDMR_DataID2Vld 10;
BA_ "VNSigInfotainment" SG_ 2158952448 ODDMR_DataID2Vld 1;
BA_ "SignalType" SG_ 2158952448 ODDMR_DataID2Vld "BLN";
BA_ "PacketOrder" SG_ 2158952448 ODDMR_DataID2Vld 5;
BA_ "SignalLongName" SG_ 2158952448 ODDMR_DataID2Vld "Open Display Interface Dynamic Data Multi Request Rear Seat Display : Data ID Two Valid";
BA_ "VNSigAllNodes" SG_ 2158952448 ODDMR_DataID2Vld 1;
BA_ "GenSigDeltaValue" SG_ 2158952448 ODDMR_DataID2 1;
BA_ "GenSigSendType" SG_ 2158952448 ODDMR_DataID2 12;
BA_ "VNSigInfotainment" SG_ 2158952448 ODDMR_DataID2 1;
BA_ "SignalType" SG_ 2158952448 ODDMR_DataID2 "UNM";
BA_ "PacketOrder" SG_ 2158952448 ODDMR_DataID2 9;
BA_ "SignalLongName" SG_ 2158952448 ODDMR_DataID2 "Open Display Interface Dynamic Data Multi Request Rear Seat Display : Data ID Two";
BA_ "VNSigAllNodes" SG_ 2158952448 ODDMR_DataID2 1;
BA_ "GenSigSendType" SG_ 2158952448 ODDMR_DataID3Vld 10;
BA_ "VNSigInfotainment" SG_ 2158952448 ODDMR_DataID3Vld 1;
BA_ "SignalType" SG_ 2158952448 ODDMR_DataID3Vld "BLN";
BA_ "PacketOrder" SG_ 2158952448 ODDMR_DataID3Vld 4;
BA_ "SignalLongName" SG_ 2158952448 ODDMR_DataID3Vld "Open Display Interface Dynamic Data Multi Request Rear Seat Display : Data ID Three Valid";
BA_ "VNSigAllNodes" SG_ 2158952448 ODDMR_DataID3Vld 1;
BA_ "GenSigDeltaValue" SG_ 2158952448 ODDMR_DataID3 1;
BA_ "GenSigSendType" SG_ 2158952448 ODDMR_DataID3 12;
BA_ "VNSigInfotainment" SG_ 2158952448 ODDMR_DataID3 1;
BA_ "SignalType" SG_ 2158952448 ODDMR_DataID3 "UNM";
BA_ "PacketOrder" SG_ 2158952448 ODDMR_DataID3 10;
BA_ "SignalLongName" SG_ 2158952448 ODDMR_DataID3 "Open Display Interface Dynamic Data Multi Request Rear Seat Display : Data ID Three";
BA_ "VNSigAllNodes" SG_ 2158952448 ODDMR_DataID3 1;
BA_ "GenSigDeltaValue" SG_ 2158952448 ODDMR_DataID1 1;
BA_ "GenSigSendType" SG_ 2158952448 ODDMR_DataID1 12;
BA_ "VNSigInfotainment" SG_ 2158952448 ODDMR_DataID1 1;
BA_ "SignalType" SG_ 2158952448 ODDMR_DataID1 "UNM";
BA_ "PacketOrder" SG_ 2158952448 ODDMR_DataID1 8;
BA_ "SignalLongName" SG_ 2158952448 ODDMR_DataID1 "Open Display Interface Dynamic Data Multi Request Rear Seat Display : Data ID One";
BA_ "VNSigAllNodes" SG_ 2158952448 ODDMR_DataID1 1;
BA_ "GenSigSendType" SG_ 2158952448 ODDMR_DataID4Vld 10;
BA_ "VNSigInfotainment" SG_ 2158952448 ODDMR_DataID4Vld 1;
BA_ "SignalType" SG_ 2158952448 ODDMR_DataID4Vld "BLN";
BA_ "PacketOrder" SG_ 2158952448 ODDMR_DataID4Vld 3;
BA_ "SignalLongName" SG_ 2158952448 ODDMR_DataID4Vld "Open Display Interface Dynamic Data Multi Request Rear Seat Display : Data ID Four Valid";
BA_ "VNSigAllNodes" SG_ 2158952448 ODDMR_DataID4Vld 1;
BA_ "GenSigDeltaValue" SG_ 2158952448 ODDMR_DataID4 1;
BA_ "GenSigSendType" SG_ 2158952448 ODDMR_DataID4 12;
BA_ "VNSigInfotainment" SG_ 2158952448 ODDMR_DataID4 1;
BA_ "SignalType" SG_ 2158952448 ODDMR_DataID4 "UNM";
BA_ "PacketOrder" SG_ 2158952448 ODDMR_DataID4 11;
BA_ "SignalLongName" SG_ 2158952448 ODDMR_DataID4 "Open Display Interface Dynamic Data Multi Request Rear Seat Display : Data ID Four";
BA_ "VNSigAllNodes" SG_ 2158952448 ODDMR_DataID4 1;
BA_ "GenSigSendType" SG_ 2158952448 ODDMR_DataID5Vld 10;
BA_ "VNSigInfotainment" SG_ 2158952448 ODDMR_DataID5Vld 1;
BA_ "SignalType" SG_ 2158952448 ODDMR_DataID5Vld "BLN";
BA_ "PacketOrder" SG_ 2158952448 ODDMR_DataID5Vld 2;
BA_ "SignalLongName" SG_ 2158952448 ODDMR_DataID5Vld "Open Display Interface Dynamic Data Multi Request Rear Seat Display : Data ID Five Valid";
BA_ "VNSigAllNodes" SG_ 2158952448 ODDMR_DataID5Vld 1;
BA_ "GenSigDeltaValue" SG_ 2158952448 ODDMR_DataID5 1;
BA_ "GenSigSendType" SG_ 2158952448 ODDMR_DataID5 12;
BA_ "VNSigInfotainment" SG_ 2158952448 ODDMR_DataID5 1;
BA_ "SignalType" SG_ 2158952448 ODDMR_DataID5 "UNM";
BA_ "PacketOrder" SG_ 2158952448 ODDMR_DataID5 12;
BA_ "SignalLongName" SG_ 2158952448 ODDMR_DataID5 "Open Display Interface Dynamic Data Multi Request Rear Seat Display : Data ID Five";
BA_ "VNSigAllNodes" SG_ 2158952448 ODDMR_DataID5 1;
BA_ "GenSigDeltaValue" SG_ 2158944256 ODDLR_SubIdReqM 1;
BA_ "GenSigSendType" SG_ 2158944256 ODDLR_SubIdReqM 12;
BA_ "VNSigInfotainment" SG_ 2158944256 ODDLR_SubIdReqM 1;
BA_ "SignalType" SG_ 2158944256 ODDLR_SubIdReqM "UNM";
BA_ "PacketOrder" SG_ 2158944256 ODDLR_SubIdReqM 10;
BA_ "SignalLongName" SG_ 2158944256 ODDLR_SubIdReqM "Open Display Interface Dynamic Data List Request Rear Seat Display : Sub Id Request Mask";
BA_ "VNSigAllNodes" SG_ 2158944256 ODDLR_SubIdReqM 1;
BA_ "GenSigSendType" SG_ 2158944256 ODDLR_WrpArnd 10;
BA_ "VNSigInfotainment" SG_ 2158944256 ODDLR_WrpArnd 1;
BA_ "SignalType" SG_ 2158944256 ODDLR_WrpArnd "BLN";
BA_ "PacketOrder" SG_ 2158944256 ODDLR_WrpArnd 9;
BA_ "SignalLongName" SG_ 2158944256 ODDLR_WrpArnd "Open Display Interface Dynamic Data List Request Rear Seat Display : Wrap Around";
BA_ "VNSigAllNodes" SG_ 2158944256 ODDLR_WrpArnd 1;
BA_ "GenSigSendType" SG_ 2158944256 ODDLR_ReqType 10;
BA_ "VNSigInfotainment" SG_ 2158944256 ODDLR_ReqType 1;
BA_ "SignalType" SG_ 2158944256 ODDLR_ReqType "ENM";
BA_ "PacketOrder" SG_ 2158944256 ODDLR_ReqType 7;
BA_ "SignalLongName" SG_ 2158944256 ODDLR_ReqType "Open Display Interface Dynamic Data List Request Rear Seat Display : Request Type";
BA_ "VNSigAllNodes" SG_ 2158944256 ODDLR_ReqType 1;
BA_ "GenSigSendType" SG_ 2158944256 ODDLR_ReqDir 10;
BA_ "VNSigInfotainment" SG_ 2158944256 ODDLR_ReqDir 1;
BA_ "SignalType" SG_ 2158944256 ODDLR_ReqDir "BLN";
BA_ "PacketOrder" SG_ 2158944256 ODDLR_ReqDir 5;
BA_ "SignalLongName" SG_ 2158944256 ODDLR_ReqDir "Open Display Interface Dynamic Data List Request Rear Seat Display : Req Direction";
BA_ "VNSigAllNodes" SG_ 2158944256 ODDLR_ReqDir 1;
BA_ "GenSigDeltaValue" SG_ 2158944256 ODDLR_NmEntries 1;
BA_ "GenSigSendType" SG_ 2158944256 ODDLR_NmEntries 12;
BA_ "VNSigInfotainment" SG_ 2158944256 ODDLR_NmEntries 1;
BA_ "SignalType" SG_ 2158944256 ODDLR_NmEntries "UNM";
BA_ "PacketOrder" SG_ 2158944256 ODDLR_NmEntries 4;
BA_ "SignalLongName" SG_ 2158944256 ODDLR_NmEntries "Open Display Interface Dynamic Data List Request Rear Seat Display : Num Entries";
BA_ "VNSigAllNodes" SG_ 2158944256 ODDLR_NmEntries 1;
BA_ "GenSigDeltaValue" SG_ 2158944256 ODDLR_Idx 1;
BA_ "GenSigSendType" SG_ 2158944256 ODDLR_Idx 12;
BA_ "VNSigInfotainment" SG_ 2158944256 ODDLR_Idx 1;
BA_ "SignalType" SG_ 2158944256 ODDLR_Idx "UNM";
BA_ "PacketOrder" SG_ 2158944256 ODDLR_Idx 6;
BA_ "SignalLongName" SG_ 2158944256 ODDLR_Idx "Open Display Interface Dynamic Data List Request Rear Seat Display : Index";
BA_ "VNSigAllNodes" SG_ 2158944256 ODDLR_Idx 1;
BA_ "GenSigDeltaValue" SG_ 2158944256 ODDLR_FUCID 1;
BA_ "GenSigSendType" SG_ 2158944256 ODDLR_FUCID 12;
BA_ "VNSigInfotainment" SG_ 2158944256 ODDLR_FUCID 1;
BA_ "SignalType" SG_ 2158944256 ODDLR_FUCID "UNM";
BA_ "PacketOrder" SG_ 2158944256 ODDLR_FUCID 1;
BA_ "SignalLongName" SG_ 2158944256 ODDLR_FUCID "Open Display Interface Dynamic Data List Request Rear Seat Display : Functional Unit Class ID";
BA_ "VNSigAllNodes" SG_ 2158944256 ODDLR_FUCID 1;
BA_ "GenSigSendType" SG_ 2158944256 ODDLR_DspMID 10;
BA_ "VNSigInfotainment" SG_ 2158944256 ODDLR_DspMID 1;
BA_ "SignalType" SG_ 2158944256 ODDLR_DspMID "ENM";
BA_ "PacketOrder" SG_ 2158944256 ODDLR_DspMID 3;
BA_ "SignalLongName" SG_ 2158944256 ODDLR_DspMID "Open Display Interface Dynamic Data List Request Rear Seat Display : Display Mask Id";
BA_ "VNSigAllNodes" SG_ 2158944256 ODDLR_DspMID 1;
BA_ "GenSigDeltaValue" SG_ 2158944256 ODDLR_DataId 1;
BA_ "GenSigSendType" SG_ 2158944256 ODDLR_DataId 12;
BA_ "VNSigInfotainment" SG_ 2158944256 ODDLR_DataId 1;
BA_ "SignalType" SG_ 2158944256 ODDLR_DataId "UNM";
BA_ "PacketOrder" SG_ 2158944256 ODDLR_DataId 2;
BA_ "SignalLongName" SG_ 2158944256 ODDLR_DataId "Open Display Interface Dynamic Data List Request Rear Seat Display : Data Id";
BA_ "VNSigAllNodes" SG_ 2158944256 ODDLR_DataId 1;
BA_ "GenSigSendType" SG_ 2158944256 ODDLR_BckgndFlag 10;
BA_ "VNSigInfotainment" SG_ 2158944256 ODDLR_BckgndFlag 1;
BA_ "SignalType" SG_ 2158944256 ODDLR_BckgndFlag "ENM";
BA_ "PacketOrder" SG_ 2158944256 ODDLR_BckgndFlag 8;
BA_ "SignalLongName" SG_ 2158944256 ODDLR_BckgndFlag "Open Display Interface Dynamic Data List Request Rear Seat Display : Background Flag";
BA_ "VNSigAllNodes" SG_ 2158944256 ODDLR_BckgndFlag 1;
BA_ "GenSigSendType" SG_ 2158927872 ODDC_InvldData 10;
BA_ "VNSigInfotainment" SG_ 2158927872 ODDC_InvldData 1;
BA_ "SignalType" SG_ 2158927872 ODDC_InvldData "BLN";
BA_ "PacketOrder" SG_ 2158927872 ODDC_InvldData 2;
BA_ "SignalLongName" SG_ 2158927872 ODDC_InvldData "Open Display Interface Dynamic Data Centerstack : Invalid Data";
BA_ "VNSigAllNodes" SG_ 2158927872 ODDC_InvldData 1;
BA_ "GenSigDeltaValue" SG_ 2158927872 ODDC_FUCID 1;
BA_ "GenSigSendType" SG_ 2158927872 ODDC_FUCID 12;
BA_ "VNSigInfotainment" SG_ 2158927872 ODDC_FUCID 1;
BA_ "SignalType" SG_ 2158927872 ODDC_FUCID "UNM";
BA_ "PacketOrder" SG_ 2158927872 ODDC_FUCID 3;
BA_ "SignalLongName" SG_ 2158927872 ODDC_FUCID "Open Display Interface Dynamic Data Centerstack : Functional Unit Class ID";
BA_ "VNSigAllNodes" SG_ 2158927872 ODDC_FUCID 1;
BA_ "GenSigDeltaValue" SG_ 2158927872 ODDC_DataVal 1;
BA_ "GenSigSendType" SG_ 2158927872 ODDC_DataVal 12;
BA_ "VNSigInfotainment" SG_ 2158927872 ODDC_DataVal 1;
BA_ "SignalType" SG_ 2158927872 ODDC_DataVal "UNM";
BA_ "PacketOrder" SG_ 2158927872 ODDC_DataVal 5;
BA_ "SignalLongName" SG_ 2158927872 ODDC_DataVal "Open Display Interface Dynamic Data Centerstack : Data Value";
BA_ "VNSigAllNodes" SG_ 2158927872 ODDC_DataVal 1;
BA_ "GenSigDeltaValue" SG_ 2158927872 ODDC_DataType 1;
BA_ "GenSigSendType" SG_ 2158927872 ODDC_DataType 10;
BA_ "VNSigInfotainment" SG_ 2158927872 ODDC_DataType 1;
BA_ "SignalType" SG_ 2158927872 ODDC_DataType "ENM";
BA_ "PacketOrder" SG_ 2158927872 ODDC_DataType 1;
BA_ "SignalLongName" SG_ 2158927872 ODDC_DataType "Open Display Interface Dynamic Data Centerstack : Data Type";
BA_ "VNSigAllNodes" SG_ 2158927872 ODDC_DataType 1;
BA_ "GenSigDeltaValue" SG_ 2158927872 ODDC_DataId 1;
BA_ "GenSigSendType" SG_ 2158927872 ODDC_DataId 12;
BA_ "VNSigInfotainment" SG_ 2158927872 ODDC_DataId 1;
BA_ "SignalType" SG_ 2158927872 ODDC_DataId "UNM";
BA_ "PacketOrder" SG_ 2158927872 ODDC_DataId 4;
BA_ "SignalLongName" SG_ 2158927872 ODDC_DataId "Open Display Interface Dynamic Data Centerstack : Data ID";
BA_ "VNSigAllNodes" SG_ 2158927872 ODDC_DataId 1;
BA_ "GenSigDeltaValue" SG_ 2158895104 ODI_CntrStck2RSD 1;
BA_ "GenSigSendType" SG_ 2158895104 ODI_CntrStck2RSD 12;
BA_ "VNSigInfotainment" SG_ 2158895104 ODI_CntrStck2RSD 1;
BA_ "SignalType" SG_ 2158895104 ODI_CntrStck2RSD "UNM";
BA_ "SignalLongName" SG_ 2158895104 ODI_CntrStck2RSD "Open Display Interface Centerstack 2 Rear Seat Display";
BA_ "VNSigAllNodes" SG_ 2158895104 ODI_CntrStck2RSD 1;
BA_ "GenSigDeltaValue" SG_ 2152038400 InfMdRspPld 1;
BA_ "GenSigSendType" SG_ 2152038400 InfMdRspPld 12;
BA_ "VNSigInfotainment" SG_ 2152038400 InfMdRspPld 1;
BA_ "SignalType" SG_ 2152038400 InfMdRspPld "UNM";
BA_ "SignalLongName" SG_ 2152038400 InfMdRspPld "Infomatics Metadata Response Payload";
BA_ "VNSigAllNodes" SG_ 2152038400 InfMdRspPld 1;
BA_ "GenSigSendType" SG_ 2152022016 ASVSC_ReqEnbld 10;
BA_ "PacketOrder" SG_ 2152022016 ASVSC_ReqEnbld 2;
BA_ "VNSigIntermediate" SG_ 2152022016 ASVSC_ReqEnbld 1;
BA_ "SignalType" SG_ 2152022016 ASVSC_ReqEnbld "BLN";
BA_ "SignalLongName" SG_ 2152022016 ASVSC_ReqEnbld "Audio System Volume Setting Control : Request Enabled";
BA_ "GenSigDeltaValue" SG_ 2152022016 ASVSC_VolReq 1;
BA_ "GenSigSendType" SG_ 2152022016 ASVSC_VolReq 12;
BA_ "PacketOrder" SG_ 2152022016 ASVSC_VolReq 1;
BA_ "VNSigIntermediate" SG_ 2152022016 ASVSC_VolReq 1;
BA_ "SignalType" SG_ 2152022016 ASVSC_VolReq "UNM";
BA_ "SignalLongName" SG_ 2152022016 ASVSC_VolReq "Audio System Volume Setting Control : Volume Request";
BA_ "GenSigSendType" SG_ 2152022016 AudSelctdSrcReq 10;
BA_ "VNSigIntermediate" SG_ 2152022016 AudSelctdSrcReq 1;
BA_ "SignalType" SG_ 2152022016 AudSelctdSrcReq "ENM";
BA_ "SignalLongName" SG_ 2152022016 AudSelctdSrcReq "Audio Selected Source Request";
BA_ "GenSigSendType" SG_ 2152022016 InfMdStRsp 10;
BA_ "VNSigInfotainment" SG_ 2152022016 InfMdStRsp 1;
BA_ "SignalType" SG_ 2152022016 InfMdStRsp "ENM";
BA_ "SignalLongName" SG_ 2152022016 InfMdStRsp "Infomatics Metadata Status Response";
BA_ "VNSigAllNodes" SG_ 2152022016 InfMdStRsp 1;
BA_ "GenSigDeltaValue" SG_ 2152022016 InfMdRspInf 1;
BA_ "GenSigSendType" SG_ 2152022016 InfMdRspInf 12;
BA_ "VNSigInfotainment" SG_ 2152022016 InfMdRspInf 1;
BA_ "SignalType" SG_ 2152022016 InfMdRspInf "UNM";
BA_ "SignalLongName" SG_ 2152022016 InfMdRspInf "Infomatics Metadata Response Initiate";
BA_ "VNSigAllNodes" SG_ 2152022016 InfMdRspInf 1;
BA_ "GenSigDeltaValue" SG_ 2152022016 InfMdRspCmplt 1;
BA_ "GenSigSendType" SG_ 2152022016 InfMdRspCmplt 12;
BA_ "VNSigInfotainment" SG_ 2152022016 InfMdRspCmplt 1;
BA_ "SignalType" SG_ 2152022016 InfMdRspCmplt "UNM";
BA_ "SignalLongName" SG_ 2152022016 InfMdRspCmplt "Infomatics Metadata Response Complete";
BA_ "VNSigAllNodes" SG_ 2152022016 InfMdRspCmplt 1;
BA_ "GenSigDeltaValue" SG_ 2152005632 InfMdRqstPld 1;
BA_ "GenSigSendType" SG_ 2152005632 InfMdRqstPld 12;
BA_ "VNSigInfotainment" SG_ 2152005632 InfMdRqstPld 1;
BA_ "SignalType" SG_ 2152005632 InfMdRqstPld "UNM";
BA_ "SignalLongName" SG_ 2152005632 InfMdRqstPld "Infomatics Metadata Request Payload";
BA_ "VNSigAllNodes" SG_ 2152005632 InfMdRqstPld 1;
BA_ "GenSigDeltaValue" SG_ 2151989248 InfMdRqstInt 1;
BA_ "GenSigSendType" SG_ 2151989248 InfMdRqstInt 12;
BA_ "VNSigInfotainment" SG_ 2151989248 InfMdRqstInt 1;
BA_ "SignalType" SG_ 2151989248 InfMdRqstInt "UNM";
BA_ "SignalLongName" SG_ 2151989248 InfMdRqstInt "Infomatics Metadata Request Initiate";
BA_ "VNSigAllNodes" SG_ 2151989248 InfMdRqstInt 1;
BA_ "GenSigDeltaValue" SG_ 2151989248 InfMdRqstCmplt 1;
BA_ "GenSigSendType" SG_ 2151989248 InfMdRqstCmplt 12;
BA_ "VNSigInfotainment" SG_ 2151989248 InfMdRqstCmplt 1;
BA_ "SignalType" SG_ 2151989248 InfMdRqstCmplt "UNM";
BA_ "SignalLongName" SG_ 2151989248 InfMdRqstCmplt "Infomatics Metadata Request Complete";
BA_ "VNSigAllNodes" SG_ 2151989248 InfMdRqstCmplt 1;
BA_ "GenSigSendType" SG_ 2151989248 InfMdStReq 10;
BA_ "VNSigInfotainment" SG_ 2151989248 InfMdStReq 1;
BA_ "SignalType" SG_ 2151989248 InfMdStReq "ENM";
BA_ "SignalLongName" SG_ 2151989248 InfMdStReq "Infomatics Metadata Status Request";
BA_ "VNSigAllNodes" SG_ 2151989248 InfMdStReq 1;
BA_ "GenSigSendType" SG_ 2151972864 LnchCtrlWhlSlpReq 10;
BA_ "SignalType" SG_ 2151972864 LnchCtrlWhlSlpReq "ENM";
BA_ "SignalLongName" SG_ 2151972864 LnchCtrlWhlSlpReq "Launch Control Wheel Slip Request";
BA_ "VNSigAllNodes" SG_ 2151972864 LnchCtrlWhlSlpReq 1;
BA_ "GenSigSendType" SG_ 2151972864 LnchCtrlMdReq 10;
BA_ "SignalType" SG_ 2151972864 LnchCtrlMdReq "ENM";
BA_ "SignalLongName" SG_ 2151972864 LnchCtrlMdReq "Launch Control Mode Request";
BA_ "VNSigAllNodes" SG_ 2151972864 LnchCtrlMdReq 1;
BA_ "GenSigSendType" SG_ 2151972864 LnchCtrlEngRPMReq 10;
BA_ "SignalType" SG_ 2151972864 LnchCtrlEngRPMReq "ENM";
BA_ "SignalLongName" SG_ 2151972864 LnchCtrlEngRPMReq "Launch Control Engine RPM Request";
BA_ "VNSigAllNodes" SG_ 2151972864 LnchCtrlEngRPMReq 1;
BA_ "GenSigSendType" SG_ 2151972864 VehFuelRngCalcV 10;
BA_ "GenSigSendOnInit" SG_ 2151972864 VehFuelRngCalcV 1;
BA_ "SignalType" SG_ 2151972864 VehFuelRngCalcV "ENM";
BA_ "SignalLongName" SG_ 2151972864 VehFuelRngCalcV "Vehicle Fuel Range Calculated Validity";
BA_ "VNSigAllNodes" SG_ 2151972864 VehFuelRngCalcV 1;
BA_ "GenSigDeltaValue" SG_ 2151972864 VehFuelRngCalc 1;
BA_ "GenSigSendType" SG_ 2151972864 VehFuelRngCalc 12;
BA_ "GenSigSendOnInit" SG_ 2151972864 VehFuelRngCalc 1;
BA_ "SignalType" SG_ 2151972864 VehFuelRngCalc "UNM";
BA_ "SignalLongName" SG_ 2151972864 VehFuelRngCalc "Vehicle Fuel Range Calculated";
BA_ "VNSigAllNodes" SG_ 2151972864 VehFuelRngCalc 1;
BA_ "GenSigSendType" SG_ 2151972864 FuelLvlLwIO 10;
BA_ "GenSigSendOnInit" SG_ 2151972864 FuelLvlLwIO 2;
BA_ "SignalType" SG_ 2151972864 FuelLvlLwIO "BLN";
BA_ "SignalLongName" SG_ 2151972864 FuelLvlLwIO "Fuel Level Low Indication On";
BA_ "VNSigAllNodes" SG_ 2151972864 FuelLvlLwIO 1;
BA_ "SignalType" SG_ 2154528768 WhlGrndVlctyRtNnDrvnV "ENM";
BA_ "SignalLongName" SG_ 2154528768 WhlGrndVlctyRtNnDrvnV "Wheel Ground Velocity Right Non Driven Validity";
BA_ "VNSigAllNodes" SG_ 2154528768 WhlGrndVlctyRtNnDrvnV 1;
BA_ "SignalType" SG_ 2154528768 WhlGrndVlctyRtNnDrvn "UNM";
BA_ "SignalLongName" SG_ 2154528768 WhlGrndVlctyRtNnDrvn "Wheel Ground Velocity Right Non Driven";
BA_ "VNSigAllNodes" SG_ 2154528768 WhlGrndVlctyRtNnDrvn 1;
BA_ "SignalType" SG_ 2154528768 WhlGrndVlctyRtDrvnV "ENM";
BA_ "SignalLongName" SG_ 2154528768 WhlGrndVlctyRtDrvnV "Wheel Ground Velocity Right Driven Validity";
BA_ "VNSigAllNodes" SG_ 2154528768 WhlGrndVlctyRtDrvnV 1;
BA_ "SignalType" SG_ 2154528768 WhlGrndVlctyRtDrvn "UNM";
BA_ "SignalLongName" SG_ 2154528768 WhlGrndVlctyRtDrvn "Wheel Ground Velocity Right Driven";
BA_ "VNSigAllNodes" SG_ 2154528768 WhlGrndVlctyRtDrvn 1;
BA_ "SignalType" SG_ 2154528768 WhlGrndVlctyLftNnDrvnV "ENM";
BA_ "SignalLongName" SG_ 2154528768 WhlGrndVlctyLftNnDrvnV "Wheel Ground Velocity Left Non Driven Validity";
BA_ "VNSigAllNodes" SG_ 2154528768 WhlGrndVlctyLftNnDrvnV 1;
BA_ "SignalType" SG_ 2154528768 WhlGrndVlctyLftNnDrvn "UNM";
BA_ "SignalLongName" SG_ 2154528768 WhlGrndVlctyLftNnDrvn "Wheel Ground Velocity Left Non Driven";
BA_ "VNSigAllNodes" SG_ 2154528768 WhlGrndVlctyLftNnDrvn 1;
BA_ "SignalType" SG_ 2154528768 WhlGrndVlctyLftDrvnV "ENM";
BA_ "SignalLongName" SG_ 2154528768 WhlGrndVlctyLftDrvnV "Wheel Ground Velocity Left Driven Validity";
BA_ "VNSigAllNodes" SG_ 2154528768 WhlGrndVlctyLftDrvnV 1;
BA_ "SignalType" SG_ 2154528768 WhlGrndVlctyLftDrvn "UNM";
BA_ "SignalLongName" SG_ 2154528768 WhlGrndVlctyLftDrvn "Wheel Ground Velocity Left Driven";
BA_ "VNSigAllNodes" SG_ 2154528768 WhlGrndVlctyLftDrvn 1;
BA_ "GenSigSendType" SG_ 2150916096 PrkHtrCoolntTempM 10;
BA_ "VNSigIntermediate" SG_ 2150916096 PrkHtrCoolntTempM 1;
BA_ "SignalType" SG_ 2150916096 PrkHtrCoolntTempM "ENM";
BA_ "SignalLongName" SG_ 2150916096 PrkHtrCoolntTempM "Park Heater Coolant Temperature Mask";
BA_ "VNSigAllNodes" SG_ 2150916096 PrkHtrCoolntTempM 1;
BA_ "GenSigSendType" SG_ 2150916096 PrkHtrPrhtAch 10;
BA_ "GenSigSendOnInit" SG_ 2150916096 PrkHtrPrhtAch 1;
BA_ "VNSigIntermediate" SG_ 2150916096 PrkHtrPrhtAch 1;
BA_ "SignalType" SG_ 2150916096 PrkHtrPrhtAch "BLN";
BA_ "SignalLongName" SG_ 2150916096 PrkHtrPrhtAch "Park Heater Preheat Achieved";
BA_ "VNSigAllNodes" SG_ 2150916096 PrkHtrPrhtAch 1;
BA_ "GenSigSendType" SG_ 2150916096 PrkHtrFlCnsmdRolCntV 10;
BA_ "GenSigSendOnInit" SG_ 2150916096 PrkHtrFlCnsmdRolCntV 1;
BA_ "SignalType" SG_ 2150916096 PrkHtrFlCnsmdRolCntV "ENM";
BA_ "SignalLongName" SG_ 2150916096 PrkHtrFlCnsmdRolCntV "Park Heater Fuel Consumed Rolling Count Validity";
BA_ "VNSigAllNodes" SG_ 2150916096 PrkHtrFlCnsmdRolCntV 1;
BA_ "GenSigSendType" SG_ 2150916096 PrkHtrFlCsmdRlCntRsOc 10;
BA_ "GenSigSendOnInit" SG_ 2150916096 PrkHtrFlCsmdRlCntRsOc 1;
BA_ "SignalType" SG_ 2150916096 PrkHtrFlCsmdRlCntRsOc "BLN";
BA_ "SignalLongName" SG_ 2150916096 PrkHtrFlCsmdRlCntRsOc "Park Heater Fuel Consumed Rolling Count Reset Occurred";
BA_ "VNSigAllNodes" SG_ 2150916096 PrkHtrFlCsmdRlCntRsOc 1;
BA_ "GenSigDeltaValue" SG_ 2150916096 PrkHtrFlCnsmdRolCnt 1;
BA_ "GenSigSendType" SG_ 2150916096 PrkHtrFlCnsmdRolCnt 12;
BA_ "GenSigSendOnInit" SG_ 2150916096 PrkHtrFlCnsmdRolCnt 1;
BA_ "SignalType" SG_ 2150916096 PrkHtrFlCnsmdRolCnt "UNM";
BA_ "SignalLongName" SG_ 2150916096 PrkHtrFlCnsmdRolCnt "Park Heater Fuel Consumed Rolling Count";
BA_ "VNSigAllNodes" SG_ 2150916096 PrkHtrFlCnsmdRolCnt 1;
BA_ "GenSigSendType" SG_ 2150916096 PrkHtrCoolntTempV 10;
BA_ "GenSigSendOnInit" SG_ 2150916096 PrkHtrCoolntTempV 1;
BA_ "VNSigIntermediate" SG_ 2150916096 PrkHtrCoolntTempV 1;
BA_ "SignalType" SG_ 2150916096 PrkHtrCoolntTempV "ENM";
BA_ "SignalLongName" SG_ 2150916096 PrkHtrCoolntTempV "Park Heater Coolant Temperature Validity";
BA_ "VNSigAllNodes" SG_ 2150916096 PrkHtrCoolntTempV 1;
BA_ "GenSigDeltaValue" SG_ 2150916096 PrkHtrCoolntTemp 1;
BA_ "GenSigSendType" SG_ 2150916096 PrkHtrCoolntTemp 12;
BA_ "GenSigSendOnInit" SG_ 2150916096 PrkHtrCoolntTemp 1;
BA_ "VNSigIntermediate" SG_ 2150916096 PrkHtrCoolntTemp 1;
BA_ "SignalType" SG_ 2150916096 PrkHtrCoolntTemp "UNM";
BA_ "SignalLongName" SG_ 2150916096 PrkHtrCoolntTemp "Park Heater Coolant Temperature";
BA_ "VNSigAllNodes" SG_ 2150916096 PrkHtrCoolntTemp 1;
BA_ "GenSigSendType" SG_ 2150916096 ClntCircPmpAct 10;
BA_ "GenSigSendOnInit" SG_ 2150916096 ClntCircPmpAct 1;
BA_ "VNSigIntermediate" SG_ 2150916096 ClntCircPmpAct 1;
BA_ "SignalType" SG_ 2150916096 ClntCircPmpAct "BLN";
BA_ "SignalLongName" SG_ 2150916096 ClntCircPmpAct "Coolant Circulation Pump Active";
BA_ "VNSigAllNodes" SG_ 2150916096 ClntCircPmpAct 1;
BA_ "GenSigSendType" SG_ 2150916096 PrkHtrAtv 10;
BA_ "GenSigSendOnInit" SG_ 2150916096 PrkHtrAtv 1;
BA_ "VNSigIntermediate" SG_ 2150916096 PrkHtrAtv 1;
BA_ "SignalType" SG_ 2150916096 PrkHtrAtv "BLN";
BA_ "SignalLongName" SG_ 2150916096 PrkHtrAtv "Park Heater Active";
BA_ "VNSigAllNodes" SG_ 2150916096 PrkHtrAtv 1;
BA_ "GenSigSendOnInit" SG_ 2150367232 LrnEnvIdSt 2;
BA_ "SignalType" SG_ 2150367232 LrnEnvIdSt "ENM";
BA_ "SignalLongName" SG_ 2150367232 LrnEnvIdSt "Learn Environment Identification Status";
BA_ "VNSigAllNodes" SG_ 2150367232 LrnEnvIdSt 1;
BA_ "GenSigSendOnInit" SG_ 2150367232 LrnEnvId 2;
BA_ "SignalType" SG_ 2150367232 LrnEnvId "UNM";
BA_ "SignalLongName" SG_ 2150367232 LrnEnvId "Learn Environment Identification";
BA_ "VNSigAllNodes" SG_ 2150367232 LrnEnvId 1;
BA_ "GenSigSendOnInit" SG_ 2150367232 ImoId 2;
BA_ "SignalType" SG_ 2150367232 ImoId "UNM";
BA_ "SignalLongName" SG_ 2150367232 ImoId "Immobilizer Identifier";
BA_ "VNSigAllNodes" SG_ 2150367232 ImoId 1;
BA_ "GenSigSendOnInit" SG_ 2150367232 ImoIdSt 2;
BA_ "SignalType" SG_ 2150367232 ImoIdSt "ENM";
BA_ "SignalLongName" SG_ 2150367232 ImoIdSt "Immobilizer Identifier Status";
BA_ "VNSigAllNodes" SG_ 2150367232 ImoIdSt 1;
BA_ "GenSigSendType" SG_ 2150621184 KSARUID8 10;
BA_ "SignalType" SG_ 2150621184 KSARUID8 "ENM";
BA_ "PacketOrder" SG_ 2150621184 KSARUID8 8;
BA_ "SignalLongName" SG_ 2150621184 KSARUID8 "Keyless Start Authentification Result : UserIdentity8";
BA_ "VNSigAllNodes" SG_ 2150621184 KSARUID8 1;
BA_ "GenSigSendType" SG_ 2150621184 KSARUID7 10;
BA_ "SignalType" SG_ 2150621184 KSARUID7 "ENM";
BA_ "PacketOrder" SG_ 2150621184 KSARUID7 7;
BA_ "SignalLongName" SG_ 2150621184 KSARUID7 "Keyless Start Authentification Result : UserIdentity7";
BA_ "VNSigAllNodes" SG_ 2150621184 KSARUID7 1;
BA_ "GenSigSendType" SG_ 2150621184 KSARUID6 10;
BA_ "SignalType" SG_ 2150621184 KSARUID6 "ENM";
BA_ "PacketOrder" SG_ 2150621184 KSARUID6 6;
BA_ "SignalLongName" SG_ 2150621184 KSARUID6 "Keyless Start Authentification Result : UserIdentity6";
BA_ "VNSigAllNodes" SG_ 2150621184 KSARUID6 1;
BA_ "GenSigSendType" SG_ 2150621184 KSARUID5 10;
BA_ "SignalType" SG_ 2150621184 KSARUID5 "ENM";
BA_ "PacketOrder" SG_ 2150621184 KSARUID5 5;
BA_ "SignalLongName" SG_ 2150621184 KSARUID5 "Keyless Start Authentification Result : UserIdentity5";
BA_ "VNSigAllNodes" SG_ 2150621184 KSARUID5 1;
BA_ "GenSigSendType" SG_ 2150621184 KSARUID4 10;
BA_ "SignalType" SG_ 2150621184 KSARUID4 "ENM";
BA_ "PacketOrder" SG_ 2150621184 KSARUID4 4;
BA_ "SignalLongName" SG_ 2150621184 KSARUID4 "Keyless Start Authentification Result : UserIdentity4";
BA_ "VNSigAllNodes" SG_ 2150621184 KSARUID4 1;
BA_ "GenSigSendType" SG_ 2150621184 KSARUID3 10;
BA_ "SignalType" SG_ 2150621184 KSARUID3 "ENM";
BA_ "PacketOrder" SG_ 2150621184 KSARUID3 3;
BA_ "SignalLongName" SG_ 2150621184 KSARUID3 "Keyless Start Authentification Result : UserIdentity3";
BA_ "VNSigAllNodes" SG_ 2150621184 KSARUID3 1;
BA_ "GenSigSendType" SG_ 2150621184 KSARUID2 10;
BA_ "SignalType" SG_ 2150621184 KSARUID2 "ENM";
BA_ "PacketOrder" SG_ 2150621184 KSARUID2 2;
BA_ "SignalLongName" SG_ 2150621184 KSARUID2 "Keyless Start Authentification Result : UserIdentity2";
BA_ "VNSigAllNodes" SG_ 2150621184 KSARUID2 1;
BA_ "GenSigSendType" SG_ 2150621184 KSARUID1 10;
BA_ "SignalType" SG_ 2150621184 KSARUID1 "ENM";
BA_ "PacketOrder" SG_ 2150621184 KSARUID1 1;
BA_ "SignalLongName" SG_ 2150621184 KSARUID1 "Keyless Start Authentification Result : UserIdentity1";
BA_ "VNSigAllNodes" SG_ 2150621184 KSARUID1 1;
BA_ "GenSigSendType" SG_ 2151309312 InflRestId 10;
BA_ "GenSigSendOnInit" SG_ 2151309312 InflRestId 2;
BA_ "SignalType" SG_ 2151309312 InflRestId "BCD";
BA_ "SignalLongName" SG_ 2151309312 InflRestId "Inflatable Restraints Keying Identifier";
BA_ "VNSigAllNodes" SG_ 2151309312 InflRestId 1;
BA_ "GenSigSendType" SG_ 2154061824 WndOprAlwd 10;
BA_ "SignalType" SG_ 2154061824 WndOprAlwd "BLN";
BA_ "SignalLongName" SG_ 2154061824 WndOprAlwd "Window Operation Allowed";
BA_ "VNSigAllNodes" SG_ 2154061824 WndOprAlwd 1;
BA_ "GenSigSendType" SG_ 2154061824 RrDrUnlckIO 10;
BA_ "SignalType" SG_ 2154061824 RrDrUnlckIO "BLN";
BA_ "SignalLongName" SG_ 2154061824 RrDrUnlckIO "Rear Door Unlock Indication On";
BA_ "VNSigAllNodes" SG_ 2154061824 RrDrUnlckIO 1;
BA_ "GenSigSendType" SG_ 2154061824 RmtWndMvmntAtv 10;
BA_ "SignalType" SG_ 2154061824 RmtWndMvmntAtv "BLN";
BA_ "SignalLongName" SG_ 2154061824 RmtWndMvmntAtv "Remote Window Movement Active";
BA_ "VNSigAllNodes" SG_ 2154061824 RmtWndMvmntAtv 1;
BA_ "GenSigSendType" SG_ 2154061824 RRWndNtNrmIndOn 10;
BA_ "SignalType" SG_ 2154061824 RRWndNtNrmIndOn "BLN";
BA_ "SignalLongName" SG_ 2154061824 RRWndNtNrmIndOn "Rear Right Window Not Normalized Indication On";
BA_ "VNSigAllNodes" SG_ 2154061824 RRWndNtNrmIndOn 1;
BA_ "GenSigSendType" SG_ 2154061824 RLWndNtNrmIndOn 10;
BA_ "SignalType" SG_ 2154061824 RLWndNtNrmIndOn "BLN";
BA_ "SignalLongName" SG_ 2154061824 RLWndNtNrmIndOn "Rear Left Window Not Normalized Indication On";
BA_ "VNSigAllNodes" SG_ 2154061824 RLWndNtNrmIndOn 1;
BA_ "GenSigSendType" SG_ 2154061824 DrWndNtNrmIndOn 10;
BA_ "GenSigSendOnInit" SG_ 2154061824 DrWndNtNrmIndOn 2;
BA_ "SignalType" SG_ 2154061824 DrWndNtNrmIndOn "BLN";
BA_ "SignalLongName" SG_ 2154061824 DrWndNtNrmIndOn "Driver Window Not Normalized Indication On";
BA_ "VNSigAllNodes" SG_ 2154061824 DrWndNtNrmIndOn 1;
BA_ "GenSigSendType" SG_ 2154061824 PsWndNtNrmIndOn 10;
BA_ "SignalType" SG_ 2154061824 PsWndNtNrmIndOn "BLN";
BA_ "SignalLongName" SG_ 2154061824 PsWndNtNrmIndOn "Passenger Window Not Normalized Indication On";
BA_ "VNSigAllNodes" SG_ 2154061824 PsWndNtNrmIndOn 1;
BA_ "GenSigSendType" SG_ 2154512384 RrClosRelSwActV 10;
BA_ "GenSigSendOnInit" SG_ 2154512384 RrClosRelSwActV 1;
BA_ "SignalType" SG_ 2154512384 RrClosRelSwActV "ENM";
BA_ "SignalLongName" SG_ 2154512384 RrClosRelSwActV "Rear Closure Release Switch Active Validity";
BA_ "VNSigAllNodes" SG_ 2154512384 RrClosRelSwActV 1;
BA_ "GenSigSendType" SG_ 2154512384 RrClosRelSwAct 10;
BA_ "GenSigSendOnInit" SG_ 2154512384 RrClosRelSwAct 1;
BA_ "SignalType" SG_ 2154512384 RrClosRelSwAct "BLN";
BA_ "SignalLongName" SG_ 2154512384 RrClosRelSwAct "Rear Closure Release Switch Active";
BA_ "VNSigAllNodes" SG_ 2154512384 RrClosRelSwAct 1;
BA_ "SignalType" SG_ 2155347968 DrvrStPerfMdCsCrStVal "ENM";
BA_ "SignalLongName" SG_ 2155347968 DrvrStPerfMdCsCrStVal "Driver Seat Performance Mode Customization Current Setting Value";
BA_ "VNSigAllNodes" SG_ 2155347968 DrvrStPerfMdCsCrStVal 1;
BA_ "SignalType" SG_ 2155347968 DrvrStPerfMdCsStAvl "BLN";
BA_ "SignalLongName" SG_ 2155347968 DrvrStPerfMdCsStAvl "Driver Seat Performance Mode Customization Setting Available";
BA_ "VNSigAllNodes" SG_ 2155347968 DrvrStPerfMdCsStAvl 1;
BA_ "SignalType" SG_ 2155347968 ACCPerfMdCsCrStVal "ENM";
BA_ "SignalLongName" SG_ 2155347968 ACCPerfMdCsCrStVal "Adaptive Cruise Control Performance Mode Customization Current Setting Value";
BA_ "VNSigAllNodes" SG_ 2155347968 ACCPerfMdCsCrStVal 1;
BA_ "SignalType" SG_ 2155347968 ACCPerfMdCsStAvl "BLN";
BA_ "SignalLongName" SG_ 2155347968 ACCPerfMdCsStAvl "Adaptive Cruise Control Performance Mode Customization Setting Available";
BA_ "VNSigAllNodes" SG_ 2155347968 ACCPerfMdCsStAvl 1;
BA_ "SignalType" SG_ 2155347968 VehRollAngleV "ENM";
BA_ "SignalLongName" SG_ 2155347968 VehRollAngleV "Vehicle Roll Angle Validity";
BA_ "VNSigAllNodes" SG_ 2155347968 VehRollAngleV 1;
BA_ "SignalType" SG_ 2155347968 VehRollAngle "UNM";
BA_ "SignalLongName" SG_ 2155347968 VehRollAngle "Vehicle Roll Angle";
BA_ "VNSigAllNodes" SG_ 2155347968 VehRollAngle 1;
BA_ "SignalType" SG_ 2155347968 ActVbnCtrlMlfIO "BLN";
BA_ "SignalLongName" SG_ 2155347968 ActVbnCtrlMlfIO "Active Vibration Control Malfunction Indication On";
BA_ "VNSigAllNodes" SG_ 2155347968 ActVbnCtrlMlfIO 1;
BA_ "SignalType" SG_ 2155347968 HillDesCtrlRedVehSpIO "BLN";
BA_ "SignalLongName" SG_ 2155347968 HillDesCtrlRedVehSpIO "Hill Descent Control Reduce Vehicle Speed Indication On";
BA_ "VNSigAllNodes" SG_ 2155347968 HillDesCtrlRedVehSpIO 1;
BA_ "SignalType" SG_ 2155347968 FourWhlDrvIndReq "ENM";
BA_ "SignalLongName" SG_ 2155347968 FourWhlDrvIndReq "Four Wheel Drive Indication Request";
BA_ "VNSigAllNodes" SG_ 2155347968 FourWhlDrvIndReq 1;
BA_ "SignalType" SG_ 2155347968 PedtrnProtVDA "ENM";
BA_ "SignalLongName" SG_ 2155347968 PedtrnProtVDA "Pedestrian Protection Virtual Device Availability";
BA_ "GenSigStartValue" SG_ 2155347968 PedtrnProtVDA 1;
BA_ "VNSigAllNodes" SG_ 2155347968 PedtrnProtVDA 1;
BA_ "SignalType" SG_ 2155347968 EngRecDwnshftIO "BLN";
BA_ "SignalLongName" SG_ 2155347968 EngRecDwnshftIO "Engine Recommended Downshift Indication On";
BA_ "VNSigAllNodes" SG_ 2155347968 EngRecDwnshftIO 1;
BA_ "SignalType" SG_ 2155347968 AppCltchAutSrtIO "BLN";
BA_ "SignalLongName" SG_ 2155347968 AppCltchAutSrtIO "Apply Clutch For Automatic Start Indication On";
BA_ "VNSigAllNodes" SG_ 2155347968 AppCltchAutSrtIO 1;
BA_ "SignalType" SG_ 2155347968 CPSUnblIO "BLN";
BA_ "SignalLongName" SG_ 2155347968 CPSUnblIO "Collision Preparation System Unavailable Indication On";
BA_ "VNSigAllNodes" SG_ 2155347968 CPSUnblIO 1;
BA_ "SignalType" SG_ 2155347968 StBltTgtSetAvl "BLN";
BA_ "SignalLongName" SG_ 2155347968 StBltTgtSetAvl "Seat Belt Tightening Settings Available";
BA_ "VNSigAllNodes" SG_ 2155347968 StBltTgtSetAvl 1;
BA_ "SignalType" SG_ 2155347968 StBltTgtCrtSetVal "ENM";
BA_ "SignalLongName" SG_ 2155347968 StBltTgtCrtSetVal "Seat Belt Tightening Current Setting Value";
BA_ "VNSigAllNodes" SG_ 2155347968 StBltTgtCrtSetVal 1;
BA_ "SignalType" SG_ 2155347968 PedtrnProtSysDisbld "BLN";
BA_ "SignalLongName" SG_ 2155347968 PedtrnProtSysDisbld "Pedestrian Protection System Disabled";
BA_ "VNSigAllNodes" SG_ 2155347968 PedtrnProtSysDisbld 1;
BA_ "SignalType" SG_ 2155347968 PedtrnProtSysDpl "BLN";
BA_ "SignalLongName" SG_ 2155347968 PedtrnProtSysDpl "Pedestrian Protection System Deployed";
BA_ "VNSigAllNodes" SG_ 2155347968 PedtrnProtSysDpl 1;
BA_ "SignalType" SG_ 2155347968 SrvPedtrnProtSysIO "BLN";
BA_ "SignalLongName" SG_ 2155347968 SrvPedtrnProtSysIO "Service Pedestrian Protection System Indication On";
BA_ "VNSigAllNodes" SG_ 2155347968 SrvPedtrnProtSysIO 1;
BA_ "SignalType" SG_ 2155347968 CPSOffIO "BLN";
BA_ "SignalLongName" SG_ 2155347968 CPSOffIO "Collision Preparation System Off Indication On";
BA_ "VNSigAllNodes" SG_ 2155347968 CPSOffIO 1;
BA_ "SignalType" SG_ 2155347968 SecAxlTmpInhIO "BLN";
BA_ "SignalLongName" SG_ 2155347968 SecAxlTmpInhIO "Secondary Axle Temporary Inhibit Indication On";
BA_ "VNSigAllNodes" SG_ 2155347968 SecAxlTmpInhIO 1;
BA_ "SignalType" SG_ 2155347968 CPSFldIO "BLN";
BA_ "SignalLongName" SG_ 2155347968 CPSFldIO "Collision Preparation System Failed Indication On";
BA_ "VNSigAllNodes" SG_ 2155347968 CPSFldIO 1;
BA_ "SignalType" SG_ 2155347968 CPSAlrtOnlIO "BLN";
BA_ "SignalLongName" SG_ 2155347968 CPSAlrtOnlIO "Collision Preparation System Alert Only Indication On";
BA_ "VNSigAllNodes" SG_ 2155347968 CPSAlrtOnlIO 1;
BA_ "SignalType" SG_ 2155347968 RrAxlTmpInhIO "BLN";
BA_ "SignalLongName" SG_ 2155347968 RrAxlTmpInhIO "Rear Axle Temporary Inhibit Indication On";
BA_ "VNSigAllNodes" SG_ 2155347968 RrAxlTmpInhIO 1;
BA_ "SignalType" SG_ 2155347968 TirePrsLowIO "BLN";
BA_ "SignalLongName" SG_ 2155347968 TirePrsLowIO "Tire Pressure Low Indication On";
BA_ "VNSigAllNodes" SG_ 2155347968 TirePrsLowIO 1;
BA_ "SignalType" SG_ 2155347968 EPBSysStatIndReq "ENM";
BA_ "SignalLongName" SG_ 2155347968 EPBSysStatIndReq "Electric Park Brake System Status Indication Request";
BA_ "VNSigAllNodes" SG_ 2155347968 EPBSysStatIndReq 1;
BA_ "SignalType" SG_ 2155347968 EngOilStrvtnIO "BLN";
BA_ "SignalLongName" SG_ 2155347968 EngOilStrvtnIO "Engine Oil Starvation Indication On";
BA_ "VNSigAllNodes" SG_ 2155347968 EngOilStrvtnIO 1;
BA_ "SignalType" SG_ 2155347968 SrvSuspSysIO "BLN";
BA_ "SignalLongName" SG_ 2155347968 SrvSuspSysIO "Service Suspension System Indication On";
BA_ "VNSigAllNodes" SG_ 2155347968 SrvSuspSysIO 1;
BA_ "SignalType" SG_ 2155347968 ServAdpCrsCtrlIndOn "BLN";
BA_ "SignalLongName" SG_ 2155347968 ServAdpCrsCtrlIndOn "Service Adaptive Cruise Control Indication On";
BA_ "VNSigAllNodes" SG_ 2155347968 ServAdpCrsCtrlIndOn 1;
BA_ "SignalType" SG_ 2155347968 EngRecmndUpshftIO "BLN";
BA_ "SignalLongName" SG_ 2155347968 EngRecmndUpshftIO "Engine Recommended Upshift Indication On";
BA_ "VNSigAllNodes" SG_ 2155347968 EngRecmndUpshftIO 1;
BA_ "SignalType" SG_ 2155347968 BrkSysMalFuncIndOn "BLN";
BA_ "SignalLongName" SG_ 2155347968 BrkSysMalFuncIndOn "Brake System Malfunction Indication On";
BA_ "VNSigAllNodes" SG_ 2155347968 BrkSysMalFuncIndOn 1;
BA_ "SignalType" SG_ 2155347968 SecAxlNonEmMalfIO "BLN";
BA_ "SignalLongName" SG_ 2155347968 SecAxlNonEmMalfIO "Secondary Axle Non-emissions Malf Ind On";
BA_ "VNSigAllNodes" SG_ 2155347968 SecAxlNonEmMalfIO 1;
BA_ "SignalType" SG_ 2155347968 BrkFldLvlLw "BLN";
BA_ "SignalLongName" SG_ 2155347968 BrkFldLvlLw "Brake Fluid Level Low";
BA_ "VNSigAllNodes" SG_ 2155347968 BrkFldLvlLw 1;
BA_ "SignalType" SG_ 2155347968 ACCUnavlbleDTWthrIO "BLN";
BA_ "SignalLongName" SG_ 2155347968 ACCUnavlbleDTWthrIO "Adaptive Cruise Unavailable Due To Weather Indication On";
BA_ "VNSigAllNodes" SG_ 2155347968 ACCUnavlbleDTWthrIO 1;
BA_ "SignalType" SG_ 2155347968 ACCTmpUnavlbleIO "BLN";
BA_ "SignalLongName" SG_ 2155347968 ACCTmpUnavlbleIO "Adaptive Cruise Control Temporarily Unavailable Indication On";
BA_ "VNSigAllNodes" SG_ 2155347968 ACCTmpUnavlbleIO 1;
BA_ "SignalType" SG_ 2155347968 EngEmsRelMalfIndReq "ENM";
BA_ "SignalLongName" SG_ 2155347968 EngEmsRelMalfIndReq "Engine Emissions Related Malfunction Indication Request";
BA_ "VNSigAllNodes" SG_ 2155347968 EngEmsRelMalfIndReq 1;
BA_ "SignalType" SG_ 2155347968 DrShftCntrlReqDndIO "BLN";
BA_ "SignalLongName" SG_ 2155347968 DrShftCntrlReqDndIO "Driver Shift Control Request Denied Indication On";
BA_ "VNSigAllNodes" SG_ 2155347968 DrShftCntrlReqDndIO 1;
BA_ "SignalType" SG_ 2155347968 BrkPadWrnIO "BLN";
BA_ "SignalLongName" SG_ 2155347968 BrkPadWrnIO "Brake Pad Worn Indication On";
BA_ "VNSigAllNodes" SG_ 2155347968 BrkPadWrnIO 1;
BA_ "SignalType" SG_ 2155347968 RrAxlMalfIO "BLN";
BA_ "SignalLongName" SG_ 2155347968 RrAxlMalfIO "Rear Axle Malfunction Indication On";
BA_ "VNSigAllNodes" SG_ 2155347968 RrAxlMalfIO 1;
BA_ "SignalType" SG_ 2155347968 EPBSysWrnIndReq "ENM";
BA_ "SignalLongName" SG_ 2155347968 EPBSysWrnIndReq "Electric Park Brake System Warning Indication Request";
BA_ "VNSigAllNodes" SG_ 2155347968 EPBSysWrnIndReq 1;
BA_ "SignalType" SG_ 2155347968 CompOvrhtIndOn "BLN";
BA_ "SignalLongName" SG_ 2155347968 CompOvrhtIndOn "Compressor Overheated Indication On";
BA_ "VNSigAllNodes" SG_ 2155347968 CompOvrhtIndOn 1;
BA_ "SignalType" SG_ 2155347968 BrkFldLvlLwV "ENM";
BA_ "SignalLongName" SG_ 2155347968 BrkFldLvlLwV "Brake Fluid Level Low Validity";
BA_ "VNSigAllNodes" SG_ 2155347968 BrkFldLvlLwV 1;
BA_ "SignalType" SG_ 2155347968 ACCSnsClnRqdIO "BLN";
BA_ "SignalLongName" SG_ 2155347968 ACCSnsClnRqdIO "Adaptive Cruise Control Sensor Cleaning Required Indication On";
BA_ "VNSigAllNodes" SG_ 2155347968 ACCSnsClnRqdIO 1;
BA_ "SignalType" SG_ 2155347968 TrnsSkpShftIO "BLN";
BA_ "SignalLongName" SG_ 2155347968 TrnsSkpShftIO "Transmission Skip Shift Indication On";
BA_ "VNSigAllNodes" SG_ 2155347968 TrnsSkpShftIO 1;
BA_ "SignalType" SG_ 2149777408 WRSLNDWhlDisTpRC "UNM";
BA_ "PacketOrder" SG_ 2149777408 WRSLNDWhlDisTpRC 1;
BA_ "SignalLongName" SG_ 2149777408 WRSLNDWhlDisTpRC "Wheel Rotational Status Left Non Driven : Wheel Distance Timestamp Rollover Counter";
BA_ "VNSigAllNodes" SG_ 2149777408 WRSLNDWhlDisTpRC 1;
BA_ "SignalType" SG_ 2149777408 WRSLNDWhlRotStRst "BLN";
BA_ "PacketOrder" SG_ 2149777408 WRSLNDWhlRotStRst 3;
BA_ "SignalLongName" SG_ 2149777408 WRSLNDWhlRotStRst "Wheel Rotational Status Left Non Driven : Wheel Rotational Status Reset Occurred";
BA_ "VNSigAllNodes" SG_ 2149777408 WRSLNDWhlRotStRst 1;
BA_ "SignalType" SG_ 2149777408 WRSLNDWhlDistVal "ENM";
BA_ "PacketOrder" SG_ 2149777408 WRSLNDWhlDistVal 4;
BA_ "SignalLongName" SG_ 2149777408 WRSLNDWhlDistVal "Wheel Rotational Status Left Non Driven : Wheel Distance Validity";
BA_ "VNSigAllNodes" SG_ 2149777408 WRSLNDWhlDistVal 1;
BA_ "SignalType" SG_ 2149777408 WRSLNDWhlDistTstm "UNM";
BA_ "PacketOrder" SG_ 2149777408 WRSLNDWhlDistTstm 6;
BA_ "SignalLongName" SG_ 2149777408 WRSLNDWhlDistTstm "Wheel Rotational Status Left Non Driven : Wheel Distance Timestamp";
BA_ "VNSigAllNodes" SG_ 2149777408 WRSLNDWhlDistTstm 1;
BA_ "SignalType" SG_ 2149777408 WRSLNDWhlDistPCntr "UNM";
BA_ "PacketOrder" SG_ 2149777408 WRSLNDWhlDistPCntr 5;
BA_ "SignalLongName" SG_ 2149777408 WRSLNDWhlDistPCntr "Wheel Rotational Status Left Non Driven : Wheel Distance Pulse Counter";
BA_ "VNSigAllNodes" SG_ 2149777408 WRSLNDWhlDistPCntr 1;
BA_ "SignalType" SG_ 2149777408 WRSLNDSeqNum "UNM";
BA_ "PacketOrder" SG_ 2149777408 WRSLNDSeqNum 2;
BA_ "SignalLongName" SG_ 2149777408 WRSLNDSeqNum "Wheel Rotational Status Left Non Driven : Sequence Number";
BA_ "VNSigAllNodes" SG_ 2149777408 WRSLNDSeqNum 1;
BA_ "SignalType" SG_ 2149777408 WRSRNDWhlDisTpRC "UNM";
BA_ "PacketOrder" SG_ 2149777408 WRSRNDWhlDisTpRC 1;
BA_ "SignalLongName" SG_ 2149777408 WRSRNDWhlDisTpRC "Wheel Rotational Status Right Non Driven : Wheel Distance Timestamp Rollover Counter";
BA_ "VNSigAllNodes" SG_ 2149777408 WRSRNDWhlDisTpRC 1;
BA_ "SignalType" SG_ 2149777408 WRSRNDWhlRotStRst "BLN";
BA_ "PacketOrder" SG_ 2149777408 WRSRNDWhlRotStRst 3;
BA_ "SignalLongName" SG_ 2149777408 WRSRNDWhlRotStRst "Wheel Rotational Status Right Non Driven : Wheel Rotational Status Reset Occurred";
BA_ "VNSigAllNodes" SG_ 2149777408 WRSRNDWhlRotStRst 1;
BA_ "SignalType" SG_ 2149777408 WRSRNDWhlDistVal "ENM";
BA_ "PacketOrder" SG_ 2149777408 WRSRNDWhlDistVal 4;
BA_ "SignalLongName" SG_ 2149777408 WRSRNDWhlDistVal "Wheel Rotational Status Right Non Driven : Wheel Distance Validity";
BA_ "VNSigAllNodes" SG_ 2149777408 WRSRNDWhlDistVal 1;
BA_ "SignalType" SG_ 2149777408 WRSRNDWhlDistTstm "UNM";
BA_ "PacketOrder" SG_ 2149777408 WRSRNDWhlDistTstm 6;
BA_ "SignalLongName" SG_ 2149777408 WRSRNDWhlDistTstm "Wheel Rotational Status Right Non Driven : Wheel Distance Timestamp";
BA_ "VNSigAllNodes" SG_ 2149777408 WRSRNDWhlDistTstm 1;
BA_ "SignalType" SG_ 2149777408 WRSRNDWhlDistPCntr "UNM";
BA_ "PacketOrder" SG_ 2149777408 WRSRNDWhlDistPCntr 5;
BA_ "SignalLongName" SG_ 2149777408 WRSRNDWhlDistPCntr "Wheel Rotational Status Right Non Driven : Wheel Distance Pulse Counter";
BA_ "VNSigAllNodes" SG_ 2149777408 WRSRNDWhlDistPCntr 1;
BA_ "SignalType" SG_ 2149777408 WRSRNDSeqNum "UNM";
BA_ "PacketOrder" SG_ 2149777408 WRSRNDSeqNum 2;
BA_ "SignalLongName" SG_ 2149777408 WRSRNDSeqNum "Wheel Rotational Status Right Non Driven : Sequence Number";
BA_ "VNSigAllNodes" SG_ 2149777408 WRSRNDSeqNum 1;
BA_ "SignalType" SG_ 2149769216 WRSLDWhlDisTpRC "UNM";
BA_ "PacketOrder" SG_ 2149769216 WRSLDWhlDisTpRC 1;
BA_ "SignalLongName" SG_ 2149769216 WRSLDWhlDisTpRC "Wheel Rotational Status Left Driven : Wheel Distance Timestamp Rollover Counter";
BA_ "VNSigAllNodes" SG_ 2149769216 WRSLDWhlDisTpRC 1;
BA_ "SignalType" SG_ 2149769216 WRSLDSeqNum "UNM";
BA_ "PacketOrder" SG_ 2149769216 WRSLDSeqNum 2;
BA_ "SignalLongName" SG_ 2149769216 WRSLDSeqNum "Wheel Rotational Status Left Driven : Sequence Number";
BA_ "VNSigAllNodes" SG_ 2149769216 WRSLDSeqNum 1;
BA_ "SignalType" SG_ 2149769216 WRSLDWhlDistVal "ENM";
BA_ "PacketOrder" SG_ 2149769216 WRSLDWhlDistVal 4;
BA_ "SignalLongName" SG_ 2149769216 WRSLDWhlDistVal "Wheel Rotational Status Left Driven : Wheel Distance Validity";
BA_ "VNSigAllNodes" SG_ 2149769216 WRSLDWhlDistVal 1;
BA_ "SignalType" SG_ 2149769216 WRSLDWhlRotStatRst "BLN";
BA_ "PacketOrder" SG_ 2149769216 WRSLDWhlRotStatRst 3;
BA_ "SignalLongName" SG_ 2149769216 WRSLDWhlRotStatRst "Wheel Rotational Status Left Driven : Wheel Rotational Status Reset Occurred";
BA_ "VNSigAllNodes" SG_ 2149769216 WRSLDWhlRotStatRst 1;
BA_ "SignalType" SG_ 2149769216 WRSLDWhlDistTmstm "UNM";
BA_ "PacketOrder" SG_ 2149769216 WRSLDWhlDistTmstm 6;
BA_ "SignalLongName" SG_ 2149769216 WRSLDWhlDistTmstm "Wheel Rotational Status Left Driven : Wheel Distance Timestamp";
BA_ "VNSigAllNodes" SG_ 2149769216 WRSLDWhlDistTmstm 1;
BA_ "SignalType" SG_ 2149769216 WRSLDWhlDistPlsCntr "UNM";
BA_ "PacketOrder" SG_ 2149769216 WRSLDWhlDistPlsCntr 5;
BA_ "SignalLongName" SG_ 2149769216 WRSLDWhlDistPlsCntr "Wheel Rotational Status Left Driven : Wheel Distance Pulse Counter";
BA_ "VNSigAllNodes" SG_ 2149769216 WRSLDWhlDistPlsCntr 1;
BA_ "SignalType" SG_ 2149769216 WRSRDWhlDisTpRC "UNM";
BA_ "PacketOrder" SG_ 2149769216 WRSRDWhlDisTpRC 1;
BA_ "SignalLongName" SG_ 2149769216 WRSRDWhlDisTpRC "Wheel Rotational Status Right Driven : Wheel Distance Timestamp Rollover Counter";
BA_ "VNSigAllNodes" SG_ 2149769216 WRSRDWhlDisTpRC 1;
BA_ "SignalType" SG_ 2149769216 WRSRDSeqNum "UNM";
BA_ "PacketOrder" SG_ 2149769216 WRSRDSeqNum 2;
BA_ "SignalLongName" SG_ 2149769216 WRSRDSeqNum "Wheel Rotational Status Right Driven : Sequence Number";
BA_ "VNSigAllNodes" SG_ 2149769216 WRSRDSeqNum 1;
BA_ "SignalType" SG_ 2149769216 WRSRDWhlRotStatRst "BLN";
BA_ "PacketOrder" SG_ 2149769216 WRSRDWhlRotStatRst 3;
BA_ "SignalLongName" SG_ 2149769216 WRSRDWhlRotStatRst "Wheel Rotational Status Right Driven : Wheel Rotational Status Reset Occurred";
BA_ "VNSigAllNodes" SG_ 2149769216 WRSRDWhlRotStatRst 1;
BA_ "SignalType" SG_ 2149769216 WRSRDWhlDistVal "ENM";
BA_ "PacketOrder" SG_ 2149769216 WRSRDWhlDistVal 4;
BA_ "SignalLongName" SG_ 2149769216 WRSRDWhlDistVal "Wheel Rotational Status Right Driven : Wheel Distance Validity";
BA_ "VNSigAllNodes" SG_ 2149769216 WRSRDWhlDistVal 1;
BA_ "SignalType" SG_ 2149769216 WRSRDWhlDistTmstm "UNM";
BA_ "PacketOrder" SG_ 2149769216 WRSRDWhlDistTmstm 6;
BA_ "SignalLongName" SG_ 2149769216 WRSRDWhlDistTmstm "Wheel Rotational Status Right Driven : Wheel Distance Timestamp";
BA_ "VNSigAllNodes" SG_ 2149769216 WRSRDWhlDistTmstm 1;
BA_ "SignalType" SG_ 2149769216 WRSRDWhlDistPlsCntr "UNM";
BA_ "PacketOrder" SG_ 2149769216 WRSRDWhlDistPlsCntr 5;
BA_ "SignalLongName" SG_ 2149769216 WRSRDWhlDistPlsCntr "Wheel Rotational Status Right Driven : Wheel Distance Pulse Counter";
BA_ "VNSigAllNodes" SG_ 2149769216 WRSRDWhlDistPlsCntr 1;
BA_REL_ "GenSigSuprvResp" BU_SG_REL_ EOCM2B_K2_LS SG_ 2158845952 ODIAC_FUCID 1;
BA_REL_ "GenSigSuprvResp" BU_SG_REL_ EOCM2A_K2_LS SG_ 2158845952 ODIAC_FUCID 1;
BA_REL_ "GenSigSuprvResp" BU_SG_REL_ EOCM_F_LS SG_ 2158845952 ODIAC_FUCID 1;
BA_REL_ "GenSigSuprvResp" BU_SG_REL_ EOCM_F_LS SG_ 2158845952 ODIAC_FUCID 1;
BA_REL_ "GenSigSuprvResp" BU_SG_REL_ UPA_LS SG_ 2158845952 ODIAC_FUCID 1;
BA_REL_ "GenSigSuprvResp" BU_SG_REL_ APA_LS SG_ 2158845952 ODIAC_FUCID 1;
BA_REL_ "GenSigSuprvResp" BU_SG_REL_ EOCM2B_K2_LS SG_ 2158845952 ODIAC_DspMID 1;
BA_REL_ "GenSigSuprvResp" BU_SG_REL_ EOCM2A_K2_LS SG_ 2158845952 ODIAC_DspMID 1;
BA_REL_ "GenSigSuprvResp" BU_SG_REL_ EOCM_F_LS SG_ 2158845952 ODIAC_DspMID 1;
BA_REL_ "GenSigSuprvResp" BU_SG_REL_ EOCM_F_LS SG_ 2158845952 ODIAC_DspMID 1;
BA_REL_ "GenSigSuprvResp" BU_SG_REL_ UPA_LS SG_ 2158845952 ODIAC_DspMID 1;
BA_REL_ "GenSigSuprvResp" BU_SG_REL_ APA_LS SG_ 2158845952 ODIAC_DspMID 1;
BA_REL_ "GenSigSuprvResp" BU_SG_REL_ EOCM2B_K2_LS SG_ 2158845952 ODIAC_DaTy 1;
BA_REL_ "GenSigSuprvResp" BU_SG_REL_ EOCM2A_K2_LS SG_ 2158845952 ODIAC_DaTy 1;
BA_REL_ "GenSigSuprvResp" BU_SG_REL_ EOCM_F_LS SG_ 2158845952 ODIAC_DaTy 1;
BA_REL_ "GenSigSuprvResp" BU_SG_REL_ EOCM_F_LS SG_ 2158845952 ODIAC_DaTy 1;
BA_REL_ "GenSigSuprvResp" BU_SG_REL_ UPA_LS SG_ 2158845952 ODIAC_DaTy 1;
BA_REL_ "GenSigSuprvResp" BU_SG_REL_ APA_LS SG_ 2158845952 ODIAC_DaTy 1;
BA_REL_ "GenSigSuprvResp" BU_SG_REL_ EOCM2B_K2_LS SG_ 2158845952 ODIAC_ActnVal 1;
BA_REL_ "GenSigSuprvResp" BU_SG_REL_ EOCM2A_K2_LS SG_ 2158845952 ODIAC_ActnVal 1;
BA_REL_ "GenSigSuprvResp" BU_SG_REL_ EOCM_F_LS SG_ 2158845952 ODIAC_ActnVal 1;
BA_REL_ "GenSigSuprvResp" BU_SG_REL_ EOCM_F_LS SG_ 2158845952 ODIAC_ActnVal 1;
BA_REL_ "GenSigSuprvResp" BU_SG_REL_ UPA_LS SG_ 2158845952 ODIAC_ActnVal 1;
BA_REL_ "GenSigSuprvResp" BU_SG_REL_ APA_LS SG_ 2158845952 ODIAC_ActnVal 1;
BA_REL_ "GenSigSuprvResp" BU_SG_REL_ EOCM2B_K2_LS SG_ 2158845952 ODIAC_ActnID 1;
BA_REL_ "GenSigSuprvResp" BU_SG_REL_ EOCM2A_K2_LS SG_ 2158845952 ODIAC_ActnID 1;
BA_REL_ "GenSigSuprvResp" BU_SG_REL_ EOCM_F_LS SG_ 2158845952 ODIAC_ActnID 1;
BA_REL_ "GenSigSuprvResp" BU_SG_REL_ EOCM_F_LS SG_ 2158845952 ODIAC_ActnID 1;
BA_REL_ "GenSigSuprvResp" BU_SG_REL_ UPA_LS SG_ 2158845952 ODIAC_ActnID 1;
BA_REL_ "GenSigSuprvResp" BU_SG_REL_ APA_LS SG_ 2158845952 ODIAC_ActnID 1;
BA_REL_ "GenSigSuprvResp" BU_SG_REL_ IPC_LS SG_ 2151366656 AxlLckUnavailIndReq 1;
BA_REL_ "GenSigVDAFailComment" BU_SG_REL_ IPC_LS SG_ 2151366656 AxlLcksServIO "AxlLcksVDA";
BA_REL_ "GenSigVDAFailResp" BU_SG_REL_ IPC_LS SG_ 2151366656 AxlLcksServIO 1;
BA_REL_ "GenSigSuprvResp" BU_SG_REL_ IPC_LS SG_ 2151366656 AxlLcksServIO 1;
BA_REL_ "GenSigVDAFailComment" BU_SG_REL_ IPC_LS SG_ 2151366656 RrAxlLckIO "AxlLcksVDA";
BA_REL_ "GenSigVDAFailResp" BU_SG_REL_ IPC_LS SG_ 2151366656 RrAxlLckIO 1;
BA_REL_ "GenSigSuprvResp" BU_SG_REL_ IPC_LS SG_ 2151366656 RrAxlLckIO 1;
BA_REL_ "GenSigVDAFailComment" BU_SG_REL_ IPC_LS SG_ 2151366656 FrntAxlLckIO "AxlLcksVDA";
BA_REL_ "GenSigVDAFailResp" BU_SG_REL_ IPC_LS SG_ 2151366656 FrntAxlLckIO 1;
BA_REL_ "GenSigSuprvResp" BU_SG_REL_ IPC_LS SG_ 2151366656 FrntAxlLckIO 1;
BA_REL_ "GenSigSuprvResp" BU_SG_REL_ ONSTAR_LS SG_ 2151366656 PrkBrkSwAtv 1;
BA_REL_ "GenSigSuprvResp" BU_SG_REL_ TCP_LS SG_ 2151366656 PrkBrkSwAtv 1;
BA_REL_ "GenSigSuprvResp" BU_SG_REL_ MSM_P_LS SG_ 2151366656 PrkBrkSwAtv 1;
BA_REL_ "GenSigSuprvResp" BU_SG_REL_ MSM_LS SG_ 2151366656 PrkBrkSwAtv 1;
BA_REL_ "GenSigSuprvResp" BU_SG_REL_ V2V_LS SG_ 2151366656 PrkBrkSwAtv 1;
BA_REL_ "GenSigSuprvResp" BU_SG_REL_ LVMNav_LS SG_ 2151366656 PrkBrkSwAtv 1;
BA_REL_ "GenSigSuprvResp" BU_SG_REL_ UPA_LS SG_ 2151366656 PrkBrkSwAtv 1;
BA_REL_ "GenSigSuprvResp" BU_SG_REL_ APA_LS SG_ 2151366656 PrkBrkSwAtv 1;
BA_REL_ "GenSigSuprvResp" BU_SG_REL_ APA_LS SG_ 2151366656 PrkBrkSwAtv 1;
BA_REL_ "GenSigSuprvResp" BU_SG_REL_ MSM_LS SG_ 2149842944 AdptDrvrSeatStng 1;
BA_REL_ "GenSigSuprvResp" BU_SG_REL_ VIS2_LS SG_ 2149842944 IMUProtLonAcc 1;
BA_REL_ "GenSigSuprvResp" BU_SG_REL_ UPA_LS SG_ 2149842944 IMUProtLonAcc 1;
BA_REL_ "GenSigSuprvResp" BU_SG_REL_ APA_LS SG_ 2149842944 IMUProtLonAcc 1;
BA_REL_ "GenSigSuprvResp" BU_SG_REL_ APA_LS SG_ 2149842944 IMUProtLonAcc 1;
BA_REL_ "GenSigSuprvResp" BU_SG_REL_ FCM_LS SG_ 2149842944 IMUProtLonAcc 1;
BA_REL_ "GenSigSuprvResp" BU_SG_REL_ FCM_LS SG_ 2149842944 IMUProtLonAcc 1;
BA_REL_ "GenSigSuprvResp" BU_SG_REL_ RadioHead_LS SG_ 2149842944 IMUProtLonAcc 1;
BA_REL_ "GenSigSuprvResp" BU_SG_REL_ IPC_LS SG_ 2149842944 IMUProtLonAcc 1;
BA_REL_ "GenSigSuprvResp" BU_SG_REL_ LCM_LS SG_ 2149842944 IMUProtLonAcc 1;
BA_REL_ "GenSigSuprvResp" BU_SG_REL_ PTM_LS SG_ 2149842944 IMUProtLonAcc 1;
BA_REL_ "GenSigSuprvResp" BU_SG_REL_ IPC_LS SG_ 2149842944 VSELatAcc 1;
BA_REL_ "GenSigSuprvResp" BU_SG_REL_ VIS2_LS SG_ 2149842944 TCSysAtv 1;
BA_REL_ "GenSigSuprvResp" BU_SG_REL_ FCM_LS SG_ 2149842944 TCSysAtv 1;
BA_REL_ "GenSigSuprvResp" BU_SG_REL_ VPM_LS SG_ 2149842944 StrWhlAngSenCalStat 1;
BA_REL_ "GenSigVDAFailComment" BU_SG_REL_ IPC_LS SG_ 2149842944 VehStabEnhmntStat "BrkSysVDA";
BA_REL_ "GenSigVDAFailResp" BU_SG_REL_ IPC_LS SG_ 2149842944 VehStabEnhmntStat 1;
BA_REL_ "GenSigSuprvResp" BU_SG_REL_ IPC_LS SG_ 2149842944 VehStabEnhmntStat 1;
BA_REL_ "GenSigVDAFailComment" BU_SG_REL_ IPC_LS SG_ 2149842944 VehStabEnhmntMd "BrkSysVDA";
BA_REL_ "GenSigVDAFailResp" BU_SG_REL_ IPC_LS SG_ 2149842944 VehStabEnhmntMd 1;
BA_REL_ "GenSigSuprvResp" BU_SG_REL_ IPC_LS SG_ 2149842944 VehStabEnhmntMd 1;
BA_REL_ "GenSigSuprvResp" BU_SG_REL_ EOCM_F_LS SG_ 2149842944 VSEAct 1;
BA_REL_ "GenSigVDAFailComment" BU_SG_REL_ IPC_LS SG_ 2149842944 TCSysOpStat "BrkSysVDA";
BA_REL_ "GenSigVDAFailResp" BU_SG_REL_ IPC_LS SG_ 2149842944 TCSysOpStat 1;
BA_REL_ "GenSigSuprvResp" BU_SG_REL_ IPC_LS SG_ 2149842944 TCSysOpStat 1;
BA_REL_ "GenSigVDAFailComment" BU_SG_REL_ IPC_LS SG_ 2149842944 TCSysOpMd "BrkSysVDA";
BA_REL_ "GenSigVDAFailResp" BU_SG_REL_ IPC_LS SG_ 2149842944 TCSysOpMd 1;
BA_REL_ "GenSigSuprvResp" BU_SG_REL_ IPC_LS SG_ 2149842944 TCSysOpMd 1;
BA_REL_ "GenSigVBitResp" BU_SG_REL_ VIS2_LS SG_ 2149842944 StrWhAng 1;
BA_REL_ "GenSigVBitRespComment" BU_SG_REL_ VIS2_LS SG_ 2149842944 StrWhAng "StrWhAngV";
BA_REL_ "GenSigVDAFailComment" BU_SG_REL_ VIS2_LS SG_ 2149842944 StrWhAng "StWhAnVDA";
BA_REL_ "GenSigVDAFailResp" BU_SG_REL_ VIS2_LS SG_ 2149842944 StrWhAng 1;
BA_REL_ "GenSigSuprvResp" BU_SG_REL_ VIS2_LS SG_ 2149842944 StrWhAng 1;
BA_REL_ "GenSigSuprvResp" BU_SG_REL_ VPM_LS SG_ 2149842944 StrWhAng 1;
BA_REL_ "GenSigVDAFailComment" BU_SG_REL_ CSM_LS SG_ 2149842944 StrWhAng "StWhAnVDA";
BA_REL_ "GenSigVDAFailResp" BU_SG_REL_ CSM_LS SG_ 2149842944 StrWhAng 1;
BA_REL_ "GenSigSuprvResp" BU_SG_REL_ CSM_LS SG_ 2149842944 StrWhAng 1;
BA_REL_ "GenSigVDAFailComment" BU_SG_REL_ RadioHead_LS SG_ 2149842944 StrWhAng "StWhAnVDA";
BA_REL_ "GenSigVDAFailResp" BU_SG_REL_ RadioHead_LS SG_ 2149842944 StrWhAng 1;
BA_REL_ "GenSigSuprvResp" BU_SG_REL_ RadioHead_LS SG_ 2149842944 StrWhAng 1;
BA_REL_ "GenSigVDAFailComment" BU_SG_REL_ RadioHead_LS SG_ 2149842944 StrWhAng "StWhAnVDA";
BA_REL_ "GenSigVDAFailResp" BU_SG_REL_ RadioHead_LS SG_ 2149842944 StrWhAng 1;
BA_REL_ "GenSigSuprvResp" BU_SG_REL_ RadioHead_LS SG_ 2149842944 StrWhAng 1;
BA_REL_ "GenSigVBitResp" BU_SG_REL_ FCM_LS SG_ 2149842944 StrWhAng 1;
BA_REL_ "GenSigVDAFailComment" BU_SG_REL_ FCM_LS SG_ 2149842944 StrWhAng "StWhAnVDA";
BA_REL_ "GenSigVDAFailResp" BU_SG_REL_ FCM_LS SG_ 2149842944 StrWhAng 1;
BA_REL_ "GenSigSuprvResp" BU_SG_REL_ FCM_LS SG_ 2149842944 StrWhAng 1;
BA_REL_ "GenSigVDAFailComment" BU_SG_REL_ UPA_LS SG_ 2149842944 StrWhAng "StWhAnVDA";
BA_REL_ "GenSigVDAFailResp" BU_SG_REL_ UPA_LS SG_ 2149842944 StrWhAng 1;
BA_REL_ "GenSigSuprvResp" BU_SG_REL_ UPA_LS SG_ 2149842944 StrWhAng 1;
BA_REL_ "GenSigVDAFailComment" BU_SG_REL_ APA_LS SG_ 2149842944 StrWhAng "StWhAnVDA";
BA_REL_ "GenSigVDAFailResp" BU_SG_REL_ APA_LS SG_ 2149842944 StrWhAng 1;
BA_REL_ "GenSigSuprvResp" BU_SG_REL_ APA_LS SG_ 2149842944 StrWhAng 1;
BA_REL_ "GenSigVDAFailComment" BU_SG_REL_ APA_LS SG_ 2149842944 StrWhAng "StWhAnVDA";
BA_REL_ "GenSigVDAFailResp" BU_SG_REL_ APA_LS SG_ 2149842944 StrWhAng 1;
BA_REL_ "GenSigSuprvResp" BU_SG_REL_ APA_LS SG_ 2149842944 StrWhAng 1;
BA_REL_ "GenSigSuprvResp" BU_SG_REL_ RadioHead_LS SG_ 2151972864 VehFuelRngCalc 1;
BA_REL_ "GenSigSuprvResp" BU_SG_REL_ VPM_LS SG_ 2154528768 WhlGrndVlctyRtNnDrvn 1;
BA_REL_ "GenSigSuprvResp" BU_SG_REL_ SDM_LS SG_ 2154528768 WhlGrndVlctyRtNnDrvn 1;
BA_REL_ "GenSigVBitResp" BU_SG_REL_ UPA_LS SG_ 2154528768 WhlGrndVlctyRtNnDrvn 1;
BA_REL_ "GenSigVDAFailComment" BU_SG_REL_ UPA_LS SG_ 2154528768 WhlGrndVlctyRtNnDrvn "Brake System Virtual Device Availability";
BA_REL_ "GenSigVDAFailResp" BU_SG_REL_ UPA_LS SG_ 2154528768 WhlGrndVlctyRtNnDrvn 1;
BA_REL_ "GenSigSuprvResp" BU_SG_REL_ UPA_LS SG_ 2154528768 WhlGrndVlctyRtNnDrvn 1;
BA_REL_ "GenSigVBitResp" BU_SG_REL_ APA_LS SG_ 2154528768 WhlGrndVlctyRtNnDrvn 1;
BA_REL_ "GenSigVDAFailComment" BU_SG_REL_ APA_LS SG_ 2154528768 WhlGrndVlctyRtNnDrvn "Brake System Virtual Device Availability";
BA_REL_ "GenSigVDAFailResp" BU_SG_REL_ APA_LS SG_ 2154528768 WhlGrndVlctyRtNnDrvn 1;
BA_REL_ "GenSigSuprvResp" BU_SG_REL_ APA_LS SG_ 2154528768 WhlGrndVlctyRtNnDrvn 1;
BA_REL_ "GenSigVBitResp" BU_SG_REL_ APA_LS SG_ 2154528768 WhlGrndVlctyRtNnDrvn 1;
BA_REL_ "GenSigVDAFailComment" BU_SG_REL_ APA_LS SG_ 2154528768 WhlGrndVlctyRtNnDrvn "Brake System Virtual Device Availability";
BA_REL_ "GenSigVDAFailResp" BU_SG_REL_ APA_LS SG_ 2154528768 WhlGrndVlctyRtNnDrvn 1;
BA_REL_ "GenSigSuprvResp" BU_SG_REL_ APA_LS SG_ 2154528768 WhlGrndVlctyRtNnDrvn 1;
BA_REL_ "GenSigSuprvResp" BU_SG_REL_ VPM_LS SG_ 2154528768 WhlGrndVlctyRtDrvn 1;
BA_REL_ "GenSigSuprvResp" BU_SG_REL_ SDM_LS SG_ 2154528768 WhlGrndVlctyRtDrvn 1;
BA_REL_ "GenSigVBitResp" BU_SG_REL_ UPA_LS SG_ 2154528768 WhlGrndVlctyRtDrvn 1;
BA_REL_ "GenSigVDAFailComment" BU_SG_REL_ UPA_LS SG_ 2154528768 WhlGrndVlctyRtDrvn "Brake System Virtual Device Availability";
BA_REL_ "GenSigVDAFailResp" BU_SG_REL_ UPA_LS SG_ 2154528768 WhlGrndVlctyRtDrvn 1;
BA_REL_ "GenSigSuprvResp" BU_SG_REL_ UPA_LS SG_ 2154528768 WhlGrndVlctyRtDrvn 1;
BA_REL_ "GenSigVBitResp" BU_SG_REL_ APA_LS SG_ 2154528768 WhlGrndVlctyRtDrvn 1;
BA_REL_ "GenSigVDAFailComment" BU_SG_REL_ APA_LS SG_ 2154528768 WhlGrndVlctyRtDrvn "Brake System Virtual Device Availability";
BA_REL_ "GenSigVDAFailResp" BU_SG_REL_ APA_LS SG_ 2154528768 WhlGrndVlctyRtDrvn 1;
BA_REL_ "GenSigSuprvResp" BU_SG_REL_ APA_LS SG_ 2154528768 WhlGrndVlctyRtDrvn 1;
BA_REL_ "GenSigVBitResp" BU_SG_REL_ APA_LS SG_ 2154528768 WhlGrndVlctyRtDrvn 1;
BA_REL_ "GenSigVDAFailComment" BU_SG_REL_ APA_LS SG_ 2154528768 WhlGrndVlctyRtDrvn "Brake System Virtual Device Availability";
BA_REL_ "GenSigVDAFailResp" BU_SG_REL_ APA_LS SG_ 2154528768 WhlGrndVlctyRtDrvn 1;
BA_REL_ "GenSigSuprvResp" BU_SG_REL_ APA_LS SG_ 2154528768 WhlGrndVlctyRtDrvn 1;
BA_REL_ "GenSigSuprvResp" BU_SG_REL_ VPM_LS SG_ 2154528768 WhlGrndVlctyLftNnDrvn 1;
BA_REL_ "GenSigSuprvResp" BU_SG_REL_ SDM_LS SG_ 2154528768 WhlGrndVlctyLftNnDrvn 1;
BA_REL_ "GenSigVBitResp" BU_SG_REL_ UPA_LS SG_ 2154528768 WhlGrndVlctyLftNnDrvn 1;
BA_REL_ "GenSigVDAFailComment" BU_SG_REL_ UPA_LS SG_ 2154528768 WhlGrndVlctyLftNnDrvn "Brake System Virtual Device Availability";
BA_REL_ "GenSigVDAFailResp" BU_SG_REL_ UPA_LS SG_ 2154528768 WhlGrndVlctyLftNnDrvn 1;
BA_REL_ "GenSigSuprvResp" BU_SG_REL_ UPA_LS SG_ 2154528768 WhlGrndVlctyLftNnDrvn 1;
BA_REL_ "GenSigVBitResp" BU_SG_REL_ APA_LS SG_ 2154528768 WhlGrndVlctyLftNnDrvn 1;
BA_REL_ "GenSigVDAFailComment" BU_SG_REL_ APA_LS SG_ 2154528768 WhlGrndVlctyLftNnDrvn "Brake System Virtual Device Availability";
BA_REL_ "GenSigVDAFailResp" BU_SG_REL_ APA_LS SG_ 2154528768 WhlGrndVlctyLftNnDrvn 1;
BA_REL_ "GenSigSuprvResp" BU_SG_REL_ APA_LS SG_ 2154528768 WhlGrndVlctyLftNnDrvn 1;
BA_REL_ "GenSigVBitResp" BU_SG_REL_ APA_LS SG_ 2154528768 WhlGrndVlctyLftNnDrvn 1;
BA_REL_ "GenSigVDAFailComment" BU_SG_REL_ APA_LS SG_ 2154528768 WhlGrndVlctyLftNnDrvn "Brake System Virtual Device Availability";
BA_REL_ "GenSigVDAFailResp" BU_SG_REL_ APA_LS SG_ 2154528768 WhlGrndVlctyLftNnDrvn 1;
BA_REL_ "GenSigSuprvResp" BU_SG_REL_ APA_LS SG_ 2154528768 WhlGrndVlctyLftNnDrvn 1;
BA_REL_ "GenSigSuprvResp" BU_SG_REL_ VPM_LS SG_ 2154528768 WhlGrndVlctyLftDrvn 1;
BA_REL_ "GenSigSuprvResp" BU_SG_REL_ SDM_LS SG_ 2154528768 WhlGrndVlctyLftDrvn 1;
BA_REL_ "GenSigVBitResp" BU_SG_REL_ UPA_LS SG_ 2154528768 WhlGrndVlctyLftDrvn 1;
BA_REL_ "GenSigVDAFailComment" BU_SG_REL_ UPA_LS SG_ 2154528768 WhlGrndVlctyLftDrvn "Brake System Virtual Device Availability";
BA_REL_ "GenSigVDAFailResp" BU_SG_REL_ UPA_LS SG_ 2154528768 WhlGrndVlctyLftDrvn 1;
BA_REL_ "GenSigSuprvResp" BU_SG_REL_ UPA_LS SG_ 2154528768 WhlGrndVlctyLftDrvn 1;
BA_REL_ "GenSigVBitResp" BU_SG_REL_ APA_LS SG_ 2154528768 WhlGrndVlctyLftDrvn 1;
BA_REL_ "GenSigVDAFailComment" BU_SG_REL_ APA_LS SG_ 2154528768 WhlGrndVlctyLftDrvn "Brake System Virtual Device Availability";
BA_REL_ "GenSigVDAFailResp" BU_SG_REL_ APA_LS SG_ 2154528768 WhlGrndVlctyLftDrvn 1;
BA_REL_ "GenSigSuprvResp" BU_SG_REL_ APA_LS SG_ 2154528768 WhlGrndVlctyLftDrvn 1;
BA_REL_ "GenSigVBitResp" BU_SG_REL_ APA_LS SG_ 2154528768 WhlGrndVlctyLftDrvn 1;
BA_REL_ "GenSigVDAFailComment" BU_SG_REL_ APA_LS SG_ 2154528768 WhlGrndVlctyLftDrvn "Brake System Virtual Device Availability";
BA_REL_ "GenSigSuprvResp" BU_SG_REL_ APA_LS SG_ 2154528768 WhlGrndVlctyLftDrvn 1;
BA_REL_ "GenSigSuprvResp" BU_SG_REL_ SDM_LS SG_ 2150367232 LrnEnvIdSt 1;
BA_REL_ "GenSigSuprvResp" BU_SG_REL_ SDM_LS SG_ 2150367232 LrnEnvId 1;
BA_REL_ "GenSigSuprvResp" BU_SG_REL_ V2V_LS SG_ 2150367232 ImoId 1;
BA_REL_ "GenSigSuprvResp" BU_SG_REL_ SDM_LS SG_ 2150367232 ImoId 1;
BA_REL_ "GenSigSuprvResp" BU_SG_REL_ SDM_LS SG_ 2150367232 ImoIdSt 1;
BA_REL_ "GenSigSuprvResp" BU_SG_REL_ SDM_LS SG_ 2151309312 InflRestId 1;
BA_REL_ "GenSigSuprvResp" BU_SG_REL_ STC_LS SG_ 2154061824 WndOprAlwd 1;
BA_REL_ "GenSigSuprvResp" BU_SG_REL_ CSM_LS SG_ 2155347968 DrvrStPerfMdCsCrStVal 1;
BA_REL_ "GenSigSuprvResp" BU_SG_REL_ RadioHead_LS SG_ 2155347968 DrvrStPerfMdCsCrStVal 1;
BA_REL_ "GenSigSuprvResp" BU_SG_REL_ CSM_LS SG_ 2155347968 DrvrStPerfMdCsStAvl 1;
BA_REL_ "GenSigSuprvResp" BU_SG_REL_ RadioHead_LS SG_ 2155347968 DrvrStPerfMdCsStAvl 1;
BA_REL_ "GenSigSuprvResp" BU_SG_REL_ CSM_LS SG_ 2155347968 ACCPerfMdCsCrStVal 1;
BA_REL_ "GenSigSuprvResp" BU_SG_REL_ RadioHead_LS SG_ 2155347968 ACCPerfMdCsCrStVal 1;
BA_REL_ "GenSigSuprvResp" BU_SG_REL_ CSM_LS SG_ 2155347968 ACCPerfMdCsStAvl 1;
BA_REL_ "GenSigSuprvResp" BU_SG_REL_ RadioHead_LS SG_ 2155347968 ACCPerfMdCsStAvl 1;
BA_REL_ "GenSigSuprvResp" BU_SG_REL_ IPC_LS SG_ 2155347968 ActVbnCtrlMlfIO 1;
BA_REL_ "GenSigSuprvResp" BU_SG_REL_ IPC_LS SG_ 2155347968 HillDesCtrlRedVehSpIO 1;
BA_REL_ "GenSigSuprvResp" BU_SG_REL_ IPC_LS SG_ 2155347968 FourWhlDrvIndReq 1;
BA_REL_ "GenSigVDAFailComment" BU_SG_REL_ IPC_LS SG_ 2155347968 PedtrnProtSysDisbld "Pedestrian Protection Virtual Device Availability";
BA_REL_ "GenSigVDAFailResp" BU_SG_REL_ IPC_LS SG_ 2155347968 PedtrnProtSysDisbld 1;
BA_REL_ "GenSigSuprvResp" BU_SG_REL_ IPC_LS SG_ 2155347968 PedtrnProtSysDisbld 1;
BA_REL_ "GenSigVDAFailComment" BU_SG_REL_ IPC_LS SG_ 2155347968 PedtrnProtSysDpl "Pedestrian Protection Virtual Device Availability";
BA_REL_ "GenSigVDAFailResp" BU_SG_REL_ IPC_LS SG_ 2155347968 PedtrnProtSysDpl 1;
BA_REL_ "GenSigSuprvResp" BU_SG_REL_ IPC_LS SG_ 2155347968 PedtrnProtSysDpl 1;
BA_REL_ "GenSigVDAFailComment" BU_SG_REL_ IPC_LS SG_ 2155347968 SrvPedtrnProtSysIO "Pedestrian Protection Virtual Device Availability";
BA_REL_ "GenSigVDAFailResp" BU_SG_REL_ IPC_LS SG_ 2155347968 SrvPedtrnProtSysIO 1;
BA_REL_ "GenSigSuprvResp" BU_SG_REL_ IPC_LS SG_ 2155347968 SrvPedtrnProtSysIO 1;
BA_REL_ "GenSigSuprvResp" BU_SG_REL_ FCM_LS SG_ 2155347968 CPSAlrtOnlIO 1;
BA_REL_ "GenSigVDAFailComment" BU_SG_REL_ IPC_LS SG_ 2155347968 EPBSysStatIndReq "PrkBrkVDA";
BA_REL_ "GenSigVDAFailResp" BU_SG_REL_ IPC_LS SG_ 2155347968 EPBSysStatIndReq 1;
BA_REL_ "GenSigSuprvResp" BU_SG_REL_ IPC_LS SG_ 2155347968 EPBSysStatIndReq 1;
BA_REL_ "GenSigSuprvResp" BU_SG_REL_ VIS2_LS SG_ 2155347968 BrkSysMalFuncIndOn 1;
BA_REL_ "GenSigSuprvResp" BU_SG_REL_ FCM_LS SG_ 2155347968 BrkSysMalFuncIndOn 1;
BA_REL_ "GenSigVDAFailComment" BU_SG_REL_ IPC_LS SG_ 2155347968 SecAxlNonEmMalfIO "Secondary Axle Virtual Device Availability";
BA_REL_ "GenSigVDAFailResp" BU_SG_REL_ IPC_LS SG_ 2155347968 SecAxlNonEmMalfIO 1;
BA_REL_ "GenSigSuprvResp" BU_SG_REL_ IPC_LS SG_ 2155347968 SecAxlNonEmMalfIO 1;
BA_REL_ "GenSigRxStartValue" BU_SG_REL_ IPC_LS SG_ 2155347968 EngEmsRelMalfIndReq "$0 - Continuous Indication";
BA_REL_ "GenSigVDAFailComment" BU_SG_REL_ IPC_LS SG_ 2155347968 EPBSysWrnIndReq "PrkBrkVDA";
BA_REL_ "GenSigVDAFailResp" BU_SG_REL_ IPC_LS SG_ 2155347968 EPBSysWrnIndReq 1;
BA_REL_ "GenSigSuprvResp" BU_SG_REL_ IPC_LS SG_ 2155347968 EPBSysWrnIndReq 1;
BA_REL_ "GenSigSuprvResp" BU_SG_REL_ VPM_LS SG_ 2149777408 WRSLNDWhlDisTpRC 1;
BA_REL_ "GenSigSuprvResp" BU_SG_REL_ UPA_LS SG_ 2149777408 WRSLNDWhlDisTpRC 1;
BA_REL_ "GenSigSuprvResp" BU_SG_REL_ APA_LS SG_ 2149777408 WRSLNDWhlDisTpRC 1;
BA_REL_ "GenSigSuprvResp" BU_SG_REL_ APA_LS SG_ 2149777408 WRSLNDWhlDisTpRC 1;
BA_REL_ "GenSigSuprvResp" BU_SG_REL_ VPM_LS SG_ 2149777408 WRSLNDWhlRotStRst 1;
BA_REL_ "GenSigVDAFailComment" BU_SG_REL_ UPA_LS SG_ 2149777408 WRSLNDWhlRotStRst "BrkSysVDA";
BA_REL_ "GenSigVDAFailResp" BU_SG_REL_ UPA_LS SG_ 2149777408 WRSLNDWhlRotStRst 1;
BA_REL_ "GenSigSuprvResp" BU_SG_REL_ UPA_LS SG_ 2149777408 WRSLNDWhlRotStRst 1;
BA_REL_ "GenSigVDAFailComment" BU_SG_REL_ APA_LS SG_ 2149777408 WRSLNDWhlRotStRst "BrkSysVDA";
BA_REL_ "GenSigVDAFailResp" BU_SG_REL_ APA_LS SG_ 2149777408 WRSLNDWhlRotStRst 1;
BA_REL_ "GenSigVDAFailComment" BU_SG_REL_ APA_LS SG_ 2149777408 WRSLNDWhlRotStRst "BrkSysVDA";
BA_REL_ "GenSigVDAFailResp" BU_SG_REL_ APA_LS SG_ 2149777408 WRSLNDWhlRotStRst 1;
BA_REL_ "GenSigSuprvResp" BU_SG_REL_ APA_LS SG_ 2149777408 WRSLNDWhlRotStRst 1;
BA_REL_ "GenSigSuprvResp" BU_SG_REL_ APA_LS SG_ 2149777408 WRSLNDWhlRotStRst 1;
BA_REL_ "GenSigSuprvResp" BU_SG_REL_ VPM_LS SG_ 2149777408 WRSLNDWhlDistVal 1;
BA_REL_ "GenSigVDAFailComment" BU_SG_REL_ UPA_LS SG_ 2149777408 WRSLNDWhlDistVal "BrkSysVDA";
BA_REL_ "GenSigVDAFailResp" BU_SG_REL_ UPA_LS SG_ 2149777408 WRSLNDWhlDistVal 1;
BA_REL_ "GenSigSuprvResp" BU_SG_REL_ UPA_LS SG_ 2149777408 WRSLNDWhlDistVal 1;
BA_REL_ "GenSigVDAFailComment" BU_SG_REL_ APA_LS SG_ 2149777408 WRSLNDWhlDistVal "BrkSysVDA";
BA_REL_ "GenSigVDAFailResp" BU_SG_REL_ APA_LS SG_ 2149777408 WRSLNDWhlDistVal 1;
BA_REL_ "GenSigVDAFailComment" BU_SG_REL_ APA_LS SG_ 2149777408 WRSLNDWhlDistVal "BrkSysVDA";
BA_REL_ "GenSigVDAFailResp" BU_SG_REL_ APA_LS SG_ 2149777408 WRSLNDWhlDistVal 1;
BA_REL_ "GenSigSuprvResp" BU_SG_REL_ APA_LS SG_ 2149777408 WRSLNDWhlDistVal 1;
BA_REL_ "GenSigSuprvResp" BU_SG_REL_ APA_LS SG_ 2149777408 WRSLNDWhlDistVal 1;
BA_REL_ "GenSigSuprvResp" BU_SG_REL_ VPM_LS SG_ 2149777408 WRSLNDWhlDistTstm 1;
BA_REL_ "GenSigVDAFailComment" BU_SG_REL_ UPA_LS SG_ 2149777408 WRSLNDWhlDistTstm "BrkSysVDA";
BA_REL_ "GenSigVDAFailResp" BU_SG_REL_ UPA_LS SG_ 2149777408 WRSLNDWhlDistTstm 1;
BA_REL_ "GenSigSuprvResp" BU_SG_REL_ UPA_LS SG_ 2149777408 WRSLNDWhlDistTstm 1;
BA_REL_ "GenSigVDAFailComment" BU_SG_REL_ APA_LS SG_ 2149777408 WRSLNDWhlDistTstm "BrkSysVDA";
BA_REL_ "GenSigVDAFailResp" BU_SG_REL_ APA_LS SG_ 2149777408 WRSLNDWhlDistTstm 1;
BA_REL_ "GenSigVDAFailComment" BU_SG_REL_ APA_LS SG_ 2149777408 WRSLNDWhlDistTstm "BrkSysVDA";
BA_REL_ "GenSigVDAFailResp" BU_SG_REL_ APA_LS SG_ 2149777408 WRSLNDWhlDistTstm 1;
BA_REL_ "GenSigSuprvResp" BU_SG_REL_ APA_LS SG_ 2149777408 WRSLNDWhlDistTstm 1;
BA_REL_ "GenSigSuprvResp" BU_SG_REL_ APA_LS SG_ 2149777408 WRSLNDWhlDistTstm 1;
BA_REL_ "GenSigSuprvResp" BU_SG_REL_ VPM_LS SG_ 2149777408 WRSLNDWhlDistPCntr 1;
BA_REL_ "GenSigVDAFailComment" BU_SG_REL_ UPA_LS SG_ 2149777408 WRSLNDWhlDistPCntr "BrkSysVDA";
BA_REL_ "GenSigVDAFailResp" BU_SG_REL_ UPA_LS SG_ 2149777408 WRSLNDWhlDistPCntr 1;
BA_REL_ "GenSigSuprvResp" BU_SG_REL_ UPA_LS SG_ 2149777408 WRSLNDWhlDistPCntr 1;
BA_REL_ "GenSigVDAFailComment" BU_SG_REL_ APA_LS SG_ 2149777408 WRSLNDWhlDistPCntr "BrkSysVDA";
BA_REL_ "GenSigVDAFailResp" BU_SG_REL_ APA_LS SG_ 2149777408 WRSLNDWhlDistPCntr 1;
BA_REL_ "GenSigVDAFailComment" BU_SG_REL_ APA_LS SG_ 2149777408 WRSLNDWhlDistPCntr "BrkSysVDA";
BA_REL_ "GenSigVDAFailResp" BU_SG_REL_ APA_LS SG_ 2149777408 WRSLNDWhlDistPCntr 1;
BA_REL_ "GenSigSuprvResp" BU_SG_REL_ APA_LS SG_ 2149777408 WRSLNDWhlDistPCntr 1;
BA_REL_ "GenSigSuprvResp" BU_SG_REL_ APA_LS SG_ 2149777408 WRSLNDWhlDistPCntr 1;
BA_REL_ "GenSigSuprvResp" BU_SG_REL_ VPM_LS SG_ 2149777408 WRSLNDSeqNum 1;
BA_REL_ "GenSigVDAFailComment" BU_SG_REL_ UPA_LS SG_ 2149777408 WRSLNDSeqNum "BrkSysVDA";
BA_REL_ "GenSigVDAFailResp" BU_SG_REL_ UPA_LS SG_ 2149777408 WRSLNDSeqNum 1;
BA_REL_ "GenSigSuprvResp" BU_SG_REL_ UPA_LS SG_ 2149777408 WRSLNDSeqNum 1;
BA_REL_ "GenSigVDAFailComment" BU_SG_REL_ APA_LS SG_ 2149777408 WRSLNDSeqNum "BrkSysVDA";
BA_REL_ "GenSigVDAFailResp" BU_SG_REL_ APA_LS SG_ 2149777408 WRSLNDSeqNum 1;
BA_REL_ "GenSigVDAFailComment" BU_SG_REL_ APA_LS SG_ 2149777408 WRSLNDSeqNum "BrkSysVDA";
BA_REL_ "GenSigVDAFailResp" BU_SG_REL_ APA_LS SG_ 2149777408 WRSLNDSeqNum 1;
BA_REL_ "GenSigSuprvResp" BU_SG_REL_ APA_LS SG_ 2149777408 WRSLNDSeqNum 1;
BA_REL_ "GenSigSuprvResp" BU_SG_REL_ APA_LS SG_ 2149777408 WRSLNDSeqNum 1;
BA_REL_ "GenSigSuprvResp" BU_SG_REL_ VPM_LS SG_ 2149777408 WRSRNDWhlDisTpRC 1;
BA_REL_ "GenSigSuprvResp" BU_SG_REL_ UPA_LS SG_ 2149777408 WRSRNDWhlDisTpRC 1;
BA_REL_ "GenSigSuprvResp" BU_SG_REL_ APA_LS SG_ 2149777408 WRSRNDWhlDisTpRC 1;
BA_REL_ "GenSigSuprvResp" BU_SG_REL_ APA_LS SG_ 2149777408 WRSRNDWhlDisTpRC 1;
BA_REL_ "GenSigSuprvResp" BU_SG_REL_ VPM_LS SG_ 2149777408 WRSRNDWhlRotStRst 1;
BA_REL_ "GenSigVDAFailComment" BU_SG_REL_ UPA_LS SG_ 2149777408 WRSRNDWhlRotStRst "BrkSysVDA";
BA_REL_ "GenSigVDAFailResp" BU_SG_REL_ UPA_LS SG_ 2149777408 WRSRNDWhlRotStRst 1;
BA_REL_ "GenSigSuprvResp" BU_SG_REL_ UPA_LS SG_ 2149777408 WRSRNDWhlRotStRst 1;
BA_REL_ "GenSigVDAFailComment" BU_SG_REL_ APA_LS SG_ 2149777408 WRSRNDWhlRotStRst "BrkSysVDA";
BA_REL_ "GenSigVDAFailResp" BU_SG_REL_ APA_LS SG_ 2149777408 WRSRNDWhlRotStRst 1;
BA_REL_ "GenSigVDAFailComment" BU_SG_REL_ APA_LS SG_ 2149777408 WRSRNDWhlRotStRst "BrkSysVDA";
BA_REL_ "GenSigVDAFailResp" BU_SG_REL_ APA_LS SG_ 2149777408 WRSRNDWhlRotStRst 1;
BA_REL_ "GenSigSuprvResp" BU_SG_REL_ APA_LS SG_ 2149777408 WRSRNDWhlRotStRst 1;
BA_REL_ "GenSigSuprvResp" BU_SG_REL_ APA_LS SG_ 2149777408 WRSRNDWhlRotStRst 1;
BA_REL_ "GenSigSuprvResp" BU_SG_REL_ VPM_LS SG_ 2149777408 WRSRNDWhlDistVal 1;
BA_REL_ "GenSigVDAFailComment" BU_SG_REL_ UPA_LS SG_ 2149777408 WRSRNDWhlDistVal "BrkSysVDA";
BA_REL_ "GenSigVDAFailResp" BU_SG_REL_ UPA_LS SG_ 2149777408 WRSRNDWhlDistVal 1;
BA_REL_ "GenSigSuprvResp" BU_SG_REL_ UPA_LS SG_ 2149777408 WRSRNDWhlDistVal 1;
BA_REL_ "GenSigVDAFailComment" BU_SG_REL_ APA_LS SG_ 2149777408 WRSRNDWhlDistVal "BrkSysVDA";
BA_REL_ "GenSigVDAFailResp" BU_SG_REL_ APA_LS SG_ 2149777408 WRSRNDWhlDistVal 1;
BA_REL_ "GenSigVDAFailComment" BU_SG_REL_ APA_LS SG_ 2149777408 WRSRNDWhlDistVal "BrkSysVDA";
BA_REL_ "GenSigVDAFailResp" BU_SG_REL_ APA_LS SG_ 2149777408 WRSRNDWhlDistVal 1;
BA_REL_ "GenSigSuprvResp" BU_SG_REL_ APA_LS SG_ 2149777408 WRSRNDWhlDistVal 1;
BA_REL_ "GenSigSuprvResp" BU_SG_REL_ APA_LS SG_ 2149777408 WRSRNDWhlDistVal 1;
BA_REL_ "GenSigSuprvResp" BU_SG_REL_ VPM_LS SG_ 2149777408 WRSRNDWhlDistTstm 1;
BA_REL_ "GenSigVDAFailComment" BU_SG_REL_ UPA_LS SG_ 2149777408 WRSRNDWhlDistTstm "BrkSysVDA";
BA_REL_ "GenSigVDAFailResp" BU_SG_REL_ UPA_LS SG_ 2149777408 WRSRNDWhlDistTstm 1;
BA_REL_ "GenSigSuprvResp" BU_SG_REL_ UPA_LS SG_ 2149777408 WRSRNDWhlDistTstm 1;
BA_REL_ "GenSigVDAFailComment" BU_SG_REL_ APA_LS SG_ 2149777408 WRSRNDWhlDistTstm "BrkSysVDA";
BA_REL_ "GenSigVDAFailResp" BU_SG_REL_ APA_LS SG_ 2149777408 WRSRNDWhlDistTstm 1;
BA_REL_ "GenSigVDAFailComment" BU_SG_REL_ APA_LS SG_ 2149777408 WRSRNDWhlDistTstm "BrkSysVDA";
BA_REL_ "GenSigVDAFailResp" BU_SG_REL_ APA_LS SG_ 2149777408 WRSRNDWhlDistTstm 1;
BA_REL_ "GenSigSuprvResp" BU_SG_REL_ APA_LS SG_ 2149777408 WRSRNDWhlDistTstm 1;
BA_REL_ "GenSigSuprvResp" BU_SG_REL_ APA_LS SG_ 2149777408 WRSRNDWhlDistTstm 1;
BA_REL_ "GenSigSuprvResp" BU_SG_REL_ VPM_LS SG_ 2149777408 WRSRNDWhlDistPCntr 1;
BA_REL_ "GenSigVDAFailComment" BU_SG_REL_ UPA_LS SG_ 2149777408 WRSRNDWhlDistPCntr "BrkSysVDA";
BA_REL_ "GenSigVDAFailResp" BU_SG_REL_ UPA_LS SG_ 2149777408 WRSRNDWhlDistPCntr 1;
BA_REL_ "GenSigSuprvResp" BU_SG_REL_ UPA_LS SG_ 2149777408 WRSRNDWhlDistPCntr 1;
BA_REL_ "GenSigVDAFailComment" BU_SG_REL_ APA_LS SG_ 2149777408 WRSRNDWhlDistPCntr "BrkSysVDA";
BA_REL_ "GenSigVDAFailResp" BU_SG_REL_ APA_LS SG_ 2149777408 WRSRNDWhlDistPCntr 1;
BA_REL_ "GenSigVDAFailComment" BU_SG_REL_ APA_LS SG_ 2149777408 WRSRNDWhlDistPCntr "BrkSysVDA";
BA_REL_ "GenSigVDAFailResp" BU_SG_REL_ APA_LS SG_ 2149777408 WRSRNDWhlDistPCntr 1;
BA_REL_ "GenSigSuprvResp" BU_SG_REL_ APA_LS SG_ 2149777408 WRSRNDWhlDistPCntr 1;
BA_REL_ "GenSigSuprvResp" BU_SG_REL_ APA_LS SG_ 2149777408 WRSRNDWhlDistPCntr 1;
BA_REL_ "GenSigSuprvResp" BU_SG_REL_ VPM_LS SG_ 2149777408 WRSRNDSeqNum 1;
BA_REL_ "GenSigVDAFailComment" BU_SG_REL_ UPA_LS SG_ 2149777408 WRSRNDSeqNum "BrkSysVDA";
BA_REL_ "GenSigVDAFailResp" BU_SG_REL_ UPA_LS SG_ 2149777408 WRSRNDSeqNum 1;
BA_REL_ "GenSigSuprvResp" BU_SG_REL_ UPA_LS SG_ 2149777408 WRSRNDSeqNum 1;
BA_REL_ "GenSigVDAFailComment" BU_SG_REL_ APA_LS SG_ 2149777408 WRSRNDSeqNum "BrkSysVDA";
BA_REL_ "GenSigVDAFailResp" BU_SG_REL_ APA_LS SG_ 2149777408 WRSRNDSeqNum 1;
BA_REL_ "GenSigVDAFailComment" BU_SG_REL_ APA_LS SG_ 2149777408 WRSRNDSeqNum "BrkSysVDA";
BA_REL_ "GenSigVDAFailResp" BU_SG_REL_ APA_LS SG_ 2149777408 WRSRNDSeqNum 1;
BA_REL_ "GenSigSuprvResp" BU_SG_REL_ APA_LS SG_ 2149777408 WRSRNDSeqNum 1;
BA_REL_ "GenSigSuprvResp" BU_SG_REL_ APA_LS SG_ 2149777408 WRSRNDSeqNum 1;
BA_REL_ "GenSigSuprvResp" BU_SG_REL_ UPA_LS SG_ 2149769216 WRSLDWhlDisTpRC 1;
BA_REL_ "GenSigSuprvResp" BU_SG_REL_ APA_LS SG_ 2149769216 WRSLDWhlDisTpRC 1;
BA_REL_ "GenSigSuprvResp" BU_SG_REL_ APA_LS SG_ 2149769216 WRSLDWhlDisTpRC 1;
BA_REL_ "GenSigVDAFailComment" BU_SG_REL_ UPA_LS SG_ 2149769216 WRSLDSeqNum "BrkSysVDA";
BA_REL_ "GenSigVDAFailResp" BU_SG_REL_ UPA_LS SG_ 2149769216 WRSLDSeqNum 1;
BA_REL_ "GenSigSuprvResp" BU_SG_REL_ UPA_LS SG_ 2149769216 WRSLDSeqNum 1;
BA_REL_ "GenSigVDAFailComment" BU_SG_REL_ APA_LS SG_ 2149769216 WRSLDSeqNum "BrkSysVDA";
BA_REL_ "GenSigVDAFailResp" BU_SG_REL_ APA_LS SG_ 2149769216 WRSLDSeqNum 1;
BA_REL_ "GenSigVDAFailComment" BU_SG_REL_ APA_LS SG_ 2149769216 WRSLDSeqNum "BrkSysVDA";
BA_REL_ "GenSigVDAFailResp" BU_SG_REL_ APA_LS SG_ 2149769216 WRSLDSeqNum 1;
BA_REL_ "GenSigSuprvResp" BU_SG_REL_ APA_LS SG_ 2149769216 WRSLDSeqNum 1;
BA_REL_ "GenSigSuprvResp" BU_SG_REL_ APA_LS SG_ 2149769216 WRSLDSeqNum 1;
BA_REL_ "GenSigVDAFailComment" BU_SG_REL_ UPA_LS SG_ 2149769216 WRSLDWhlDistVal "BrkSysVDA";
BA_REL_ "GenSigVDAFailResp" BU_SG_REL_ UPA_LS SG_ 2149769216 WRSLDWhlDistVal 1;
BA_REL_ "GenSigSuprvResp" BU_SG_REL_ UPA_LS SG_ 2149769216 WRSLDWhlDistVal 1;
BA_REL_ "GenSigVDAFailComment" BU_SG_REL_ APA_LS SG_ 2149769216 WRSLDWhlDistVal "BrkSysVDA";
BA_REL_ "GenSigVDAFailResp" BU_SG_REL_ APA_LS SG_ 2149769216 WRSLDWhlDistVal 1;
BA_REL_ "GenSigVDAFailComment" BU_SG_REL_ APA_LS SG_ 2149769216 WRSLDWhlDistVal "BrkSysVDA";
BA_REL_ "GenSigVDAFailResp" BU_SG_REL_ APA_LS SG_ 2149769216 WRSLDWhlDistVal 1;
BA_REL_ "GenSigSuprvResp" BU_SG_REL_ APA_LS SG_ 2149769216 WRSLDWhlDistVal 1;
BA_REL_ "GenSigSuprvResp" BU_SG_REL_ APA_LS SG_ 2149769216 WRSLDWhlDistVal 1;
BA_REL_ "GenSigVDAFailComment" BU_SG_REL_ UPA_LS SG_ 2149769216 WRSLDWhlRotStatRst "BrkSysVDA";
BA_REL_ "GenSigVDAFailResp" BU_SG_REL_ UPA_LS SG_ 2149769216 WRSLDWhlRotStatRst 1;
BA_REL_ "GenSigSuprvResp" BU_SG_REL_ UPA_LS SG_ 2149769216 WRSLDWhlRotStatRst 1;
BA_REL_ "GenSigVDAFailComment" BU_SG_REL_ APA_LS SG_ 2149769216 WRSLDWhlRotStatRst "BrkSysVDA";
BA_REL_ "GenSigVDAFailResp" BU_SG_REL_ APA_LS SG_ 2149769216 WRSLDWhlRotStatRst 1;
BA_REL_ "GenSigVDAFailComment" BU_SG_REL_ APA_LS SG_ 2149769216 WRSLDWhlRotStatRst "BrkSysVDA";
BA_REL_ "GenSigVDAFailResp" BU_SG_REL_ APA_LS SG_ 2149769216 WRSLDWhlRotStatRst 1;
BA_REL_ "GenSigSuprvResp" BU_SG_REL_ APA_LS SG_ 2149769216 WRSLDWhlRotStatRst 1;
BA_REL_ "GenSigSuprvResp" BU_SG_REL_ APA_LS SG_ 2149769216 WRSLDWhlRotStatRst 1;
BA_REL_ "GenSigVDAFailComment" BU_SG_REL_ UPA_LS SG_ 2149769216 WRSLDWhlDistTmstm "BrkSysVDA";
BA_REL_ "GenSigVDAFailResp" BU_SG_REL_ UPA_LS SG_ 2149769216 WRSLDWhlDistTmstm 1;
BA_REL_ "GenSigSuprvResp" BU_SG_REL_ UPA_LS SG_ 2149769216 WRSLDWhlDistTmstm 1;
BA_REL_ "GenSigVDAFailComment" BU_SG_REL_ APA_LS SG_ 2149769216 WRSLDWhlDistTmstm "BrkSysVDA";
BA_REL_ "GenSigVDAFailResp" BU_SG_REL_ APA_LS SG_ 2149769216 WRSLDWhlDistTmstm 1;
BA_REL_ "GenSigVDAFailComment" BU_SG_REL_ APA_LS SG_ 2149769216 WRSLDWhlDistTmstm "BrkSysVDA";
BA_REL_ "GenSigVDAFailResp" BU_SG_REL_ APA_LS SG_ 2149769216 WRSLDWhlDistTmstm 1;
BA_REL_ "GenSigSuprvResp" BU_SG_REL_ APA_LS SG_ 2149769216 WRSLDWhlDistTmstm 1;
BA_REL_ "GenSigSuprvResp" BU_SG_REL_ APA_LS SG_ 2149769216 WRSLDWhlDistTmstm 1;
BA_REL_ "GenSigVDAFailComment" BU_SG_REL_ UPA_LS SG_ 2149769216 WRSLDWhlDistPlsCntr "BrkSysVDA";
BA_REL_ "GenSigVDAFailResp" BU_SG_REL_ UPA_LS SG_ 2149769216 WRSLDWhlDistPlsCntr 1;
BA_REL_ "GenSigSuprvResp" BU_SG_REL_ UPA_LS SG_ 2149769216 WRSLDWhlDistPlsCntr 1;
BA_REL_ "GenSigVDAFailComment" BU_SG_REL_ APA_LS SG_ 2149769216 WRSLDWhlDistPlsCntr "BrkSysVDA";
BA_REL_ "GenSigVDAFailResp" BU_SG_REL_ APA_LS SG_ 2149769216 WRSLDWhlDistPlsCntr 1;
BA_REL_ "GenSigVDAFailComment" BU_SG_REL_ APA_LS SG_ 2149769216 WRSLDWhlDistPlsCntr "BrkSysVDA";
BA_REL_ "GenSigVDAFailResp" BU_SG_REL_ APA_LS SG_ 2149769216 WRSLDWhlDistPlsCntr 1;
BA_REL_ "GenSigSuprvResp" BU_SG_REL_ APA_LS SG_ 2149769216 WRSLDWhlDistPlsCntr 1;
BA_REL_ "GenSigSuprvResp" BU_SG_REL_ APA_LS SG_ 2149769216 WRSLDWhlDistPlsCntr 1;
BA_REL_ "GenSigSuprvResp" BU_SG_REL_ UPA_LS SG_ 2149769216 WRSRDWhlDisTpRC 1;
BA_REL_ "GenSigSuprvResp" BU_SG_REL_ APA_LS SG_ 2149769216 WRSRDWhlDisTpRC 1;
BA_REL_ "GenSigSuprvResp" BU_SG_REL_ APA_LS SG_ 2149769216 WRSRDWhlDisTpRC 1;
BA_REL_ "GenSigVDAFailComment" BU_SG_REL_ UPA_LS SG_ 2149769216 WRSRDSeqNum "BrkSysVDA";
BA_REL_ "GenSigVDAFailResp" BU_SG_REL_ UPA_LS SG_ 2149769216 WRSRDSeqNum 1;
BA_REL_ "GenSigSuprvResp" BU_SG_REL_ UPA_LS SG_ 2149769216 WRSRDSeqNum 1;
BA_REL_ "GenSigVDAFailComment" BU_SG_REL_ APA_LS SG_ 2149769216 WRSRDSeqNum "BrkSysVDA";
BA_REL_ "GenSigVDAFailResp" BU_SG_REL_ APA_LS SG_ 2149769216 WRSRDSeqNum 1;
BA_REL_ "GenSigVDAFailComment" BU_SG_REL_ APA_LS SG_ 2149769216 WRSRDSeqNum "BrkSysVDA";
BA_REL_ "GenSigVDAFailResp" BU_SG_REL_ APA_LS SG_ 2149769216 WRSRDSeqNum 1;
BA_REL_ "GenSigSuprvResp" BU_SG_REL_ APA_LS SG_ 2149769216 WRSRDSeqNum 1;
BA_REL_ "GenSigSuprvResp" BU_SG_REL_ APA_LS SG_ 2149769216 WRSRDSeqNum 1;
BA_REL_ "GenSigVDAFailComment" BU_SG_REL_ UPA_LS SG_ 2149769216 WRSRDWhlRotStatRst "BrkSysVDA";
BA_REL_ "GenSigVDAFailResp" BU_SG_REL_ UPA_LS SG_ 2149769216 WRSRDWhlRotStatRst 1;
BA_REL_ "GenSigSuprvResp" BU_SG_REL_ UPA_LS SG_ 2149769216 WRSRDWhlRotStatRst 1;
BA_REL_ "GenSigVDAFailComment" BU_SG_REL_ APA_LS SG_ 2149769216 WRSRDWhlRotStatRst "BrkSysVDA";
BA_REL_ "GenSigVDAFailResp" BU_SG_REL_ APA_LS SG_ 2149769216 WRSRDWhlRotStatRst 1;
BA_REL_ "GenSigVDAFailComment" BU_SG_REL_ APA_LS SG_ 2149769216 WRSRDWhlRotStatRst "BrkSysVDA";
BA_REL_ "GenSigVDAFailResp" BU_SG_REL_ APA_LS SG_ 2149769216 WRSRDWhlRotStatRst 1;
BA_REL_ "GenSigSuprvResp" BU_SG_REL_ APA_LS SG_ 2149769216 WRSRDWhlRotStatRst 1;
BA_REL_ "GenSigSuprvResp" BU_SG_REL_ APA_LS SG_ 2149769216 WRSRDWhlRotStatRst 1;
BA_REL_ "GenSigVDAFailComment" BU_SG_REL_ UPA_LS SG_ 2149769216 WRSRDWhlDistVal "BrkSysVDA";
BA_REL_ "GenSigVDAFailResp" BU_SG_REL_ UPA_LS SG_ 2149769216 WRSRDWhlDistVal 1;
BA_REL_ "GenSigSuprvResp" BU_SG_REL_ UPA_LS SG_ 2149769216 WRSRDWhlDistVal 1;
BA_REL_ "GenSigVDAFailComment" BU_SG_REL_ APA_LS SG_ 2149769216 WRSRDWhlDistVal "BrkSysVDA";
BA_REL_ "GenSigVDAFailResp" BU_SG_REL_ APA_LS SG_ 2149769216 WRSRDWhlDistVal 1;
BA_REL_ "GenSigVDAFailComment" BU_SG_REL_ APA_LS SG_ 2149769216 WRSRDWhlDistVal "BrkSysVDA";
BA_REL_ "GenSigVDAFailResp" BU_SG_REL_ APA_LS SG_ 2149769216 WRSRDWhlDistVal 1;
BA_REL_ "GenSigSuprvResp" BU_SG_REL_ APA_LS SG_ 2149769216 WRSRDWhlDistVal 1;
BA_REL_ "GenSigSuprvResp" BU_SG_REL_ APA_LS SG_ 2149769216 WRSRDWhlDistVal 1;
BA_REL_ "GenSigVDAFailComment" BU_SG_REL_ UPA_LS SG_ 2149769216 WRSRDWhlDistTmstm "BrkSysVDA";
BA_REL_ "GenSigVDAFailResp" BU_SG_REL_ UPA_LS SG_ 2149769216 WRSRDWhlDistTmstm 1;
BA_REL_ "GenSigSuprvResp" BU_SG_REL_ UPA_LS SG_ 2149769216 WRSRDWhlDistTmstm 1;
BA_REL_ "GenSigVDAFailComment" BU_SG_REL_ APA_LS SG_ 2149769216 WRSRDWhlDistTmstm "BrkSysVDA";
BA_REL_ "GenSigVDAFailResp" BU_SG_REL_ APA_LS SG_ 2149769216 WRSRDWhlDistTmstm 1;
BA_REL_ "GenSigVDAFailComment" BU_SG_REL_ APA_LS SG_ 2149769216 WRSRDWhlDistTmstm "BrkSysVDA";
BA_REL_ "GenSigVDAFailResp" BU_SG_REL_ APA_LS SG_ 2149769216 WRSRDWhlDistTmstm 1;
BA_REL_ "GenSigSuprvResp" BU_SG_REL_ APA_LS SG_ 2149769216 WRSRDWhlDistTmstm 1;
BA_REL_ "GenSigSuprvResp" BU_SG_REL_ APA_LS SG_ 2149769216 WRSRDWhlDistTmstm 1;
BA_REL_ "GenSigVDAFailComment" BU_SG_REL_ UPA_LS SG_ 2149769216 WRSRDWhlDistPlsCntr "BrkSysVDA";
BA_REL_ "GenSigVDAFailResp" BU_SG_REL_ UPA_LS SG_ 2149769216 WRSRDWhlDistPlsCntr 1;
BA_REL_ "GenSigSuprvResp" BU_SG_REL_ UPA_LS SG_ 2149769216 WRSRDWhlDistPlsCntr 1;
BA_REL_ "GenSigVDAFailComment" BU_SG_REL_ APA_LS SG_ 2149769216 WRSRDWhlDistPlsCntr "BrkSysVDA";
BA_REL_ "GenSigVDAFailResp" BU_SG_REL_ APA_LS SG_ 2149769216 WRSRDWhlDistPlsCntr 1;
BA_REL_ "GenSigVDAFailComment" BU_SG_REL_ APA_LS SG_ 2149769216 WRSRDWhlDistPlsCntr "BrkSysVDA";
BA_REL_ "GenSigVDAFailResp" BU_SG_REL_ APA_LS SG_ 2149769216 WRSRDWhlDistPlsCntr 1;
BA_REL_ "GenSigSuprvResp" BU_SG_REL_ APA_LS SG_ 2149769216 WRSRDWhlDistPlsCntr 1;
BA_REL_ "GenSigSuprvResp" BU_SG_REL_ APA_LS SG_ 2149769216 WRSRDWhlDistPlsCntr 1;
VAL_ 2158845952 ODIAC_DspMID 128 "Reserved" 64 "Reserved" 32 "OTIM" 16 "RearDisplayTwo" 8 "RearDisplayOne" 4 "AuxIP" 2 "CenterStack" 1 "IPC" ;
VAL_ 2158845952 ODIAC_DaTy 21 "Bitmap" 20 "DecimalShort" 19 "HoursOfDay" 18 "Character" 17 "Fuel Consumption Inverted" 16 "Fuel Consumption" 15 "Pressure" 14 "Temperature" 13 "Volume" 12 "DistanceShort" 11 "DistanceLong" 10 "BitmapId" 9 "TextId" 8 "Pictogram" 7 "List " 6 "Date" 5 "Time " 4 "Decimal" 3 "EnumerationValue" 2 "Integer" 1 "String" 0 "Speed" ;
VAL_ 2158886912 ODDLI_WrpArnd 1 "true" 0 "false" ;
VAL_ 2158886912 ODDLI_ReqType 0 "Subscribe: FU sends DynData back and then on change) " 1 "Unsubscribe: cancel previous Subscribe" ;
VAL_ 2158886912 ODDLI_ReqDir 1 "true" 0 "false" ;
VAL_ 2158886912 ODDLI_DspMID 128 "Reserved" 64 "Reserved" 32 "OTIM" 16 "RearDisplayTwo" 8 "RearDisplayOne" 4 "AuxIP" 2 "CenterStack" 1 "IPC" ;
VAL_ 2158886912 ODDLI_BckgndFlag 1 "Background response" 0 "Immediate response required" ;
VAL_ 2151366656 AxlLcksVDA 1 "Virtual Device Available" 0 "Virtual Device Unavailable" ;
VAL_ 2151366656 AxlLckUnavailIndReq 7 "Unused And Reserved 2" 6 "Unused And Reserved 1" 5 "Generic Unavailable" 4 "Not During Hill Decent" 3 "Speed Too High" 2 "Not In 4 WD Low" 1 "Rear Axle Not Locked" 0 "No Action" ;
VAL_ 2151366656 AxlLcksServIO 1 "true" 0 "false" ;
VAL_ 2151366656 RrAxlLckIO 1 "true" 0 "false" ;
VAL_ 2151366656 FrntAxlLckIO 1 "true" 0 "false" ;
VAL_ 2151366656 PrkBrkSwAtv 1 "true" 0 "false" ;
VAL_ 2149842944 AdptDrvrSeatStng 7 "Performance Mode 7" 6 "Performance Mode 6" 5 "Performance Mode 5" 4 "Performance Mode 4" 3 "Performance Mode 3" 2 "Performance Mode 2" 1 "Performance Mode 1" 0 "No Action" ;
VAL_ 2149842944 IMUProtLonAccV 1 "Invalid" 0 "Valid" ;
VAL_ 2149842944 VSELatAccV 1 "Invalid" 0 "Valid" ;
VAL_ 2149842944 StrWhAngV 1 "Invalid" 0 "Valid" ;
VAL_ 2149842944 TCSysAtv 1 "true" 0 "false" ;
VAL_ 2149842944 BrkSysAutBrkFld 1 "true" 0 "false" ;
VAL_ 2149842944 StrWhlAngSenCalStat 2 "Calibrated" 1 "Estimated" 0 "Unknown" ;
VAL_ 2149842944 VehStabEnhmntStat 4 "Not Ready" 3 "Warming Up" 2 "Fault" 1 "Active" 0 "Inactive" ;
VAL_ 2149842944 VehStabEnhmntMd 2 "Competitive" 1 "Normal" 0 "Off" ;
VAL_ 2149842944 VSEAct 1 "true" 0 "false" ;
VAL_ 2149842944 TCSysOpStat 2 "Fault" 1 "Active" 0 "Inactive" ;
VAL_ 2149842944 TCSysOpMd 2 "Off Road" 1 "Normal" 0 "Off" ;
VAL_ 2149842944 StWhAnVDA 1 "VirtualDeviceAvailable" 0 "VirtualDeviceUnavailable" ;
VAL_ 2159132672 ODIAR_DspMID 128 "Reserved" 64 "Reserved" 32 "OTIM" 16 "RearDisplayTwo" 8 "RearDisplayOne" 4 "AuxIP" 2 "CenterStack" 1 "IPC" ;
VAL_ 2159132672 ODIAR_DaTy 21 "Bitmap" 20 "DecimalShort" 19 "HoursOfDay" 18 "Character" 17 "Fuel Consumption Inverted" 16 "Fuel Consumption" 15 "Pressure" 14 "Temperature" 13 "Volume" 12 "DistanceShort" 11 "DistanceLong" 10 "BitmapId" 9 "TextId" 8 "Pictogram" 7 "List " 6 "Date" 5 "Time " 4 "Decimal" 3 "EnumerationValue" 2 "Integer" 1 "String" 0 "Speed" ;
VAL_ 2158960640 ODIIC_ODIInd9 1 "true" 0 "false" ;
VAL_ 2158960640 ODIIC_ODIInd8 1 "true" 0 "false" ;
VAL_ 2158960640 ODIIC_ODIInd7 1 "true" 0 "false" ;
VAL_ 2158960640 ODIIC_ODIInd6 1 "true" 0 "false" ;
VAL_ 2158960640 ODIIC_ODIInd56 1 "true" 0 "false" ;
VAL_ 2158960640 ODIIC_ODIInd55 1 "true" 0 "false" ;
VAL_ 2158960640 ODIIC_ODIInd54 1 "true" 0 "false" ;
VAL_ 2158960640 ODIIC_ODIInd53 1 "true" 0 "false" ;
VAL_ 2158960640 ODIIC_ODIInd52 1 "true" 0 "false" ;
VAL_ 2158960640 ODIIC_ODIInd51 1 "true" 0 "false" ;
VAL_ 2158960640 ODIIC_ODIInd50 1 "true" 0 "false" ;
VAL_ 2158960640 ODIIC_ODIInd5 1 "true" 0 "false" ;
VAL_ 2158960640 ODIIC_ODIInd49 1 "true" 0 "false" ;
VAL_ 2158960640 ODIIC_ODIInd48 1 "true" 0 "false" ;
VAL_ 2158960640 ODIIC_ODIInd47 1 "true" 0 "false" ;
VAL_ 2158960640 ODIIC_ODIInd46 1 "true" 0 "false" ;
VAL_ 2158960640 ODIIC_ODIInd45 1 "true" 0 "false" ;
VAL_ 2158960640 ODIIC_ODIInd44 1 "true" 0 "false" ;
VAL_ 2158960640 ODIIC_ODIInd43 1 "true" 0 "false" ;
VAL_ 2158960640 ODIIC_ODIInd42 1 "true" 0 "false" ;
VAL_ 2158960640 ODIIC_ODIInd41 1 "true" 0 "false" ;
VAL_ 2158960640 ODIIC_ODIInd40 1 "true" 0 "false" ;
VAL_ 2158960640 ODIIC_ODIInd4 1 "true" 0 "false" ;
VAL_ 2158960640 ODIIC_ODIInd39 1 "true" 0 "false" ;
VAL_ 2158960640 ODIIC_ODIInd38 1 "true" 0 "false" ;
VAL_ 2158960640 ODIIC_ODIInd37 1 "true" 0 "false" ;
VAL_ 2158960640 ODIIC_ODIInd36 1 "true" 0 "false" ;
VAL_ 2158960640 ODIIC_ODIInd35 1 "true" 0 "false" ;
VAL_ 2158960640 ODIIC_ODIInd34 1 "true" 0 "false" ;
VAL_ 2158960640 ODIIC_ODIInd33 1 "true" 0 "false" ;
VAL_ 2158960640 ODIIC_ODIInd32 1 "true" 0 "false" ;
VAL_ 2158960640 ODIIC_ODIInd31 1 "true" 0 "false" ;
VAL_ 2158960640 ODIIC_ODIInd30 1 "true" 0 "false" ;
VAL_ 2158960640 ODIIC_ODIInd3 1 "true" 0 "false" ;
VAL_ 2158960640 ODIIC_ODIInd29 1 "true" 0 "false" ;
VAL_ 2158960640 ODIIC_ODIInd28 1 "true" 0 "false" ;
VAL_ 2158960640 ODIIC_ODIInd27 1 "true" 0 "false" ;
VAL_ 2158960640 ODIIC_ODIInd26 1 "true" 0 "false" ;
VAL_ 2158960640 ODIIC_ODIInd25 1 "true" 0 "false" ;
VAL_ 2158960640 ODIIC_ODIInd24 1 "true" 0 "false" ;
VAL_ 2158960640 ODIIC_ODIInd23 1 "true" 0 "false" ;
VAL_ 2158960640 ODIIC_ODIInd22 1 "true" 0 "false" ;
VAL_ 2158960640 ODIIC_ODIInd21 1 "true" 0 "false" ;
VAL_ 2158960640 ODIIC_ODIInd20 1 "true" 0 "false" ;
VAL_ 2158960640 ODIIC_ODIInd2 1 "true" 0 "false" ;
VAL_ 2158960640 ODIIC_ODIInd19 1 "true" 0 "false" ;
VAL_ 2158960640 ODIIC_ODIInd18 1 "true" 0 "false" ;
VAL_ 2158960640 ODIIC_ODIInd17 1 "true" 0 "false" ;
VAL_ 2158960640 ODIIC_ODIInd16 1 "true" 0 "false" ;
VAL_ 2158960640 ODIIC_ODIInd15 1 "true" 0 "false" ;
VAL_ 2158960640 ODIIC_ODIInd14 1 "true" 0 "false" ;
VAL_ 2158960640 ODIIC_ODIInd13 1 "true" 0 "false" ;
VAL_ 2158960640 ODIIC_ODIInd12 1 "true" 0 "false" ;
VAL_ 2158960640 ODIIC_ODIInd11 1 "true" 0 "false" ;
VAL_ 2158960640 ODIIC_ODIInd10 1 "true" 0 "false" ;
VAL_ 2158960640 ODIIC_ODIInd1 1 "true" 0 "false" ;
VAL_ 2158952448 ODDMR_ReqType 0 "Subscribe: FU sends DynData back and then on change) " 1 "Unsubscribe: cancel previous Subscribe" ;
VAL_ 2158952448 ODDMR_DispMID 128 "Reserved" 64 "Reserved" 32 "OTIM" 16 "RearDisplayTwo" 8 "RearDisplayOne" 4 "AuxIP" 2 "CenterStack" 1 "IPC" ;
VAL_ 2158952448 ODDMR_DataID2Vld 1 "true" 0 "false" ;
VAL_ 2158952448 ODDMR_DataID3Vld 1 "true" 0 "false" ;
VAL_ 2158952448 ODDMR_DataID4Vld 1 "true" 0 "false" ;
VAL_ 2158952448 ODDMR_DataID5Vld 1 "true" 0 "false" ;
VAL_ 2158944256 ODDLR_WrpArnd 1 "true" 0 "false" ;
VAL_ 2158944256 ODDLR_ReqType 0 "Subscribe: FU sends DynData back and then on change) " 1 "Unsubscribe: cancel previous Subscribe" ;
VAL_ 2158944256 ODDLR_ReqDir 1 "true" 0 "false" ;
VAL_ 2158944256 ODDLR_DspMID 128 "Reserved" 64 "Reserved" 32 "OTIM" 16 "RearDisplayTwo" 8 "RearDisplayOne" 4 "AuxIP" 2 "CenterStack" 1 "IPC" ;
VAL_ 2158944256 ODDLR_BckgndFlag 1 "Background response" 0 "Immediate response required" ;
VAL_ 2158927872 ODDC_InvldData 1 "true" 0 "false" ;
VAL_ 2158927872 ODDC_DataType 21 "Bitmap" 20 "DecimalShort" 19 "HoursOfDay" 18 "Character" 17 "Fuel Consumption Inverted" 16 "Fuel Consumption" 15 "Pressure" 14 "Temperature" 13 "Volume" 12 "DistanceShort" 11 "DistanceLong" 10 "BitmapId" 9 "TextId" 8 "Pictogram" 7 "List " 6 "Date" 5 "Time " 4 "Decimal" 3 "EnumerationValue" 2 "Integer" 1 "String" 0 "Speed" ;
VAL_ 2152022016 ASVSC_ReqEnbld 1 "true" 0 "false" ;
VAL_ 2152022016 AudSelctdSrcReq 31 "Unused and Reserved14" 30 "Unused and Reserved13" 29 "Unused and Reserved12" 28 "Unused and Reserved11" 27 "Unused and Reserved10" 26 "Unused and Reserved9" 25 "Unused and Reserved8" 24 "Unused and Reserved7" 23 "Unused and Reserved6" 22 "Unused and Reserved5" 21 "Unused and Reserved4" 20 "Unused and Reserved3" 19 "Unused and Reserved2" 18 "Unused and Reserved1" 17 "Android Auto" 16 "Apple CarPlay" 15 "SD" 14 "USB" 13 "RSI2" 12 "RSI1" 11 "Internet App Audio" 10 "LVM Stereo Audio" 9 "Audio Disk Player" 8 "AUX" 7 "Bluetooth" 6 "IPOD" 5 "MediaPlayer" 4 "DAB" 3 "XM" 2 "FM" 1 "AM" 0 "No Action" ;
VAL_ 2152022016 InfMdStRsp 7 "Data Unavailable" 6 "Cancel Request" 5 "OTA Transfer Failed" 4 "Data Transfer Failed" 3 "Data Transfer Complete" 2 "Not Ready" 1 "Ready" 0 "No Action" ;
VAL_ 2151989248 InfMdStReq 7 "Data Unavailable" 6 "Cancel Request" 5 "OTA Transfer Failed" 4 "Data Transfer Failed" 3 "Data Transfer Complete" 2 "Not Ready" 1 "Ready" 0 "No Action" ;
VAL_ 2151972864 LnchCtrlWhlSlpReq 31 "Unused and Reserved 10" 30 "Unused and Reserved 9" 29 "Unused and Reserved 8" 28 "Unused and Reserved 7" 27 "Unused and Reserved 6" 26 "Unused and Reserved 5" 25 "Unused and Reserved 4" 24 "Unused and Reserved 3" 23 "Unused and Reserved 2" 22 "Unused and Reserved 1" 21 "Fifteen Percent" 20 "Fourteen And A Half Percent" 19 "Fourteen Percent" 18 "Thirteen And A Half Percent" 17 "Thirteen Percent" 16 "Twelve And A Half Percent" 15 "Twelve Percent" 14 "Eleven And a Half Percent" 13 "Eleven Percent" 12 "Ten And A Half Percent" 11 "Ten Percent" 10 "Nine And A Half Percent" 9 "Nine Percent" 8 "Eight And A Half Percent" 7 "Eight Percent" 6 "Seven And A Half Percent" 5 "Seven Percent" 4 "Six And A Half Percent" 3 "Six Percent" 2 "Five And A Half Percent" 1 "Five Percent" 0 "No Action" ;
VAL_ 2151972864 LnchCtrlMdReq 3 "Burn Out" 2 "Custom" 1 "Automatic" 0 "No Action" ;
VAL_ 2151972864 LnchCtrlEngRPMReq 63 "Unused and Reserved 30" 62 "Unused and Reserved 29" 61 "Unused and Reserved 28" 60 "Unused and Reserved 27" 59 "Unused and Reserved 26" 58 "Unused and Reserved 25" 57 "Unused and Reserved 24" 56 "Unused and Reserved 23" 55 "Unused and Reserved 22" 54 "Unused and Reserved 21" 53 "Unused and Reserved 20" 52 "Unused and Reserved 19" 51 "Unused and Reserved 18" 50 "Unused and Reserved 17" 49 "Unused and Reserved 16" 48 "Unused and Reserved 15" 47 "Unused and Reserved 14" 46 "Unused and Reserved 13" 45 "Unused and Reserved 12" 44 "Unused and Reserved 11" 43 "Unused and Reserved 10" 42 "Unused and Reserved 9" 41 "Unused and Reserved 8" 40 "Unused and Reserved 7" 39 "Unused and Reserved 6" 38 "Unused and Reserved 5" 37 "Unused and Reserved 4" 36 "Unused and Reserved 3" 35 "Unused and Reserved 2" 34 "Unused and Reserved 1" 33 "4000" 32 "3900" 31 "3800" 30 "3700" 29 "3600" 28 "3500" 27 "3400" 26 "3300" 25 "3200" 24 "3100" 23 "3000" 22 "2900" 21 "2800" 20 "2700" 19 "2600" 18 "2500" 17 "2400" 16 "2300" 15 "2200" 14 "2100" 13 "2000" 12 "1900" 11 "1800" 10 "1700" 9 "1600" 8 "1500" 7 "1400" 6 "1300" 5 "1200" 4 "1100" 3 "1000" 2 "900" 1 "800" 0 "No Action" ;
VAL_ 2151972864 VehFuelRngCalcV 1 "Invalid" 0 "Valid" ;
VAL_ 2151972864 FuelLvlLwIO 1 "true" 0 "false" ;
VAL_ 2154528768 WhlGrndVlctyRtNnDrvnV 1 "Invalid" 0 "Valid" ;
VAL_ 2154528768 WhlGrndVlctyRtDrvnV 1 "Invalid" 0 "Valid" ;
VAL_ 2154528768 WhlGrndVlctyLftNnDrvnV 1 "Invalid" 0 "Valid" ;
VAL_ 2154528768 WhlGrndVlctyLftDrvnV 1 "Invalid" 0 "Valid" ;
VAL_ 2150916096 PrkHtrCoolntTempM 1 "Use Data" 0 "Don't Use Data" ;
VAL_ 2150916096 PrkHtrPrhtAch 1 "true" 0 "false" ;
VAL_ 2150916096 PrkHtrFlCnsmdRolCntV 1 "Invalid" 0 "Valid" ;
VAL_ 2150916096 PrkHtrFlCsmdRlCntRsOc 1 "true" 0 "false" ;
VAL_ 2150916096 PrkHtrCoolntTempV 1 "Invalid" 0 "Valid" ;
VAL_ 2150916096 ClntCircPmpAct 1 "true" 0 "false" ;
VAL_ 2150916096 PrkHtrAtv 1 "true" 0 "false" ;
VAL_ 2150367232 LrnEnvIdSt 1 "Info_valid" 0 "No_info" ;
VAL_ 2150367232 ImoIdSt 1 "Info valid" 0 "No info" ;
VAL_ 2150621184 KSARUID8 1 "Present" 0 "Not Present" ;
VAL_ 2150621184 KSARUID7 1 "Present" 0 "Not Present" ;
VAL_ 2150621184 KSARUID6 1 "Present" 0 "Not Present" ;
VAL_ 2150621184 KSARUID5 1 "Present" 0 "Not Present" ;
VAL_ 2150621184 KSARUID4 1 "Present" 0 "Not Present" ;
VAL_ 2150621184 KSARUID3 1 "Present" 0 "Not Present" ;
VAL_ 2150621184 KSARUID2 1 "Present" 0 "Not Present" ;
VAL_ 2150621184 KSARUID1 1 "Present" 0 "Not Present" ;
VAL_ 2154061824 WndOprAlwd 1 "true" 0 "false" ;
VAL_ 2154061824 RrDrUnlckIO 1 "true" 0 "false" ;
VAL_ 2154061824 RmtWndMvmntAtv 1 "true" 0 "false" ;
VAL_ 2154061824 RRWndNtNrmIndOn 1 "true" 0 "false" ;
VAL_ 2154061824 RLWndNtNrmIndOn 1 "true" 0 "false" ;
VAL_ 2154061824 DrWndNtNrmIndOn 1 "true" 0 "false" ;
VAL_ 2154061824 PsWndNtNrmIndOn 1 "true" 0 "false" ;
VAL_ 2154512384 RrClosRelSwActV 1 "Invalid" 0 "Valid" ;
VAL_ 2154512384 RrClosRelSwAct 1 "true" 0 "false" ;
VAL_ 2155347968 DrvrStPerfMdCsCrStVal 7 "Auto" 6 "Performance Mode 6" 5 "Performance Mode 5" 4 "Performance Mode 4" 3 "Performance Mode 3" 2 "Performance Mode 2" 1 "Performance Mode 1" 0 "No Action" ;
VAL_ 2155347968 DrvrStPerfMdCsStAvl 1 "true" 0 "false" ;
VAL_ 2155347968 ACCPerfMdCsCrStVal 7 "Auto" 6 "Performance Mode 6" 5 "Performance Mode 5" 4 "Performance Mode 4" 3 "Performance Mode 3" 2 "Performance Mode 2" 1 "Performance Mode 1" 0 "No Action" ;
VAL_ 2155347968 ACCPerfMdCsStAvl 1 "true" 0 "false" ;
VAL_ 2155347968 VehRollAngleV 1 "Invalid" 0 "Valid" ;
VAL_ 2155347968 ActVbnCtrlMlfIO 1 "true" 0 "false" ;
VAL_ 2155347968 HillDesCtrlRedVehSpIO 1 "true" 0 "false" ;
VAL_ 2155347968 FourWhlDrvIndReq 0 "No Indication" 1 "Indication 1" 2 "Indication 2" 3 "Indication 3" 4 "Indication 4" 5 "Indication 5" 6 "Indication 6" 7 "Indication 7" ;
VAL_ 2155347968 PedtrnProtVDA 1 "VirtualDeviceAvailable" 0 "VirtualDeviceUnavailable" ;
VAL_ 2155347968 EngRecDwnshftIO 1 "true" 0 "false" ;
VAL_ 2155347968 AppCltchAutSrtIO 1 "true" 0 "false" ;
VAL_ 2155347968 CPSUnblIO 1 "true" 0 "false" ;
VAL_ 2155347968 StBltTgtSetAvl 1 "true" 0 "false" ;
VAL_ 2155347968 StBltTgtCrtSetVal 0 "No Action" 1 "Low" 2 "Normal" 3 "Performance" 4 "Locked" ;
VAL_ 2155347968 PedtrnProtSysDisbld 1 "true" 0 "false" ;
VAL_ 2155347968 PedtrnProtSysDpl 1 "true" 0 "false" ;
VAL_ 2155347968 SrvPedtrnProtSysIO 1 "true" 0 "false" ;
VAL_ 2155347968 CPSOffIO 1 "true" 0 "false" ;
VAL_ 2155347968 SecAxlTmpInhIO 1 "true" 0 "false" ;
VAL_ 2155347968 CPSFldIO 1 "true" 0 "false" ;
VAL_ 2155347968 CPSAlrtOnlIO 1 "true" 0 "false" ;
VAL_ 2155347968 RrAxlTmpInhIO 1 "true" 0 "false" ;
VAL_ 2155347968 TirePrsLowIO 1 "true" 0 "false" ;
VAL_ 2155347968 EPBSysStatIndReq 3 "Flash Rate 2 Indication" 2 "Flash Rate 1 Indication" 1 "Continuous Indication" 0 "No Indication" ;
VAL_ 2155347968 EngOilStrvtnIO 1 "true" 0 "false" ;
VAL_ 2155347968 SrvSuspSysIO 1 "true" 0 "false" ;
VAL_ 2155347968 ServAdpCrsCtrlIndOn 1 "true" 0 "false" ;
VAL_ 2155347968 EngRecmndUpshftIO 1 "true" 0 "false" ;
VAL_ 2155347968 BrkSysMalFuncIndOn 1 "true" 0 "false" ;
VAL_ 2155347968 SecAxlNonEmMalfIO 1 "true" 0 "false" ;
VAL_ 2155347968 BrkFldLvlLw 1 "true" 0 "false" ;
VAL_ 2155347968 ACCUnavlbleDTWthrIO 1 "true" 0 "false" ;
VAL_ 2155347968 ACCTmpUnavlbleIO 1 "true" 0 "false" ;
VAL_ 2155347968 EngEmsRelMalfIndReq 4 "Flashing 0.5 Hertz Indication" 3 "Flashing 2 Hertz Indication" 2 "Flashing 1 Hertz Indication" 1 "No Indication" 0 "Continuous Indication" ;
VAL_ 2155347968 DrShftCntrlReqDndIO 1 "true" 0 "false" ;
VAL_ 2155347968 BrkPadWrnIO 1 "true" 0 "false" ;
VAL_ 2155347968 RrAxlMalfIO 1 "true" 0 "false" ;
VAL_ 2155347968 EPBSysWrnIndReq 3 "Flash Rate #2 Indication" 2 "Flash Rate #1 Indication" 1 "Continuous Indication" 0 "No Indication" ;
VAL_ 2155347968 CompOvrhtIndOn 1 "true" 0 "false" ;
VAL_ 2155347968 BrkFldLvlLwV 1 "Invalid" 0 "Valid" ;
VAL_ 2155347968 ACCSnsClnRqdIO 1 "true" 0 "false" ;
VAL_ 2155347968 TrnsSkpShftIO 1 "true" 0 "false" ;
VAL_ 2149777408 WRSLNDWhlRotStRst 1 "true" 0 "false" ;
VAL_ 2149777408 WRSLNDWhlDistVal 1 "Invalid" 0 "Valid" ;
VAL_ 2149777408 WRSRNDWhlRotStRst 1 "true" 0 "false" ;
VAL_ 2149777408 WRSRNDWhlDistVal 1 "Invalid" 0 "Valid" ;
VAL_ 2149769216 WRSLDWhlDistVal 1 "Invalid" 0 "Valid" ;
VAL_ 2149769216 WRSLDWhlRotStatRst 1 "true" 0 "false" ;
VAL_ 2149769216 WRSRDWhlRotStatRst 1 "true" 0 "false" ;
VAL_ 2149769216 WRSRDWhlDistVal 1 "Invalid" 0 "Valid" ;
SIG_GROUP_ 2158936064 ODIEnmDynData 1 : ODIEDD_Data18Value ODIEDD_Data17Value ODIEDD_Data16Value ODIEDD_Data15Value ODIEDD_Data14Value ODIEDD_Data13Value ODIEDD_Data12Value ODIEDD_Data11Value ODIEDD_Data10Value ODIEDD_Data9Value ODIEDD_Data8Value ODIEDD_Data7Value ODIEDD_Data6Value ODIEDD_Data5Value ODIEDD_Data4Value ODIEDD_Data3Value ODIEDD_Data2Value ODIEDD_Data1Value ODIEDD_FUCID;
SIG_GROUP_ 2158845952 ODIActn_CntrStck 1 : ODIAC_FUCID ODIAC_DspMID ODIAC_DaTy ODIAC_ActnVal ODIAC_ActnID;
SIG_GROUP_ 2158886912 ODIDynDataLstRq_IPC 1 : ODDLI_SubIdReqM ODDLI_WrpArnd ODDLI_ReqType ODDLI_ReqDir ODDLI_NmEntries ODDLI_Idx ODDLI_FUCID ODDLI_DspMID ODDLI_DataId ODDLI_BckgndFlag;
SIG_GROUP_ 2159132672 ODIActn_RSD 1 : ODIAR_FUCID ODIAR_DspMID ODIAR_DaTy ODIAR_ActnVal ODIAR_ActnID;
SIG_GROUP_ 2158960640 ODIInd_CntrStck 1 : ODIIC_FUCID ODIIC_ODIInd9 ODIIC_ODIInd8 ODIIC_ODIInd7 ODIIC_ODIInd6 ODIIC_ODIInd56 ODIIC_ODIInd55 ODIIC_ODIInd54 ODIIC_ODIInd53 ODIIC_ODIInd52 ODIIC_ODIInd51 ODIIC_ODIInd50 ODIIC_ODIInd5 ODIIC_ODIInd49 ODIIC_ODIInd48 ODIIC_ODIInd47 ODIIC_ODIInd46 ODIIC_ODIInd45 ODIIC_ODIInd44 ODIIC_ODIInd43 ODIIC_ODIInd42 ODIIC_ODIInd41 ODIIC_ODIInd40 ODIIC_ODIInd4 ODIIC_ODIInd39 ODIIC_ODIInd38 ODIIC_ODIInd37 ODIIC_ODIInd36 ODIIC_ODIInd35 ODIIC_ODIInd34 ODIIC_ODIInd33 ODIIC_ODIInd32 ODIIC_ODIInd31 ODIIC_ODIInd30 ODIIC_ODIInd3 ODIIC_ODIInd29 ODIIC_ODIInd28 ODIIC_ODIInd27 ODIIC_ODIInd26 ODIIC_ODIInd25 ODIIC_ODIInd24 ODIIC_ODIInd23 ODIIC_ODIInd22 ODIIC_ODIInd21 ODIIC_ODIInd20 ODIIC_ODIInd2 ODIIC_ODIInd19 ODIIC_ODIInd18 ODIIC_ODIInd17 ODIIC_ODIInd16 ODIIC_ODIInd15 ODIIC_ODIInd14 ODIIC_ODIInd13 ODIIC_ODIInd12 ODIIC_ODIInd11 ODIIC_ODIInd10 ODIIC_ODIInd1;
SIG_GROUP_ 2158977024 ODIEvntPkt_CntrStck 1 : ODIEC_MultiFrRetCh ODIEC_FUCID ODIEC_EvID;
SIG_GROUP_ 2158952448 ODIDynDataMltRq_RSD 1 : ODDMR_ReqType ODDMR_FUCID ODDMR_DispMID ODDMR_DataID2Vld ODDMR_DataID2 ODDMR_DataID3Vld ODDMR_DataID3 ODDMR_DataID1 ODDMR_DataID4Vld ODDMR_DataID4 ODDMR_DataID5Vld ODDMR_DataID5;
SIG_GROUP_ 2158944256 ODIDynDataLstRq_RSD 1 : ODDLR_SubIdReqM ODDLR_WrpArnd ODDLR_ReqType ODDLR_ReqDir ODDLR_NmEntries ODDLR_Idx ODDLR_FUCID ODDLR_DspMID ODDLR_DataId ODDLR_BckgndFlag;
SIG_GROUP_ 2158927872 ODIDynData_CntrStck 1 : ODDC_InvldData ODDC_FUCID ODDC_DataVal ODDC_DataType ODDC_DataId;
SIG_GROUP_ 2152022016 AudSysVolSetCtrl 1 : ASVSC_ReqEnbld ASVSC_VolReq;
SIG_GROUP_ 2150621184 KylsStrAuthRslt 1 : KSARUID8 KSARUID7 KSARUID6 KSARUID5 KSARUID4 KSARUID3 KSARUID2 KSARUID1;
SIG_GROUP_ 2149777408 WhlRotStatLftNDrvn 1 : WRSLNDWhlDisTpRC WRSLNDWhlRotStRst WRSLNDWhlDistVal WRSLNDWhlDistTstm WRSLNDWhlDistPCntr WRSLNDSeqNum;
SIG_GROUP_ 2149777408 WhlRotStatRghtNDrvn 1 : WRSRNDWhlDisTpRC WRSRNDWhlRotStRst WRSRNDWhlDistVal WRSRNDWhlDistTstm WRSRNDWhlDistPCntr WRSRNDSeqNum;
SIG_GROUP_ 2149769216 WhlRotatStatLftDrvn 1 : WRSLDWhlDisTpRC WRSLDSeqNum WRSLDWhlDistVal WRSLDWhlRotStatRst WRSLDWhlDistTmstm WRSLDWhlDistPlsCntr;
SIG_GROUP_ 2149769216 WhlRotatStatRtDrvn 1 : WRSRDWhlDisTpRC WRSRDSeqNum WRSRDWhlRotStatRst WRSRDWhlDistVal WRSRDWhlDistTmstm WRSRDWhlDistPlsCntr;
